VERSION "created by canmatrix"

NS_ :

BS_:

BU_: RadarFrontCenter DASy MPC3

BO_ 250 VFC_TrafficSign12: 48 MPC3
 SG_ VFC_TS12_CRC : 0|16@1+ (1,0) [0|65535] ""  DASy
 SG_ VFC_TS12_AliveCtr : 16|8@1+ (1,0) [0|255] ""  DASy
 SG_ VFC_TS12_ProtBlockCtr : 24|4@1+ (1,0) [0|15] ""  DASy
 SG_ VFC_TS12_ProtOrderIndex : 32|4@1+ (1,0) [0|15] ""  DASy
 SG_ VFC_TS12_ID : 40|8@1+ (1,0) [1|255] ""  DASy
 SG_ VFC_TS12_Class : 48|8@1+ (1,0) [0|206] ""  DASy
 SG_ VFC_TS12_TSProb : 56|6@1+ (2,0) [0|100] "%"  DASy
 SG_ VFC_TS12_Dx : 64|9@1+ (0.2,0) [0|102.2] "m"  DASy
 SG_ VFC_TS12_Dy : 80|8@1+ (0.2,-25.6) [-25.6|25.4] "m"  DASy
 SG_ VFC_TS12_Dz : 88|6@1+ (0.2,0) [0|12.6] "m"  DASy
 SG_ VFC_TS12_DxStdDev : 96|8@1+ (0.25,0) [0|63.75] "m"  DASy
 SG_ VFC_TS12_DyStdDev : 104|7@1+ (0.1,0) [0|12.7] "m"  DASy
 SG_ VFC_TS12_DzStdDev : 112|6@1+ (0.1,0) [0|6.3] "m"  DASy
 SG_ VFC_TS12_Width : 120|7@1+ (0.1,0) [0|12.7] "m"  DASy
 SG_ VFC_TS12_Height : 128|6@1+ (0.1,0) [0|6.3] "m"  DASy
 SG_ VFC_TS12_EmbedFlag : 136|3@1+ (1,0) [0|7] ""  DASy
 SG_ VFC_TS12_Quality : 139|1@1+ (1,0) [0|1] ""  DASy
 SG_ VFC_TS12_VMS : 140|1@1+ (1,0) [0|1] ""  DASy
 SG_ VFC_TS12_Stable : 141|1@1+ (1,0) [0|1] ""  DASy
 SG_ VFC_TS12_VehicleSticker : 142|1@1+ (1,0) [0|1] ""  DASy
 SG_ VFC_TS12_InternalTrack : 143|1@1+ (1,0) [0|1] ""  DASy
 SG_ VFC_TS12_ValidLanes : 144|5@1+ (1,0) [0|31] ""  DASy
 SG_ VFC_TS12_ValidDay : 152|7@1+ (1,0) [0|127] ""  DASy
 SG_ VFC_TS12_ValidTimeRange1Start : 160|7@1+ (15,0) [0|1440] "min"  DASy
 SG_ VFC_TS12_ValidTimeRange1End : 168|7@1+ (15,0) [0|1440] "min"  DASy
 SG_ VFC_TS12_ValidTimeRange2Start : 176|7@1+ (15,0) [0|1440] "min"  DASy
 SG_ VFC_TS12_ValidTimeRange2End : 184|7@1+ (15,0) [0|1440] "min"  DASy
 SG_ VFC_TS12_ValidInDist : 192|10@1+ (10,0) [0|10230] "m"  DASy
 SG_ VFC_TS12_ValidDist : 208|10@1+ (10,0) [0|10230] "m"  DASy
 SG_ VFC_TS12_AddTSCount : 232|3@1+ (1,0) [0|6] ""  DASy
 SG_ VFC_TS12_AddTS1Class : 240|8@1+ (1,0) [0|68] ""  DASy
 SG_ VFC_TS12_AddTS1Prob : 248|6@1+ (2,0) [0|100] "%"  DASy
 SG_ VFC_TS12_AddTS1Quality : 254|1@1+ (1,0) [0|1] ""  DASy
 SG_ VFC_TS12_AddTS1VMS : 255|1@1+ (1,0) [0|1] ""  DASy
 SG_ VFC_TS12_AddTS2Class : 256|8@1+ (1,0) [0|68] ""  DASy
 SG_ VFC_TS12_AddTS2Prob : 264|6@1+ (2,0) [0|100] "%"  DASy
 SG_ VFC_TS12_AddTS2Quality : 270|1@1+ (1,0) [0|1] ""  DASy
 SG_ VFC_TS12_AddTS2VMS : 271|1@1+ (1,0) [0|1] ""  DASy
 SG_ VFC_TS12_AddTS3Class : 272|8@1+ (1,0) [0|68] ""  DASy
 SG_ VFC_TS12_AddTS3Prob : 280|6@1+ (2,0) [0|100] "%"  DASy
 SG_ VFC_TS12_AddTS3Quality : 286|1@1+ (1,0) [0|1] ""  DASy
 SG_ VFC_TS12_AddTS3VMS : 287|1@1+ (1,0) [0|1] ""  DASy
 SG_ VFC_TS12_AddTS4Class : 288|8@1+ (1,0) [0|68] ""  DASy
 SG_ VFC_TS12_AddTS4Prob : 296|6@1+ (2,0) [0|100] "%"  DASy
 SG_ VFC_TS12_AddTS4Quality : 302|1@1+ (1,0) [0|1] ""  DASy
 SG_ VFC_TS12_AddTS4VMS : 303|1@1+ (1,0) [0|1] ""  DASy
 SG_ VFC_TS12_AddTS5Class : 304|8@1+ (1,0) [0|68] ""  DASy
 SG_ VFC_TS12_AddTS5Prob : 312|6@1+ (2,0) [0|100] "%"  DASy
 SG_ VFC_TS12_AddTS5Quality : 318|1@1+ (1,0) [0|1] ""  DASy
 SG_ VFC_TS12_AddTS5VMS : 319|1@1+ (1,0) [0|1] ""  DASy
 SG_ VFC_TS12_AddTS6Class : 320|8@1+ (1,0) [0|68] ""  DASy
 SG_ VFC_TS12_AddTS6Prob : 328|6@1+ (2,0) [0|100] "%"  DASy
 SG_ VFC_TS12_AddTS6Quality : 334|1@1+ (1,0) [0|1] ""  DASy
 SG_ VFC_TS12_AddTS6VMS : 335|1@1+ (1,0) [0|1] ""  DASy
 SG_ VFC_TS12_FV : 359|8@0+ (1,0) [0|255] ""  DASy
 SG_ VFC_TS12_MAC : 367|24@0+ (1,0) [0|16777215] ""  DASy

BO_ 251 VFC_TrafficSign13: 48 MPC3
 SG_ VFC_TS13_CRC : 0|16@1+ (1,0) [0|65535] ""  DASy
 SG_ VFC_TS13_AliveCtr : 16|8@1+ (1,0) [0|255] ""  DASy
 SG_ VFC_TS13_ProtBlockCtr : 24|4@1+ (1,0) [0|15] ""  DASy
 SG_ VFC_TS13_ProtOrderIndex : 32|4@1+ (1,0) [0|15] ""  DASy
 SG_ VFC_TS13_ID : 40|8@1+ (1,0) [1|255] ""  DASy
 SG_ VFC_TS13_Class : 48|8@1+ (1,0) [0|206] ""  DASy
 SG_ VFC_TS13_TSProb : 56|6@1+ (2,0) [0|100] "%"  DASy
 SG_ VFC_TS13_Dx : 64|9@1+ (0.2,0) [0|102.2] "m"  DASy
 SG_ VFC_TS13_Dy : 80|8@1+ (0.2,-25.6) [-25.6|25.4] "m"  DASy
 SG_ VFC_TS13_Dz : 88|6@1+ (0.2,0) [0|12.6] "m"  DASy
 SG_ VFC_TS13_DxStdDev : 96|8@1+ (0.25,0) [0|63.75] "m"  DASy
 SG_ VFC_TS13_DyStdDev : 104|7@1+ (0.1,0) [0|12.7] "m"  DASy
 SG_ VFC_TS13_DzStdDev : 112|6@1+ (0.1,0) [0|6.3] "m"  DASy
 SG_ VFC_TS13_Width : 120|7@1+ (0.1,0) [0|12.7] "m"  DASy
 SG_ VFC_TS13_Height : 128|6@1+ (0.1,0) [0|6.3] "m"  DASy
 SG_ VFC_TS13_EmbedFlag : 136|3@1+ (1,0) [0|7] ""  DASy
 SG_ VFC_TS13_Quality : 139|1@1+ (1,0) [0|1] ""  DASy
 SG_ VFC_TS13_VMS : 140|1@1+ (1,0) [0|1] ""  DASy
 SG_ VFC_TS13_Stable : 141|1@1+ (1,0) [0|1] ""  DASy
 SG_ VFC_TS13_VehicleSticker : 142|1@1+ (1,0) [0|1] ""  DASy
 SG_ VFC_TS13_InternalTrack : 143|1@1+ (1,0) [0|1] ""  DASy
 SG_ VFC_TS13_ValidLanes : 144|5@1+ (1,0) [0|31] ""  DASy
 SG_ VFC_TS13_ValidDay : 152|7@1+ (1,0) [0|127] ""  DASy
 SG_ VFC_TS13_ValidTimeRange1Start : 160|7@1+ (15,0) [0|1440] "min"  DASy
 SG_ VFC_TS13_ValidTimeRange1End : 168|7@1+ (15,0) [0|1440] "min"  DASy
 SG_ VFC_TS13_ValidTimeRange2Start : 176|7@1+ (15,0) [0|1440] "min"  DASy
 SG_ VFC_TS13_ValidTimeRange2End : 184|7@1+ (15,0) [0|1440] "min"  DASy
 SG_ VFC_TS13_ValidInDist : 192|10@1+ (10,0) [0|10230] "m"  DASy
 SG_ VFC_TS13_ValidDist : 208|10@1+ (10,0) [0|10230] "m"  DASy
 SG_ VFC_TS13_AddTSCount : 232|3@1+ (1,0) [0|6] ""  DASy
 SG_ VFC_TS13_AddTS1Class : 240|8@1+ (1,0) [0|68] ""  DASy
 SG_ VFC_TS13_AddTS1Prob : 248|6@1+ (2,0) [0|100] "%"  DASy
 SG_ VFC_TS13_AddTS1Quality : 254|1@1+ (1,0) [0|1] ""  DASy
 SG_ VFC_TS13_AddTS1VMS : 255|1@1+ (1,0) [0|1] ""  DASy
 SG_ VFC_TS13_AddTS2Class : 256|8@1+ (1,0) [0|68] ""  DASy
 SG_ VFC_TS13_AddTS2Prob : 264|6@1+ (2,0) [0|100] "%"  DASy
 SG_ VFC_TS13_AddTS2Quality : 270|1@1+ (1,0) [0|1] ""  DASy
 SG_ VFC_TS13_AddTS2VMS : 271|1@1+ (1,0) [0|1] ""  DASy
 SG_ VFC_TS13_AddTS3Class : 272|8@1+ (1,0) [0|68] ""  DASy
 SG_ VFC_TS13_AddTS3Prob : 280|6@1+ (2,0) [0|100] "%"  DASy
 SG_ VFC_TS13_AddTS3Quality : 286|1@1+ (1,0) [0|1] ""  DASy
 SG_ VFC_TS13_AddTS3VMS : 287|1@1+ (1,0) [0|1] ""  DASy
 SG_ VFC_TS13_AddTS4Class : 288|8@1+ (1,0) [0|68] ""  DASy
 SG_ VFC_TS13_AddTS4Prob : 296|6@1+ (2,0) [0|100] "%"  DASy
 SG_ VFC_TS13_AddTS4Quality : 302|1@1+ (1,0) [0|1] ""  DASy
 SG_ VFC_TS13_AddTS4VMS : 303|1@1+ (1,0) [0|1] ""  DASy
 SG_ VFC_TS13_AddTS5Class : 304|8@1+ (1,0) [0|68] ""  DASy
 SG_ VFC_TS13_AddTS5Prob : 312|6@1+ (2,0) [0|100] "%"  DASy
 SG_ VFC_TS13_AddTS5Quality : 318|1@1+ (1,0) [0|1] ""  DASy
 SG_ VFC_TS13_AddTS5VMS : 319|1@1+ (1,0) [0|1] ""  DASy
 SG_ VFC_TS13_AddTS6Class : 320|8@1+ (1,0) [0|68] ""  DASy
 SG_ VFC_TS13_AddTS6Prob : 328|6@1+ (2,0) [0|100] "%"  DASy
 SG_ VFC_TS13_AddTS6Quality : 334|1@1+ (1,0) [0|1] ""  DASy
 SG_ VFC_TS13_AddTS6VMS : 335|1@1+ (1,0) [0|1] ""  DASy
 SG_ VFC_TS13_FV : 359|8@0+ (1,0) [0|255] ""  DASy
 SG_ VFC_TS13_MAC : 367|24@0+ (1,0) [0|16777215] ""  DASy

BO_ 252 VFC_TrafficSign14: 48 MPC3
 SG_ VFC_TS14_CRC : 0|16@1+ (1,0) [0|65535] ""  DASy
 SG_ VFC_TS14_AliveCtr : 16|8@1+ (1,0) [0|255] ""  DASy
 SG_ VFC_TS14_ProtBlockCtr : 24|4@1+ (1,0) [0|15] ""  DASy
 SG_ VFC_TS14_ProtOrderIndex : 32|4@1+ (1,0) [0|15] ""  DASy
 SG_ VFC_TS14_ID : 40|8@1+ (1,0) [1|255] ""  DASy
 SG_ VFC_TS14_Class : 48|8@1+ (1,0) [0|206] ""  DASy
 SG_ VFC_TS14_TSProb : 56|6@1+ (2,0) [0|100] "%"  DASy
 SG_ VFC_TS14_Dx : 64|9@1+ (0.2,0) [0|102.2] "m"  DASy
 SG_ VFC_TS14_Dy : 80|8@1+ (0.2,-25.6) [-25.6|25.4] "m"  DASy
 SG_ VFC_TS14_Dz : 88|6@1+ (0.2,0) [0|12.6] "m"  DASy
 SG_ VFC_TS14_DxStdDev : 96|8@1+ (0.25,0) [0|63.75] "m"  DASy
 SG_ VFC_TS14_DyStdDev : 104|7@1+ (0.1,0) [0|12.7] "m"  DASy
 SG_ VFC_TS14_DzStdDev : 112|6@1+ (0.1,0) [0|6.3] "m"  DASy
 SG_ VFC_TS14_Width : 120|7@1+ (0.1,0) [0|12.7] "m"  DASy
 SG_ VFC_TS14_Height : 128|6@1+ (0.1,0) [0|6.3] "m"  DASy
 SG_ VFC_TS14_EmbedFlag : 136|3@1+ (1,0) [0|7] ""  DASy
 SG_ VFC_TS14_Quality : 139|1@1+ (1,0) [0|1] ""  DASy
 SG_ VFC_TS14_VMS : 140|1@1+ (1,0) [0|1] ""  DASy
 SG_ VFC_TS14_Stable : 141|1@1+ (1,0) [0|1] ""  DASy
 SG_ VFC_TS14_VehicleSticker : 142|1@1+ (1,0) [0|1] ""  DASy
 SG_ VFC_TS14_InternalTrack : 143|1@1+ (1,0) [0|1] ""  DASy
 SG_ VFC_TS14_ValidLanes : 144|5@1+ (1,0) [0|31] ""  DASy
 SG_ VFC_TS14_ValidDay : 152|7@1+ (1,0) [0|127] ""  DASy
 SG_ VFC_TS14_ValidTimeRange1Start : 160|7@1+ (15,0) [0|1440] "min"  DASy
 SG_ VFC_TS14_ValidTimeRange1End : 168|7@1+ (15,0) [0|1440] "min"  DASy
 SG_ VFC_TS14_ValidTimeRange2Start : 176|7@1+ (15,0) [0|1440] "min"  DASy
 SG_ VFC_TS14_ValidTimeRange2End : 184|7@1+ (15,0) [0|1440] "min"  DASy
 SG_ VFC_TS14_ValidInDist : 192|10@1+ (10,0) [0|10230] "m"  DASy
 SG_ VFC_TS14_ValidDist : 208|10@1+ (10,0) [0|10230] "m"  DASy
 SG_ VFC_TS14_AddTSCount : 232|3@1+ (1,0) [0|6] ""  DASy
 SG_ VFC_TS14_AddTS1Class : 240|8@1+ (1,0) [0|68] ""  DASy
 SG_ VFC_TS14_AddTS1Prob : 248|6@1+ (2,0) [0|100] "%"  DASy
 SG_ VFC_TS14_AddTS1Quality : 254|1@1+ (1,0) [0|1] ""  DASy
 SG_ VFC_TS14_AddTS1VMS : 255|1@1+ (1,0) [0|1] ""  DASy
 SG_ VFC_TS14_AddTS2Class : 256|8@1+ (1,0) [0|68] ""  DASy
 SG_ VFC_TS14_AddTS2Prob : 264|6@1+ (2,0) [0|100] "%"  DASy
 SG_ VFC_TS14_AddTS2Quality : 270|1@1+ (1,0) [0|1] ""  DASy
 SG_ VFC_TS14_AddTS2VMS : 271|1@1+ (1,0) [0|1] ""  DASy
 SG_ VFC_TS14_AddTS3Class : 272|8@1+ (1,0) [0|68] ""  DASy
 SG_ VFC_TS14_AddTS3Prob : 280|6@1+ (2,0) [0|100] "%"  DASy
 SG_ VFC_TS14_AddTS3Quality : 286|1@1+ (1,0) [0|1] ""  DASy
 SG_ VFC_TS14_AddTS3VMS : 287|1@1+ (1,0) [0|1] ""  DASy
 SG_ VFC_TS14_AddTS4Class : 288|8@1+ (1,0) [0|68] ""  DASy
 SG_ VFC_TS14_AddTS4Prob : 296|6@1+ (2,0) [0|100] "%"  DASy
 SG_ VFC_TS14_AddTS4Quality : 302|1@1+ (1,0) [0|1] ""  DASy
 SG_ VFC_TS14_AddTS4VMS : 303|1@1+ (1,0) [0|1] ""  DASy
 SG_ VFC_TS14_AddTS5Class : 304|8@1+ (1,0) [0|68] ""  DASy
 SG_ VFC_TS14_AddTS5Prob : 312|6@1+ (2,0) [0|100] "%"  DASy
 SG_ VFC_TS14_AddTS5Quality : 318|1@1+ (1,0) [0|1] ""  DASy
 SG_ VFC_TS14_AddTS5VMS : 319|1@1+ (1,0) [0|1] ""  DASy
 SG_ VFC_TS14_AddTS6Class : 320|8@1+ (1,0) [0|68] ""  DASy
 SG_ VFC_TS14_AddTS6Prob : 328|6@1+ (2,0) [0|100] "%"  DASy
 SG_ VFC_TS14_AddTS6Quality : 334|1@1+ (1,0) [0|1] ""  DASy
 SG_ VFC_TS14_AddTS6VMS : 335|1@1+ (1,0) [0|1] ""  DASy
 SG_ VFC_TS14_FV : 359|8@0+ (1,0) [0|255] ""  DASy
 SG_ VFC_TS14_MAC : 367|24@0+ (1,0) [0|16777215] ""  DASy

BO_ 253 VFC_TrafficSign15: 48 MPC3
 SG_ VFC_TS15_CRC : 0|16@1+ (1,0) [0|65535] ""  DASy
 SG_ VFC_TS15_AliveCtr : 16|8@1+ (1,0) [0|255] ""  DASy
 SG_ VFC_TS15_ProtBlockCtr : 24|4@1+ (1,0) [0|15] ""  DASy
 SG_ VFC_TS15_ProtOrderIndex : 32|4@1+ (1,0) [0|15] ""  DASy
 SG_ VFC_TS15_ID : 40|8@1+ (1,0) [1|255] ""  DASy
 SG_ VFC_TS15_Class : 48|8@1+ (1,0) [0|206] ""  DASy
 SG_ VFC_TS15_TSProb : 56|6@1+ (2,0) [0|100] "%"  DASy
 SG_ VFC_TS15_Dx : 64|9@1+ (0.2,0) [0|102.2] "m"  DASy
 SG_ VFC_TS15_Dy : 80|8@1+ (0.2,-25.6) [-25.6|25.4] "m"  DASy
 SG_ VFC_TS15_Dz : 88|6@1+ (0.2,0) [0|12.6] "m"  DASy
 SG_ VFC_TS15_DxStdDev : 96|8@1+ (0.25,0) [0|63.75] "m"  DASy
 SG_ VFC_TS15_DyStdDev : 104|7@1+ (0.1,0) [0|12.7] "m"  DASy
 SG_ VFC_TS15_DzStdDev : 112|6@1+ (0.1,0) [0|6.3] "m"  DASy
 SG_ VFC_TS15_Width : 120|7@1+ (0.1,0) [0|12.7] "m"  DASy
 SG_ VFC_TS15_Height : 128|6@1+ (0.1,0) [0|6.3] "m"  DASy
 SG_ VFC_TS15_EmbedFlag : 136|3@1+ (1,0) [0|7] ""  DASy
 SG_ VFC_TS15_Quality : 139|1@1+ (1,0) [0|1] ""  DASy
 SG_ VFC_TS15_VMS : 140|1@1+ (1,0) [0|1] ""  DASy
 SG_ VFC_TS15_Stable : 141|1@1+ (1,0) [0|1] ""  DASy
 SG_ VFC_TS15_VehicleSticker : 142|1@1+ (1,0) [0|1] ""  DASy
 SG_ VFC_TS15_InternalTrack : 143|1@1+ (1,0) [0|1] ""  DASy
 SG_ VFC_TS15_ValidLanes : 144|5@1+ (1,0) [0|31] ""  DASy
 SG_ VFC_TS15_ValidDay : 152|7@1+ (1,0) [0|127] ""  DASy
 SG_ VFC_TS15_ValidTimeRange1Start : 160|7@1+ (15,0) [0|1440] "min"  DASy
 SG_ VFC_TS15_ValidTimeRange1End : 168|7@1+ (15,0) [0|1440] "min"  DASy
 SG_ VFC_TS15_ValidTimeRange2Start : 176|7@1+ (15,0) [0|1440] "min"  DASy
 SG_ VFC_TS15_ValidTimeRange2End : 184|7@1+ (15,0) [0|1440] "min"  DASy
 SG_ VFC_TS15_ValidInDist : 192|10@1+ (10,0) [0|10230] "m"  DASy
 SG_ VFC_TS15_ValidDist : 208|10@1+ (10,0) [0|10230] "m"  DASy
 SG_ VFC_TS15_AddTSCount : 232|3@1+ (1,0) [0|6] ""  DASy
 SG_ VFC_TS15_AddTS1Class : 240|8@1+ (1,0) [0|68] ""  DASy
 SG_ VFC_TS15_AddTS1Prob : 248|6@1+ (2,0) [0|100] "%"  DASy
 SG_ VFC_TS15_AddTS1Quality : 254|1@1+ (1,0) [0|1] ""  DASy
 SG_ VFC_TS15_AddTS1VMS : 255|1@1+ (1,0) [0|1] ""  DASy
 SG_ VFC_TS15_AddTS2Class : 256|8@1+ (1,0) [0|68] ""  DASy
 SG_ VFC_TS15_AddTS2Prob : 264|6@1+ (2,0) [0|100] "%"  DASy
 SG_ VFC_TS15_AddTS2Quality : 270|1@1+ (1,0) [0|1] ""  DASy
 SG_ VFC_TS15_AddTS2VMS : 271|1@1+ (1,0) [0|1] ""  DASy
 SG_ VFC_TS15_AddTS3Class : 272|8@1+ (1,0) [0|68] ""  DASy
 SG_ VFC_TS15_AddTS3Prob : 280|6@1+ (2,0) [0|100] "%"  DASy
 SG_ VFC_TS15_AddTS3Quality : 286|1@1+ (1,0) [0|1] ""  DASy
 SG_ VFC_TS15_AddTS3VMS : 287|1@1+ (1,0) [0|1] ""  DASy
 SG_ VFC_TS15_AddTS4Class : 288|8@1+ (1,0) [0|68] ""  DASy
 SG_ VFC_TS15_AddTS4Prob : 296|6@1+ (2,0) [0|100] "%"  DASy
 SG_ VFC_TS15_AddTS4Quality : 302|1@1+ (1,0) [0|1] ""  DASy
 SG_ VFC_TS15_AddTS4VMS : 303|1@1+ (1,0) [0|1] ""  DASy
 SG_ VFC_TS15_AddTS5Class : 304|8@1+ (1,0) [0|68] ""  DASy
 SG_ VFC_TS15_AddTS5Prob : 312|6@1+ (2,0) [0|100] "%"  DASy
 SG_ VFC_TS15_AddTS5Quality : 318|1@1+ (1,0) [0|1] ""  DASy
 SG_ VFC_TS15_AddTS5VMS : 319|1@1+ (1,0) [0|1] ""  DASy
 SG_ VFC_TS15_AddTS6Class : 320|8@1+ (1,0) [0|68] ""  DASy
 SG_ VFC_TS15_AddTS6Prob : 328|6@1+ (2,0) [0|100] "%"  DASy
 SG_ VFC_TS15_AddTS6Quality : 334|1@1+ (1,0) [0|1] ""  DASy
 SG_ VFC_TS15_AddTS6VMS : 335|1@1+ (1,0) [0|1] ""  DASy
 SG_ VFC_TS15_FV : 359|8@0+ (1,0) [0|255] ""  DASy
 SG_ VFC_TS15_MAC : 367|24@0+ (1,0) [0|16777215] ""  DASy

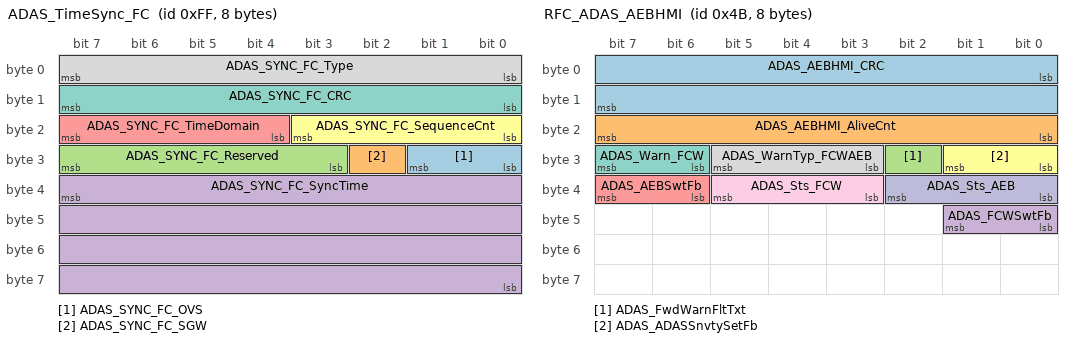
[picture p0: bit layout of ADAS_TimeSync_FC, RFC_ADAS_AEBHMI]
BO_ 255 ADAS_TimeSync_FC: 8 DASy
 SG_ ADAS_SYNC_FC_OVS : 24|2@1+ (1,0) [0|3] ""  MPC3,RadarFrontCenter
 SG_ ADAS_SYNC_FC_SGW : 26|1@1+ (1,0) [0|1] ""  MPC3,RadarFrontCenter
 SG_ ADAS_SYNC_FC_Reserved : 27|5@1+ (1,0) [0|31] ""  MPC3,RadarFrontCenter
 SG_ ADAS_SYNC_FC_SyncTime : 39|32@0+ (1,0) [0|4294967295] ""  MPC3,RadarFrontCenter
 SG_ ADAS_SYNC_FC_TimeDomain : 20|4@1+ (1,0) [0|15] ""  MPC3,RadarFrontCenter
 SG_ ADAS_SYNC_FC_SequenceCnt : 16|4@1+ (1,0) [0|15] ""  MPC3,RadarFrontCenter
 SG_ ADAS_SYNC_FC_CRC : 8|8@1+ (1,0) [0|0] ""  MPC3,RadarFrontCenter
 SG_ ADAS_SYNC_FC_Type : 0|8@1+ (1,0) [0|255] ""  MPC3,RadarFrontCenter

BO_ 75 RFC_ADAS_AEBHMI: 8 RadarFrontCenter
 SG_ ADAS_AEBHMI_CRC : 0|16@1+ (1,0) [0|65535] ""  DASy
 SG_ ADAS_AEBHMI_AliveCnt : 16|8@1+ (1,0) [0|255] ""  DASy
 SG_ ADAS_FwdWarnFltTxt : 26|1@1+ (1,0) [0|1] ""  DASy
 SG_ ADAS_FCWSwtFb : 40|2@1+ (1,0) [0|3] ""  DASy
 SG_ ADAS_AEBSwtFb : 38|2@1+ (1,0) [0|3] ""  DASy
 SG_ ADAS_ADASSnvtySetFb : 24|2@1+ (1,0) [0|3] ""  DASy
 SG_ ADAS_Warn_FCW : 30|2@1+ (1,0) [0|3] ""  DASy
 SG_ ADAS_WarnTyp_FCWAEB : 27|3@1+ (1,0) [0|7] ""  DASy
 SG_ ADAS_Sts_FCW : 35|3@1+ (1,0) [0|7] ""  DASy
 SG_ ADAS_Sts_AEB : 32|3@1+ (1,0) [0|7] ""  DASy

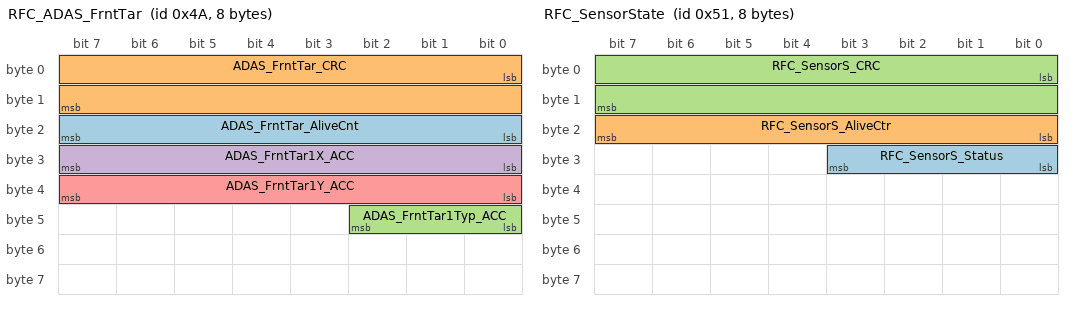
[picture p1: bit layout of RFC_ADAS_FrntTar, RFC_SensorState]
BO_ 74 RFC_ADAS_FrntTar: 8 RadarFrontCenter
 SG_ ADAS_FrntTar_AliveCnt : 16|8@1+ (1,0) [0|255] ""  DASy
 SG_ ADAS_FrntTar_CRC : 0|16@1+ (1,0) [0|65535] ""  DASy
 SG_ ADAS_FrntTar1Typ_ACC : 40|3@1+ (1,0) [0|7] ""  DASy
 SG_ ADAS_FrntTar1X_ACC : 24|8@1+ (1,0) [0|255] ""  DASy
 SG_ ADAS_FrntTar1Y_ACC : 32|8@1+ (0.1,-12.7) [-12.7|12.8] ""  DASy

BO_ 81 RFC_SensorState: 8 RadarFrontCenter
 SG_ RFC_SensorS_Status : 24|4@1+ (1,0) [0|15] ""  DASy
 SG_ RFC_SensorS_AliveCtr : 16|8@1+ (1,0) [0|255] ""  DASy
 SG_ RFC_SensorS_CRC : 0|16@1+ (1,0) [0|65535] ""  DASy

BO_ 2281601536 Dev_Video_SyncVisor_TX: 8 MPC3
 SG_ ImgTimeDelay : 32|32@1+ (1,0) [0|4294967295] ""  RadarFrontCenter,DASy
 SG_ ImgFrameCounter : 0|32@1+ (1,0) [0|4294967295] ""  DASy,RadarFrontCenter

BO_ 931 VFC_MapInfo: 16 MPC3
 SG_ VFC_MapInfo_CountryCode : 118|10@1+ (1,0) [0|1023] ""  RadarFrontCenter,DASy
 SG_ VFC_MapInfo_CurrentLane : 52|3@1+ (1,0) [0|7] ""  RadarFrontCenter,DASy
 SG_ VFC_MapInfo_RoadCurv : 104|12@1+ (2E-005,-0.04094) [-0.04094|0.04096] "1/m"  RadarFrontCenter,DASy
 SG_ VFC_MapInfo_BuildUp_Dx : 88|10@1+ (1,0) [0|1023] "m"  RadarFrontCenter,DASy
 SG_ VFC_MapInfo_BuildUp : 98|2@1+ (1,0) [0|3] ""  RadarFrontCenter,DASy
 SG_ VFC_MapInfo_Bridge_Dx : 72|10@1+ (1,0) [0|1023] "m"  RadarFrontCenter,DASy
 SG_ VFC_MapInfo_Bridge : 82|2@1+ (1,0) [0|3] ""  RadarFrontCenter,DASy
 SG_ VFC_MapInfo_Tunnel : 66|2@1+ (1,0) [0|3] ""  RadarFrontCenter,DASy
 SG_ VFC_MapInfo_Tunnel_Dx : 56|10@1+ (1,0) [0|1023] "m"  RadarFrontCenter,DASy
 SG_ VFC_MapInfo_TollGate : 50|2@1+ (1,0) [0|3] ""  RadarFrontCenter,DASy
 SG_ VFC_MapInfo_TollGate_Dx : 40|10@1+ (1,0) [0|1023] "m"  RadarFrontCenter,DASy
 SG_ VFC_MapInfo_DiRoad_Offset200 : 38|2@1+ (1,0) [0|3] ""  RadarFrontCenter,DASy
 SG_ VFC_MapInfo_LaneNum_Offset200 : 35|3@1+ (1,0) [0|7] ""  RadarFrontCenter,DASy
 SG_ VFC_MapInfo_LaneNum_Offset0 : 32|3@1+ (1,0) [0|7] ""  RadarFrontCenter,DASy
 SG_ VFC_MapInfo_DiRoad_Offset0 : 30|2@1+ (1,0) [0|3] ""  RadarFrontCenter,DASy
 SG_ VFC_MapInfo_RoadClass_Offset200 : 27|3@1+ (1,0) [0|7] ""  RadarFrontCenter,DASy
 SG_ VFC_MapInfo_RoadClass_Offset0 : 24|3@1+ (1,0) [0|7] ""  RadarFrontCenter,DASy
 SG_ VFC_MapInfo_AliveCtr : 16|8@1+ (1,0) [0|255] ""  RadarFrontCenter,DASy
 SG_ VFC_MapInfo_CRC : 0|16@1+ (1,0) [0|65535] ""  RadarFrontCenter,DASy

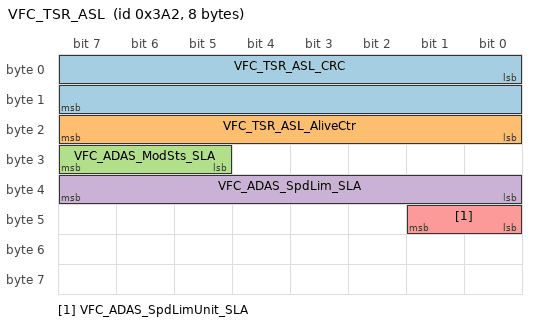
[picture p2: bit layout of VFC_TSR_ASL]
BO_ 930 VFC_TSR_ASL: 8 MPC3
 SG_ VFC_TSR_ASL_CRC : 0|16@1+ (1,0) [0|65535] ""  RadarFrontCenter,DASy
 SG_ VFC_TSR_ASL_AliveCtr : 16|8@1+ (1,0) [0|255] ""  RadarFrontCenter,DASy
 SG_ VFC_ADAS_ModSts_SLA : 29|3@1+ (1,0) [0|7] ""  RadarFrontCenter,DASy
 SG_ VFC_ADAS_SpdLim_SLA : 32|8@1+ (1,0) [0|255] ""  RadarFrontCenter,DASy
 SG_ VFC_ADAS_SpdLimUnit_SLA : 40|2@1+ (1,0) [0|3] ""  RadarFrontCenter,DASy

BO_ 384 RFC_LocationHdr00: 64 RadarFrontCenter
 SG_ RFC_Hdr00_CRC : 0|16@1+ (1,0) [0|65535] ""  DASy
 SG_ RFC_Hdr00_AliveCtr : 16|8@1+ (1,0) [0|255] ""  DASy
 SG_ RFC_Hdr00_ProtBlockCtr : 24|8@1+ (1,0) [0|255] ""  DASy
 SG_ RFC_Hdr00_ProtocolVersion : 32|16@1+ (1,0) [0|65535] ""  DASy
 SG_ RFC_Hdr00_ProtLocationCount : 48|8@1+ (1,0) [0|255] ""  DASy
 SG_ RFC_Hdr00_SensorState : 56|4@1+ (1,0) [0|15] ""  DASy
 SG_ RFC_Hdr00_TimeStamp : 60|26@1+ (1,0) [0|67108863] "ms"  DASy
 SG_ RFC_Hdr00_TimeStampStatus : 488|8@1+ (1,0) [0|255] ""  DASy
 SG_ RFC_Hdr00_LocDownSel : 87|1@1+ (1,0) [0|1] ""  DASy
 SG_ RFC_Hdr00_BliThetaVld : 88|8@1+ (1,0) [0|255] ""  DASy
 SG_ RFC_Hdr00_BliThetaSIMOVld : 96|8@1+ (1,0) [0|255] ""  DASy
 SG_ RFC_Hdr00_BliThetaMIMOVld : 104|8@1+ (1,0) [0|255] ""  DASy
 SG_ RFC_Hdr00_BliThetaSIMOShareVld : 112|8@1+ (1,0) [0|255] ""  DASy
 SG_ RFC_Hdr00_BliThetaMIMOShareVld : 120|8@1+ (1,0) [0|255] ""  DASy
 SG_ RFC_Hdr00_BliPhiVld : 128|8@1+ (1,0) [0|255] ""  DASy
 SG_ RFC_Hdr00_BliRCSMOVld : 136|8@1+ (1,0) [0|255] ""  DASy
 SG_ RFC_Hdr00_BliBinOverThresholdVld : 144|8@1+ (1,0) [0|255] ""  DASy
 SG_ RFC_Hdr00_BliNumValidReflectVld : 152|8@1+ (1,0) [0|255] ""  DASy
 SG_ RFC_Hdr00_BliTheta : 160|32@1- (1,0) [-3.4E+038|3.4E+038] ""  DASy
 SG_ RFC_Hdr00_BliThetaSIMO : 192|32@1- (1,0) [-3.4E+038|3.4E+038] ""  DASy
 SG_ RFC_Hdr00_BliThetaMIMO : 224|32@1- (1,0) [-3.4E+038|3.4E+038] ""  DASy
 SG_ RFC_Hdr00_BliThetaSIMOShare : 256|32@1- (1,0) [-3.4E+038|3.4E+038] ""  DASy
 SG_ RFC_Hdr00_BliThetaMIMOShare : 288|32@1- (1,0) [-3.4E+038|3.4E+038] ""  DASy
 SG_ RFC_Hdr00_BliPhi : 320|32@1- (1,0) [-3.4E+038|3.4E+038] ""  DASy
 SG_ RFC_Hdr00_BliRCSMO : 352|32@1- (1,0) [-3.4E+038|3.4E+038] ""  DASy
 SG_ RFC_Hdr00_BliBinsOverThreshold : 384|32@1- (1,0) [-3.4E+038|3.4E+038] ""  DASy
 SG_ RFC_Hdr00_BliNumValidReflections : 416|32@1- (1,0) [-3.4E+038|3.4E+038] ""  DASy
 SG_ RFC_Hdr00_BliCrossCorrSO : 448|32@1- (1,0) [-3.4E+038|3.4E+038] ""  DASy
 SG_ RFC_Hdr00_BliCrossCorrSOVld : 480|8@1+ (1,0) [0|255] ""  DASy

BO_ 385 RFC_LocationHdr01: 64 RadarFrontCenter
 SG_ RFC_Hdr01_PersVerWriteCnt03 : 56|8@1+ (1,0) [0|255] ""  DASy
 SG_ RFC_Hdr01_PersVerWriteCnt02 : 48|8@1+ (1,0) [0|255] ""  DASy
 SG_ RFC_Hdr01_PersVerWriteCnt01 : 40|8@1+ (1,0) [0|255] ""  DASy
 SG_ RFC_Hdr01_CRC : 0|16@1+ (1,0) [0|65535] ""  DASy
 SG_ RFC_Hdr01_AliveCtr : 16|8@1+ (1,0) [0|255] ""  DASy
 SG_ RFC_Hdr01_ProtBlockCtr : 24|8@1+ (1,0) [0|255] ""  DASy
 SG_ RFC_Hdr01_PersVerWriteCnt00 : 32|8@1+ (1,0) [0|255] ""  DASy
 SG_ RFC_Hdr01_PersAngIndAzi : 64|32@1- (1,0) [-3.4E+038|3.4E+038] "rad"  DASy
 SG_ RFC_Hdr01_PersAngIndElev : 96|32@1- (1,0) [-3.4E+038|3.4E+038] "rad"  DASy
 SG_ RFC_Hdr01_PersAngIndAziMean : 128|32@1- (1,0) [-3.4E+038|3.4E+038] "rad"  DASy
 SG_ RFC_Hdr01_PersAngIndElevMean : 160|32@1- (1,0) [-3.4E+038|3.4E+038] "rad"  DASy
 SG_ RFC_Hdr01_PersAngIndAziVnce : 192|32@1- (1,0) [-3.4E+038|3.4E+038] "rad^2"  DASy
 SG_ RFC_Hdr01_PersAngIndElevVnce : 224|32@1- (1,0) [-3.4E+038|3.4E+038] "rad^2"  DASy
 SG_ RFC_Hdr01_PersAngIndAziElevCov : 256|32@1- (1,0) [-3.4E+038|3.4E+038] "rad^2"  DASy
 SG_ RFC_Hdr01_PersAngCurrAzi : 288|32@1- (1,0) [-3.4E+038|3.4E+038] "rad"  DASy
 SG_ RFC_Hdr01_PersAngCurrElev : 320|32@1- (1,0) [-3.4E+038|3.4E+038] "rad"  DASy
 SG_ RFC_Hdr01_PersAngCurrAziMean : 352|32@1- (1,0) [-3.4E+038|3.4E+038] "rad"  DASy
 SG_ RFC_Hdr01_PersAngCurrElevMean : 384|32@1- (1,0) [-3.4E+038|3.4E+038] "rad"  DASy
 SG_ RFC_Hdr01_PersAngCurrAziVnce : 416|32@1- (1,0) [-3.4E+038|3.4E+038] "rad^2"  DASy
 SG_ RFC_Hdr01_PersAngCurrElevVnce : 448|32@1- (1,0) [-3.4E+038|3.4E+038] "rad^2"  DASy
 SG_ RFC_Hdr01_PersAngCurrAziElevCov : 480|32@1- (1,0) [-3.4E+038|3.4E+038] "rad^2"  DASy

BO_ 386 RFC_LocationHdr02: 64 RadarFrontCenter
 SG_ RFC_Hdr02_ModPerfDMax : 496|16@1+ (0.0078125,0) [0|511.9921875] "m"  DASy
 SG_ RFC_Hdr02_CRC : 0|16@1+ (1,0) [0|65535] ""  DASy
 SG_ RFC_Hdr02_AliveCtr : 16|8@1+ (1,0) [0|255] ""  DASy
 SG_ RFC_Hdr02_ProtBlockCtr : 24|8@1+ (1,0) [0|255] ""  DASy
 SG_ RFC_Hdr02_PersFiltDspMalIndAzi : 32|32@1- (1,0) [-3.4E+038|3.4E+038] ""  DASy
 SG_ RFC_Hdr02_PersFiltWeightIndAzi : 64|32@1- (1,0) [-3.4E+038|3.4E+038] ""  DASy
 SG_ RFC_Hdr02_PersFiltDspCurrAzi : 96|32@1- (1,0) [-3.4E+038|3.4E+038] ""  DASy
 SG_ RFC_Hdr02_PersFiltDspMalIndElev : 128|32@1- (1,0) [-3.4E+038|3.4E+038] ""  DASy
 SG_ RFC_Hdr02_PersFiltWeightIndElev : 160|32@1- (1,0) [-3.4E+038|3.4E+038] ""  DASy
 SG_ RFC_Hdr02_PersFiltDspCurrElev : 192|32@1- (1,0) [-3.4E+038|3.4E+038] ""  DASy
 SG_ RFC_Hdr02_PersMalStablePosAzi : 224|32@1- (1,0) [-3.4E+038|3.4E+038] "rad"  DASy
 SG_ RFC_Hdr02_PersMalStablePosElev : 256|32@1- (1,0) [-3.4E+038|3.4E+038] "rad"  DASy
 SG_ RFC_Hdr02_PersChDetPozAzi : 288|32@1- (1,0) [-3.4E+038|3.4E+038] "rad"  DASy
 SG_ RFC_Hdr02_PersChDetNegAzi : 320|32@1- (1,0) [-3.4E+038|3.4E+038] "rad"  DASy
 SG_ RFC_Hdr02_PersChDetPozElev : 352|32@1- (1,0) [-3.4E+038|3.4E+038] "rad"  DASy
 SG_ RFC_Hdr02_PersChDetNegElev : 384|32@1- (1,0) [-3.4E+038|3.4E+038] "rad"  DASy
 SG_ RFC_Hdr02_MntAziCur : 416|32@1- (1,0) [-3.4E+038|3.4E+038] "deg"  DASy
 SG_ RFC_Hdr02_MntElevCur : 448|32@1- (1,0) [-3.4E+038|3.4E+038] "deg"  DASy
 SG_ RFC_Hdr02_PersOutOfSpecAzi : 480|1@1+ (1,0) [0|1] ""  DASy
 SG_ RFC_Hdr02_PersOutOfSpecElev : 481|1@1+ (1,0) [0|1] ""  DASy

BO_ 387 RFC_LocationHdr03: 64 RadarFrontCenter
 SG_ RFC_Hdr03_CRC : 0|16@1+ (1,0) [0|65535] ""  DASy
 SG_ RFC_Hdr03_AliveCtr : 16|8@1+ (1,0) [0|255] ""  DASy
 SG_ RFC_Hdr03_ProtBlockCtr : 24|8@1+ (1,0) [0|255] ""  DASy
 SG_ RFC_Hdr03_FoVdMaxTheta00 : 32|9@1+ (1,0) [0|511] "m"  DASy
 SG_ RFC_Hdr03_FoVdMaxTheta01 : 41|9@1+ (1,0) [0|511] "m"  DASy
 SG_ RFC_Hdr03_FoVdMaxTheta02 : 50|9@1+ (1,0) [0|511] "m"  DASy
 SG_ RFC_Hdr03_FoVdMaxTheta03 : 59|9@1+ (1,0) [0|511] "m"  DASy
 SG_ RFC_Hdr03_FoVdMaxTheta04 : 68|9@1+ (1,0) [0|511] "m"  DASy
 SG_ RFC_Hdr03_FoVdMaxTheta05 : 77|9@1+ (1,0) [0|511] "m"  DASy
 SG_ RFC_Hdr03_FoVdMaxTheta06 : 86|9@1+ (1,0) [0|511] "m"  DASy
 SG_ RFC_Hdr03_FoVdMaxTheta07 : 95|9@1+ (1,0) [0|511] "m"  DASy
 SG_ RFC_Hdr03_FoVdMaxTheta08 : 104|9@1+ (1,0) [0|511] "m"  DASy
 SG_ RFC_Hdr03_FoVdMaxTheta09 : 113|9@1+ (1,0) [0|511] "m"  DASy
 SG_ RFC_Hdr03_FoVdMaxTheta10 : 122|9@1+ (1,0) [0|511] "m"  DASy
 SG_ RFC_Hdr03_FoVdMaxTheta11 : 131|9@1+ (1,0) [0|511] "m"  DASy
 SG_ RFC_Hdr03_FoVdMaxTheta12 : 140|9@1+ (1,0) [0|511] "m"  DASy
 SG_ RFC_Hdr03_FoVdMaxTheta13 : 149|9@1+ (1,0) [0|511] "m"  DASy
 SG_ RFC_Hdr03_FoVdMaxTheta14 : 158|9@1+ (1,0) [0|511] "m"  DASy
 SG_ RFC_Hdr03_FoVdMaxTheta15 : 167|9@1+ (1,0) [0|511] "m"  DASy
 SG_ RFC_Hdr03_FoVdMaxTheta16 : 176|9@1+ (1,0) [0|511] "m"  DASy
 SG_ RFC_Hdr03_FoVdMaxTheta17 : 185|9@1+ (1,0) [0|511] "m"  DASy
 SG_ RFC_Hdr03_FoVdMaxTheta18 : 194|9@1+ (1,0) [0|511] "m"  DASy
 SG_ RFC_Hdr03_FoVdMaxTheta19 : 203|9@1+ (1,0) [0|511] "m"  DASy
 SG_ RFC_Hdr03_FoVdMaxTheta20 : 212|9@1+ (1,0) [0|511] "m"  DASy
 SG_ RFC_Hdr03_FoVdMaxTheta21 : 221|9@1+ (1,0) [0|511] "m"  DASy
 SG_ RFC_Hdr03_FoVdMaxTheta22 : 230|9@1+ (1,0) [0|511] "m"  DASy
 SG_ RFC_Hdr03_FoVdMaxTheta23 : 239|9@1+ (1,0) [0|511] "m"  DASy
 SG_ RFC_Hdr03_FoVdMaxTheta24 : 248|9@1+ (1,0) [0|511] "m"  DASy
 SG_ RFC_Hdr03_FoVdMaxPhi00 : 257|7@1+ (0.01,0) [0|1] "-"  DASy
 SG_ RFC_Hdr03_FoVTheta00 : 264|8@1+ (1,-90) [-90|90] "deg"  DASy
 SG_ RFC_Hdr03_FoVTheta01 : 272|8@1+ (1,-90) [-90|90] "deg"  DASy
 SG_ RFC_Hdr03_FoVTheta02 : 280|8@1+ (1,-90) [-90|90] "deg"  DASy
 SG_ RFC_Hdr03_FoVTheta03 : 288|8@1+ (1,-90) [-90|90] "deg"  DASy
 SG_ RFC_Hdr03_FoVTheta04 : 296|8@1+ (1,-90) [-90|90] "deg"  DASy
 SG_ RFC_Hdr03_FoVTheta05 : 304|8@1+ (1,-90) [-90|90] "deg"  DASy
 SG_ RFC_Hdr03_FoVTheta06 : 312|8@1+ (1,-90) [-90|90] "deg"  DASy
 SG_ RFC_Hdr03_FoVTheta07 : 320|8@1+ (1,-90) [-90|90] "deg"  DASy
 SG_ RFC_Hdr03_FoVTheta08 : 328|8@1+ (1,-90) [-90|90] "deg"  DASy
 SG_ RFC_Hdr03_FoVTheta09 : 336|8@1+ (1,-90) [-90|90] "deg"  DASy
 SG_ RFC_Hdr03_FoVTheta10 : 344|8@1+ (1,-90) [-90|90] "deg"  DASy
 SG_ RFC_Hdr03_FoVTheta11 : 352|8@1+ (1,-90) [-90|90] "deg"  DASy
 SG_ RFC_Hdr03_FoVTheta12 : 360|8@1+ (1,-90) [-90|90] "deg"  DASy
 SG_ RFC_Hdr03_FoVTheta13 : 368|8@1+ (1,-90) [-90|90] "deg"  DASy
 SG_ RFC_Hdr03_FoVTheta14 : 376|8@1+ (1,-90) [-90|90] "deg"  DASy
 SG_ RFC_Hdr03_FoVTheta15 : 384|8@1+ (1,-90) [-90|90] "deg"  DASy
 SG_ RFC_Hdr03_FoVTheta16 : 392|8@1+ (1,-90) [-90|90] "deg"  DASy
 SG_ RFC_Hdr03_FoVTheta17 : 400|8@1+ (1,-90) [-90|90] "deg"  DASy
 SG_ RFC_Hdr03_FoVTheta18 : 408|8@1+ (1,-90) [-90|90] "deg"  DASy
 SG_ RFC_Hdr03_FoVTheta19 : 416|8@1+ (1,-90) [-90|90] "deg"  DASy
 SG_ RFC_Hdr03_FoVTheta20 : 424|8@1+ (1,-90) [-90|90] "deg"  DASy
 SG_ RFC_Hdr03_FoVTheta21 : 432|8@1+ (1,-90) [-90|90] "deg"  DASy
 SG_ RFC_Hdr03_FoVTheta22 : 440|8@1+ (1,-90) [-90|90] "deg"  DASy
 SG_ RFC_Hdr03_FoVTheta23 : 448|8@1+ (1,-90) [-90|90] "deg"  DASy
 SG_ RFC_Hdr03_FoVTheta24 : 456|8@1+ (1,-90) [-90|90] "deg"  DASy
 SG_ RFC_Hdr03_FoVdMaxPhi01 : 464|7@1+ (0.01,0) [0|1] "-"  DASy
 SG_ RFC_Hdr03_FoVdMaxPhi02 : 471|7@1+ (0.01,0) [0|1] "-"  DASy
 SG_ RFC_Hdr03_FoVdMaxPhi03 : 478|7@1+ (0.01,0) [0|1] "-"  DASy
 SG_ RFC_Hdr03_FoVdMaxPhi04 : 485|7@1+ (0.01,0) [0|1] "-"  DASy
 SG_ RFC_Hdr03_FoVdMaxPhi05 : 492|7@1+ (0.01,0) [0|1] "-"  DASy
 SG_ RFC_Hdr03_FoVdMaxPhi06 : 499|7@1+ (0.01,0) [0|1] "-"  DASy

BO_ 388 RFC_LocationHdr04: 64 RadarFrontCenter
 SG_ RFC_Hdr04_CRC : 0|16@1+ (1,0) [0|65535] ""  DASy
 SG_ RFC_Hdr04_AliveCtr : 16|8@1+ (1,0) [0|255] ""  DASy
 SG_ RFC_Hdr04_ProtBlockCtr : 24|8@1+ (1,0) [0|255] ""  DASy
 SG_ RFC_Hdr04_FoVdMaxPhi07 : 32|7@1+ (0.01,0) [0|1] "-"  DASy
 SG_ RFC_Hdr04_FoVdMaxPhi08 : 39|7@1+ (0.01,0) [0|1] "-"  DASy
 SG_ RFC_Hdr04_FoVdMaxPhi09 : 46|7@1+ (0.01,0) [0|1] "-"  DASy
 SG_ RFC_Hdr04_FoVdMaxPhi10 : 53|7@1+ (0.01,0) [0|1] "-"  DASy
 SG_ RFC_Hdr04_FoVPhi00 : 60|6@1+ (1,-30) [-30|30] "deg"  DASy
 SG_ RFC_Hdr04_FoVPhi01 : 66|6@1+ (1,-30) [-30|30] "deg"  DASy
 SG_ RFC_Hdr04_FoVPhi02 : 72|6@1+ (1,-30) [-30|30] "deg"  DASy
 SG_ RFC_Hdr04_FoVPhi03 : 78|6@1+ (1,-30) [-30|30] "deg"  DASy
 SG_ RFC_Hdr04_FoVPhi04 : 84|6@1+ (1,-30) [-30|30] "deg"  DASy
 SG_ RFC_Hdr04_FoVPhi05 : 90|6@1+ (1,-30) [-30|30] "deg"  DASy
 SG_ RFC_Hdr04_FoVPhi06 : 96|6@1+ (1,-30) [-30|30] "deg"  DASy
 SG_ RFC_Hdr04_FoVPhi07 : 102|6@1+ (1,-30) [-30|30] "deg"  DASy
 SG_ RFC_Hdr04_FoVPhi08 : 108|6@1+ (1,-30) [-30|30] "deg"  DASy
 SG_ RFC_Hdr04_FoVPhi09 : 114|6@1+ (1,-30) [-30|30] "deg"  DASy
 SG_ RFC_Hdr04_FoVPhi10 : 120|6@1+ (1,-30) [-30|30] "deg"  DASy
 SG_ RFC_Hdr04_MntPosX : 128|32@1- (1,0) [-3.4E+038|3.4E+038] "m"  DASy
 SG_ RFC_Hdr04_MntPosY : 160|32@1- (1,0) [-3.4E+038|3.4E+038] "m"  DASy
 SG_ RFC_Hdr04_MntPosZ : 192|32@1- (1,0) [-3.4E+038|3.4E+038] "m"  DASy
 SG_ RFC_Hdr04_MntAziNom : 224|32@1- (1,0) [-3.4E+038|3.4E+038] "deg"  DASy
 SG_ RFC_Hdr04_MntElevNom : 256|32@1- (1,0) [-3.4E+038|3.4E+038] "deg"  DASy
 SG_ RFC_Hdr04_InitCov : 288|32@1- (1,0) [-3.4E+038|3.4E+038] "-"  DASy
 SG_ RFC_Hdr04_TspMeasID : 320|32@1+ (1,0) [0|4294967295] "-"  DASy
 SG_ RFC_Hdr04_TspSensID : 352|32@1+ (1,0) [0|4294967295] "-"  DASy
 SG_ RFC_Hdr04_TspLastMeas : 384|32@1+ (1,0) [0|4294967295] "-"  DASy
 SG_ RFC_Hdr04_TspLastRec : 416|32@1+ (1,0) [0|4294967295] "-"  DASy
 SG_ RFC_Hdr04_TspPredMeas : 448|32@1+ (1,0) [0|4294967295] "-"  DASy
 SG_ RFC_Hdr04_TspPredRec : 480|32@1+ (1,0) [0|4294967295] "-"  DASy

BO_ 400 RFC_Location_000_001: 64 RadarFrontCenter
 SG_ RFC_Loc000_CRC : 0|16@1+ (1,0) [0|65535] ""  DASy
 SG_ RFC_Loc000_AliveCtr : 16|8@1+ (1,0) [0|255] ""  DASy
 SG_ RFC_Loc000_ProtBlockCtr : 24|8@1+ (1,0) [0|255] ""  DASy
 SG_ RFC_Loc000_Dr : 32|16@1+ (0.0078125,0) [0|511.9921875] "m"  DASy
 SG_ RFC_Loc000_Vr : 48|16@1+ (0.00390625,-128) [-128|127.99609375] "m/s"  DASy
 SG_ RFC_Loc000_Theta : 64|16@1+ (0.01,-327.68) [-90|90] "deg"  DASy
 SG_ RFC_Loc000_Phi : 80|16@1+ (0.01,-327.68) [-30|30] "deg"  DASy
 SG_ RFC_Loc000_DrVnce : 96|16@1+ (1.52588E-005,0) [0|0.999984741210937] "m^2"  DASy
 SG_ RFC_Loc000_VrVnce : 112|16@1+ (1.52588E-005,0) [0|0.999984741210937] "m^2/s^2"  DASy
 SG_ RFC_Loc000_ThetaVnce : 128|16@1+ (0.00390625,0) [0|255.99609375] "deg^2"  DASy
 SG_ RFC_Loc000_PhiVnce : 144|16@1+ (0.00390625,0) [0|255.99609375] "deg^2"  DASy
 SG_ RFC_Loc000_DrVrCoVnce : 160|16@1+ (3.814697265625E-006,-0.125) [-0.125|0.124996185302734] "m^2/s"  DASy
 SG_ RFC_Loc000_RCS : 176|16@1+ (0.00390625,-128) [-128|127.99609375] "dBsm"  DASy
 SG_ RFC_Loc000_RSSI : 192|16@1+ (0.00195312,0) [0|127.998046875] "dimensionless"  DASy
 SG_ RFC_Loc000_DrVrQuality : 208|8@1+ (1,0) [0|255] "dimensionless"  DASy
 SG_ RFC_Loc000_ThetaQuality : 216|8@1+ (1,0) [0|255] "dimensionless"  DASy
 SG_ RFC_Loc000_PhiQuality : 224|8@1+ (1,0) [0|255] "dimensionless"  DASy
 SG_ RFC_Loc001_Dr : 256|16@1+ (0.0078125,0) [0|511.9921875] "m"  DASy
 SG_ RFC_Loc001_Vr : 272|16@1+ (0.00390625,-128) [-128|127.99609375] "m/s"  DASy
 SG_ RFC_Loc001_Theta : 288|16@1+ (0.01,-327.68) [-90|90] "deg"  DASy
 SG_ RFC_Loc001_Phi : 304|16@1+ (0.01,-327.68) [-30|30] "deg"  DASy
 SG_ RFC_Loc001_DrVnce : 320|16@1+ (1.52588E-005,0) [0|0.999984741210937] "m^2"  DASy
 SG_ RFC_Loc001_VrVnce : 336|16@1+ (1.52588E-005,0) [0|0.999984741210937] "m^2/s^2"  DASy
 SG_ RFC_Loc001_ThetaVnce : 352|16@1+ (0.00390625,0) [0|255.99609375] "deg^2"  DASy
 SG_ RFC_Loc001_PhiVnce : 368|16@1+ (0.00390625,0) [0|255.99609375] "deg^2"  DASy
 SG_ RFC_Loc001_DrVrCoVnce : 384|16@1+ (3.814697265625E-006,-0.125) [-0.125|0.124996185302734] "m^2/s"  DASy
 SG_ RFC_Loc001_RCS : 400|16@1+ (0.00390625,-128) [-128|127.99609375] "dBsm"  DASy
 SG_ RFC_Loc001_RSSI : 416|16@1+ (0.00195312,0) [0|127.998046875] "dimensionless"  DASy
 SG_ RFC_Loc001_DrVrQuality : 432|8@1+ (1,0) [0|255] "dimensionless"  DASy
 SG_ RFC_Loc001_ThetaQuality : 440|8@1+ (1,0) [0|255] "dimensionless"  DASy
 SG_ RFC_Loc001_PhiQuality : 448|8@1+ (1,0) [0|255] "dimensionless"  DASy

BO_ 401 RFC_Location_002_003: 64 RadarFrontCenter
 SG_ RFC_Loc002_CRC : 0|16@1+ (1,0) [0|65535] ""  DASy
 SG_ RFC_Loc002_AliveCtr : 16|8@1+ (1,0) [0|255] ""  DASy
 SG_ RFC_Loc002_ProtBlockCtr : 24|8@1+ (1,0) [0|255] ""  DASy
 SG_ RFC_Loc002_Dr : 32|16@1+ (0.0078125,0) [0|511.9921875] "m"  DASy
 SG_ RFC_Loc002_Vr : 48|16@1+ (0.00390625,-128) [-128|127.99609375] "m/s"  DASy
 SG_ RFC_Loc002_Theta : 64|16@1+ (0.01,-327.68) [-90|90] "deg"  DASy
 SG_ RFC_Loc002_Phi : 80|16@1+ (0.01,-327.68) [-30|30] "deg"  DASy
 SG_ RFC_Loc002_DrVnce : 96|16@1+ (1.52588E-005,0) [0|0.999984741210937] "m^2"  DASy
 SG_ RFC_Loc002_VrVnce : 112|16@1+ (1.52588E-005,0) [0|0.999984741210937] "m^2/s^2"  DASy
 SG_ RFC_Loc002_ThetaVnce : 128|16@1+ (0.00390625,0) [0|255.99609375] "deg^2"  DASy
 SG_ RFC_Loc002_PhiVnce : 144|16@1+ (0.00390625,0) [0|255.99609375] "deg^2"  DASy
 SG_ RFC_Loc002_DrVrCoVnce : 160|16@1+ (3.814697265625E-006,-0.125) [-0.125|0.124996185302734] "m^2/s"  DASy
 SG_ RFC_Loc002_RCS : 176|16@1+ (0.00390625,-128) [-128|127.99609375] "dBsm"  DASy
 SG_ RFC_Loc002_RSSI : 192|16@1+ (0.00195312,0) [0|127.998046875] "dimensionless"  DASy
 SG_ RFC_Loc002_DrVrQuality : 208|8@1+ (1,0) [0|255] "dimensionless"  DASy
 SG_ RFC_Loc002_ThetaQuality : 216|8@1+ (1,0) [0|255] "dimensionless"  DASy
 SG_ RFC_Loc002_PhiQuality : 224|8@1+ (1,0) [0|255] "dimensionless"  DASy
 SG_ RFC_Loc003_Dr : 256|16@1+ (0.0078125,0) [0|511.9921875] "m"  DASy
 SG_ RFC_Loc003_Vr : 272|16@1+ (0.00390625,-128) [-128|127.99609375] "m/s"  DASy
 SG_ RFC_Loc003_Theta : 288|16@1+ (0.01,-327.68) [-90|90] "deg"  DASy
 SG_ RFC_Loc003_Phi : 304|16@1+ (0.01,-327.68) [-30|30] "deg"  DASy
 SG_ RFC_Loc003_DrVnce : 320|16@1+ (1.52588E-005,0) [0|0.999984741210937] "m^2"  DASy
 SG_ RFC_Loc003_VrVnce : 336|16@1+ (1.52588E-005,0) [0|0.999984741210937] "m^2/s^2"  DASy
 SG_ RFC_Loc003_ThetaVnce : 352|16@1+ (0.00390625,0) [0|255.99609375] "deg^2"  DASy
 SG_ RFC_Loc003_PhiVnce : 368|16@1+ (0.00390625,0) [0|255.99609375] "deg^2"  DASy
 SG_ RFC_Loc003_DrVrCoVnce : 384|16@1+ (3.814697265625E-006,-0.125) [-0.125|0.124996185302734] "m^2/s"  DASy
 SG_ RFC_Loc003_RCS : 400|16@1+ (0.00390625,-128) [-128|127.99609375] "dBsm"  DASy
 SG_ RFC_Loc003_RSSI : 416|16@1+ (0.00195312,0) [0|127.998046875] "dimensionless"  DASy
 SG_ RFC_Loc003_DrVrQuality : 432|8@1+ (1,0) [0|255] "dimensionless"  DASy
 SG_ RFC_Loc003_ThetaQuality : 440|8@1+ (1,0) [0|255] "dimensionless"  DASy
 SG_ RFC_Loc003_PhiQuality : 448|8@1+ (1,0) [0|255] "dimensionless"  DASy

BO_ 402 RFC_Location_004_005: 64 RadarFrontCenter
 SG_ RFC_Loc004_CRC : 0|16@1+ (1,0) [0|65535] ""  DASy
 SG_ RFC_Loc004_AliveCtr : 16|8@1+ (1,0) [0|255] ""  DASy
 SG_ RFC_Loc004_ProtBlockCtr : 24|8@1+ (1,0) [0|255] ""  DASy
 SG_ RFC_Loc004_Dr : 32|16@1+ (0.0078125,0) [0|511.9921875] "m"  DASy
 SG_ RFC_Loc004_Vr : 48|16@1+ (0.00390625,-128) [-128|127.99609375] "m/s"  DASy
 SG_ RFC_Loc004_Theta : 64|16@1+ (0.01,-327.68) [-90|90] "deg"  DASy
 SG_ RFC_Loc004_Phi : 80|16@1+ (0.01,-327.68) [-30|30] "deg"  DASy
 SG_ RFC_Loc004_DrVnce : 96|16@1+ (1.52588E-005,0) [0|0.999984741210937] "m^2"  DASy
 SG_ RFC_Loc004_VrVnce : 112|16@1+ (1.52588E-005,0) [0|0.999984741210937] "m^2/s^2"  DASy
 SG_ RFC_Loc004_ThetaVnce : 128|16@1+ (0.00390625,0) [0|255.99609375] "deg^2"  DASy
 SG_ RFC_Loc004_PhiVnce : 144|16@1+ (0.00390625,0) [0|255.99609375] "deg^2"  DASy
 SG_ RFC_Loc004_DrVrCoVnce : 160|16@1+ (3.814697265625E-006,-0.125) [-0.125|0.124996185302734] "m^2/s"  DASy
 SG_ RFC_Loc004_RCS : 176|16@1+ (0.00390625,-128) [-128|127.99609375] "dBsm"  DASy
 SG_ RFC_Loc004_RSSI : 192|16@1+ (0.00195312,0) [0|127.998046875] "dimensionless"  DASy
 SG_ RFC_Loc004_DrVrQuality : 208|8@1+ (1,0) [0|255] "dimensionless"  DASy
 SG_ RFC_Loc004_ThetaQuality : 216|8@1+ (1,0) [0|255] "dimensionless"  DASy
 SG_ RFC_Loc004_PhiQuality : 224|8@1+ (1,0) [0|255] "dimensionless"  DASy
 SG_ RFC_Loc005_Dr : 256|16@1+ (0.0078125,0) [0|511.9921875] "m"  DASy
 SG_ RFC_Loc005_Vr : 272|16@1+ (0.00390625,-128) [-128|127.99609375] "m/s"  DASy
 SG_ RFC_Loc005_Theta : 288|16@1+ (0.01,-327.68) [-90|90] "deg"  DASy
 SG_ RFC_Loc005_Phi : 304|16@1+ (0.01,-327.68) [-30|30] "deg"  DASy
 SG_ RFC_Loc005_DrVnce : 320|16@1+ (1.52588E-005,0) [0|0.999984741210937] "m^2"  DASy
 SG_ RFC_Loc005_VrVnce : 336|16@1+ (1.52588E-005,0) [0|0.999984741210937] "m^2/s^2"  DASy
 SG_ RFC_Loc005_ThetaVnce : 352|16@1+ (0.00390625,0) [0|255.99609375] "deg^2"  DASy
 SG_ RFC_Loc005_PhiVnce : 368|16@1+ (0.00390625,0) [0|255.99609375] "deg^2"  DASy
 SG_ RFC_Loc005_DrVrCoVnce : 384|16@1+ (3.814697265625E-006,-0.125) [-0.125|0.124996185302734] "m^2/s"  DASy
 SG_ RFC_Loc005_RCS : 400|16@1+ (0.00390625,-128) [-128|127.99609375] "dBsm"  DASy
 SG_ RFC_Loc005_RSSI : 416|16@1+ (0.00195312,0) [0|127.998046875] "dimensionless"  DASy
 SG_ RFC_Loc005_DrVrQuality : 432|8@1+ (1,0) [0|255] "dimensionless"  DASy
 SG_ RFC_Loc005_ThetaQuality : 440|8@1+ (1,0) [0|255] "dimensionless"  DASy
 SG_ RFC_Loc005_PhiQuality : 448|8@1+ (1,0) [0|255] "dimensionless"  DASy

BO_ 403 RFC_Location_006_007: 64 RadarFrontCenter
 SG_ RFC_Loc006_CRC : 0|16@1+ (1,0) [0|65535] ""  DASy
 SG_ RFC_Loc006_AliveCtr : 16|8@1+ (1,0) [0|255] ""  DASy
 SG_ RFC_Loc006_ProtBlockCtr : 24|8@1+ (1,0) [0|255] ""  DASy
 SG_ RFC_Loc006_Dr : 32|16@1+ (0.0078125,0) [0|511.9921875] "m"  DASy
 SG_ RFC_Loc006_Vr : 48|16@1+ (0.00390625,-128) [-128|127.99609375] "m/s"  DASy
 SG_ RFC_Loc006_Theta : 64|16@1+ (0.01,-327.68) [-90|90] "deg"  DASy
 SG_ RFC_Loc006_Phi : 80|16@1+ (0.01,-327.68) [-30|30] "deg"  DASy
 SG_ RFC_Loc006_DrVnce : 96|16@1+ (1.52588E-005,0) [0|0.999984741210937] "m^2"  DASy
 SG_ RFC_Loc006_VrVnce : 112|16@1+ (1.52588E-005,0) [0|0.999984741210937] "m^2/s^2"  DASy
 SG_ RFC_Loc006_ThetaVnce : 128|16@1+ (0.00390625,0) [0|255.99609375] "deg^2"  DASy
 SG_ RFC_Loc006_PhiVnce : 144|16@1+ (0.00390625,0) [0|255.99609375] "deg^2"  DASy
 SG_ RFC_Loc006_DrVrCoVnce : 160|16@1+ (3.814697265625E-006,-0.125) [-0.125|0.124996185302734] "m^2/s"  DASy
 SG_ RFC_Loc006_RCS : 176|16@1+ (0.00390625,-128) [-128|127.99609375] "dBsm"  DASy
 SG_ RFC_Loc006_RSSI : 192|16@1+ (0.00195312,0) [0|127.998046875] "dimensionless"  DASy
 SG_ RFC_Loc006_DrVrQuality : 208|8@1+ (1,0) [0|255] "dimensionless"  DASy
 SG_ RFC_Loc006_ThetaQuality : 216|8@1+ (1,0) [0|255] "dimensionless"  DASy
 SG_ RFC_Loc006_PhiQuality : 224|8@1+ (1,0) [0|255] "dimensionless"  DASy
 SG_ RFC_Loc007_Dr : 256|16@1+ (0.0078125,0) [0|511.9921875] "m"  DASy
 SG_ RFC_Loc007_Vr : 272|16@1+ (0.00390625,-128) [-128|127.99609375] "m/s"  DASy
 SG_ RFC_Loc007_Theta : 288|16@1+ (0.01,-327.68) [-90|90] "deg"  DASy
 SG_ RFC_Loc007_Phi : 304|16@1+ (0.01,-327.68) [-30|30] "deg"  DASy
 SG_ RFC_Loc007_DrVnce : 320|16@1+ (1.52588E-005,0) [0|0.999984741210937] "m^2"  DASy
 SG_ RFC_Loc007_VrVnce : 336|16@1+ (1.52588E-005,0) [0|0.999984741210937] "m^2/s^2"  DASy
 SG_ RFC_Loc007_ThetaVnce : 352|16@1+ (0.00390625,0) [0|255.99609375] "deg^2"  DASy
 SG_ RFC_Loc007_PhiVnce : 368|16@1+ (0.00390625,0) [0|255.99609375] "deg^2"  DASy
 SG_ RFC_Loc007_DrVrCoVnce : 384|16@1+ (3.814697265625E-006,-0.125) [-0.125|0.124996185302734] "m^2/s"  DASy
 SG_ RFC_Loc007_RCS : 400|16@1+ (0.00390625,-128) [-128|127.99609375] "dBsm"  DASy
 SG_ RFC_Loc007_RSSI : 416|16@1+ (0.00195312,0) [0|127.998046875] "dimensionless"  DASy
 SG_ RFC_Loc007_DrVrQuality : 432|8@1+ (1,0) [0|255] "dimensionless"  DASy
 SG_ RFC_Loc007_ThetaQuality : 440|8@1+ (1,0) [0|255] "dimensionless"  DASy
 SG_ RFC_Loc007_PhiQuality : 448|8@1+ (1,0) [0|255] "dimensionless"  DASy

BO_ 404 RFC_Location_008_009: 64 RadarFrontCenter
 SG_ RFC_Loc008_CRC : 0|16@1+ (1,0) [0|65535] ""  DASy
 SG_ RFC_Loc008_AliveCtr : 16|8@1+ (1,0) [0|255] ""  DASy
 SG_ RFC_Loc008_ProtBlockCtr : 24|8@1+ (1,0) [0|255] ""  DASy
 SG_ RFC_Loc008_Dr : 32|16@1+ (0.0078125,0) [0|511.9921875] "m"  DASy
 SG_ RFC_Loc008_Vr : 48|16@1+ (0.00390625,-128) [-128|127.99609375] "m/s"  DASy
 SG_ RFC_Loc008_Theta : 64|16@1+ (0.01,-327.68) [-90|90] "deg"  DASy
 SG_ RFC_Loc008_Phi : 80|16@1+ (0.01,-327.68) [-30|30] "deg"  DASy
 SG_ RFC_Loc008_DrVnce : 96|16@1+ (1.52588E-005,0) [0|0.999984741210937] "m^2"  DASy
 SG_ RFC_Loc008_VrVnce : 112|16@1+ (1.52588E-005,0) [0|0.999984741210937] "m^2/s^2"  DASy
 SG_ RFC_Loc008_ThetaVnce : 128|16@1+ (0.00390625,0) [0|255.99609375] "deg^2"  DASy
 SG_ RFC_Loc008_PhiVnce : 144|16@1+ (0.00390625,0) [0|255.99609375] "deg^2"  DASy
 SG_ RFC_Loc008_DrVrCoVnce : 160|16@1+ (3.814697265625E-006,-0.125) [-0.125|0.124996185302734] "m^2/s"  DASy
 SG_ RFC_Loc008_RCS : 176|16@1+ (0.00390625,-128) [-128|127.99609375] "dBsm"  DASy
 SG_ RFC_Loc008_RSSI : 192|16@1+ (0.00195312,0) [0|127.998046875] "dimensionless"  DASy
 SG_ RFC_Loc008_DrVrQuality : 208|8@1+ (1,0) [0|255] "dimensionless"  DASy
 SG_ RFC_Loc008_ThetaQuality : 216|8@1+ (1,0) [0|255] "dimensionless"  DASy
 SG_ RFC_Loc008_PhiQuality : 224|8@1+ (1,0) [0|255] "dimensionless"  DASy
 SG_ RFC_Loc009_Dr : 256|16@1+ (0.0078125,0) [0|511.9921875] "m"  DASy
 SG_ RFC_Loc009_Vr : 272|16@1+ (0.00390625,-128) [-128|127.99609375] "m/s"  DASy
 SG_ RFC_Loc009_Theta : 288|16@1+ (0.01,-327.68) [-90|90] "deg"  DASy
 SG_ RFC_Loc009_Phi : 304|16@1+ (0.01,-327.68) [-30|30] "deg"  DASy
 SG_ RFC_Loc009_DrVnce : 320|16@1+ (1.52588E-005,0) [0|0.999984741210937] "m^2"  DASy
 SG_ RFC_Loc009_VrVnce : 336|16@1+ (1.52588E-005,0) [0|0.999984741210937] "m^2/s^2"  DASy
 SG_ RFC_Loc009_ThetaVnce : 352|16@1+ (0.00390625,0) [0|255.99609375] "deg^2"  DASy
 SG_ RFC_Loc009_PhiVnce : 368|16@1+ (0.00390625,0) [0|255.99609375] "deg^2"  DASy
 SG_ RFC_Loc009_DrVrCoVnce : 384|16@1+ (3.814697265625E-006,-0.125) [-0.125|0.124996185302734] "m^2/s"  DASy
 SG_ RFC_Loc009_RCS : 400|16@1+ (0.00390625,-128) [-128|127.99609375] "dBsm"  DASy
 SG_ RFC_Loc009_RSSI : 416|16@1+ (0.00195312,0) [0|127.998046875] "dimensionless"  DASy
 SG_ RFC_Loc009_DrVrQuality : 432|8@1+ (1,0) [0|255] "dimensionless"  DASy
 SG_ RFC_Loc009_ThetaQuality : 440|8@1+ (1,0) [0|255] "dimensionless"  DASy
 SG_ RFC_Loc009_PhiQuality : 448|8@1+ (1,0) [0|255] "dimensionless"  DASy

BO_ 405 RFC_Location_010_011: 64 RadarFrontCenter
 SG_ RFC_Loc010_CRC : 0|16@1+ (1,0) [0|65535] ""  DASy
 SG_ RFC_Loc010_AliveCtr : 16|8@1+ (1,0) [0|255] ""  DASy
 SG_ RFC_Loc010_ProtBlockCtr : 24|8@1+ (1,0) [0|255] ""  DASy
 SG_ RFC_Loc010_Dr : 32|16@1+ (0.0078125,0) [0|511.9921875] "m"  DASy
 SG_ RFC_Loc010_Vr : 48|16@1+ (0.00390625,-128) [-128|127.99609375] "m/s"  DASy
 SG_ RFC_Loc010_Theta : 64|16@1+ (0.01,-327.68) [-90|90] "deg"  DASy
 SG_ RFC_Loc010_Phi : 80|16@1+ (0.01,-327.68) [-30|30] "deg"  DASy
 SG_ RFC_Loc010_DrVnce : 96|16@1+ (1.52588E-005,0) [0|0.999984741210937] "m^2"  DASy
 SG_ RFC_Loc010_VrVnce : 112|16@1+ (1.52588E-005,0) [0|0.999984741210937] "m^2/s^2"  DASy
 SG_ RFC_Loc010_ThetaVnce : 128|16@1+ (0.00390625,0) [0|255.99609375] "deg^2"  DASy
 SG_ RFC_Loc010_PhiVnce : 144|16@1+ (0.00390625,0) [0|255.99609375] "deg^2"  DASy
 SG_ RFC_Loc010_DrVrCoVnce : 160|16@1+ (3.814697265625E-006,-0.125) [-0.125|0.124996185302734] "m^2/s"  DASy
 SG_ RFC_Loc010_RCS : 176|16@1+ (0.00390625,-128) [-128|127.99609375] "dBsm"  DASy
 SG_ RFC_Loc010_RSSI : 192|16@1+ (0.00195312,0) [0|127.998046875] "dimensionless"  DASy
 SG_ RFC_Loc010_DrVrQuality : 208|8@1+ (1,0) [0|255] "dimensionless"  DASy
 SG_ RFC_Loc010_ThetaQuality : 216|8@1+ (1,0) [0|255] "dimensionless"  DASy
 SG_ RFC_Loc010_PhiQuality : 224|8@1+ (1,0) [0|255] "dimensionless"  DASy
 SG_ RFC_Loc011_Dr : 256|16@1+ (0.0078125,0) [0|511.9921875] "m"  DASy
 SG_ RFC_Loc011_Vr : 272|16@1+ (0.00390625,-128) [-128|127.99609375] "m/s"  DASy
 SG_ RFC_Loc011_Theta : 288|16@1+ (0.01,-327.68) [-90|90] "deg"  DASy
 SG_ RFC_Loc011_Phi : 304|16@1+ (0.01,-327.68) [-30|30] "deg"  DASy
 SG_ RFC_Loc011_DrVnce : 320|16@1+ (1.52588E-005,0) [0|0.999984741210937] "m^2"  DASy
 SG_ RFC_Loc011_VrVnce : 336|16@1+ (1.52588E-005,0) [0|0.999984741210937] "m^2/s^2"  DASy
 SG_ RFC_Loc011_ThetaVnce : 352|16@1+ (0.00390625,0) [0|255.99609375] "deg^2"  DASy
 SG_ RFC_Loc011_PhiVnce : 368|16@1+ (0.00390625,0) [0|255.99609375] "deg^2"  DASy
 SG_ RFC_Loc011_DrVrCoVnce : 384|16@1+ (3.814697265625E-006,-0.125) [-0.125|0.124996185302734] "m^2/s"  DASy
 SG_ RFC_Loc011_RCS : 400|16@1+ (0.00390625,-128) [-128|127.99609375] "dBsm"  DASy
 SG_ RFC_Loc011_RSSI : 416|16@1+ (0.00195312,0) [0|127.998046875] "dimensionless"  DASy
 SG_ RFC_Loc011_DrVrQuality : 432|8@1+ (1,0) [0|255] "dimensionless"  DASy
 SG_ RFC_Loc011_ThetaQuality : 440|8@1+ (1,0) [0|255] "dimensionless"  DASy
 SG_ RFC_Loc011_PhiQuality : 448|8@1+ (1,0) [0|255] "dimensionless"  DASy

BO_ 406 RFC_Location_012_013: 64 RadarFrontCenter
 SG_ RFC_Loc012_CRC : 0|16@1+ (1,0) [0|65535] ""  DASy
 SG_ RFC_Loc012_AliveCtr : 16|8@1+ (1,0) [0|255] ""  DASy
 SG_ RFC_Loc012_ProtBlockCtr : 24|8@1+ (1,0) [0|255] ""  DASy
 SG_ RFC_Loc012_Dr : 32|16@1+ (0.0078125,0) [0|511.9921875] "m"  DASy
 SG_ RFC_Loc012_Vr : 48|16@1+ (0.00390625,-128) [-128|127.99609375] "m/s"  DASy
 SG_ RFC_Loc012_Theta : 64|16@1+ (0.01,-327.68) [-90|90] "deg"  DASy
 SG_ RFC_Loc012_Phi : 80|16@1+ (0.01,-327.68) [-30|30] "deg"  DASy
 SG_ RFC_Loc012_DrVnce : 96|16@1+ (1.52588E-005,0) [0|0.999984741210937] "m^2"  DASy
 SG_ RFC_Loc012_VrVnce : 112|16@1+ (1.52588E-005,0) [0|0.999984741210937] "m^2/s^2"  DASy
 SG_ RFC_Loc012_ThetaVnce : 128|16@1+ (0.00390625,0) [0|255.99609375] "deg^2"  DASy
 SG_ RFC_Loc012_PhiVnce : 144|16@1+ (0.00390625,0) [0|255.99609375] "deg^2"  DASy
 SG_ RFC_Loc012_DrVrCoVnce : 160|16@1+ (3.814697265625E-006,-0.125) [-0.125|0.124996185302734] "m^2/s"  DASy
 SG_ RFC_Loc012_RCS : 176|16@1+ (0.00390625,-128) [-128|127.99609375] "dBsm"  DASy
 SG_ RFC_Loc012_RSSI : 192|16@1+ (0.00195312,0) [0|127.998046875] "dimensionless"  DASy
 SG_ RFC_Loc012_DrVrQuality : 208|8@1+ (1,0) [0|255] "dimensionless"  DASy
 SG_ RFC_Loc012_ThetaQuality : 216|8@1+ (1,0) [0|255] "dimensionless"  DASy
 SG_ RFC_Loc012_PhiQuality : 224|8@1+ (1,0) [0|255] "dimensionless"  DASy
 SG_ RFC_Loc013_Dr : 256|16@1+ (0.0078125,0) [0|511.9921875] "m"  DASy
 SG_ RFC_Loc013_Vr : 272|16@1+ (0.00390625,-128) [-128|127.99609375] "m/s"  DASy
 SG_ RFC_Loc013_Theta : 288|16@1+ (0.01,-327.68) [-90|90] "deg"  DASy
 SG_ RFC_Loc013_Phi : 304|16@1+ (0.01,-327.68) [-30|30] "deg"  DASy
 SG_ RFC_Loc013_DrVnce : 320|16@1+ (1.52588E-005,0) [0|0.999984741210937] "m^2"  DASy
 SG_ RFC_Loc013_VrVnce : 336|16@1+ (1.52588E-005,0) [0|0.999984741210937] "m^2/s^2"  DASy
 SG_ RFC_Loc013_ThetaVnce : 352|16@1+ (0.00390625,0) [0|255.99609375] "deg^2"  DASy
 SG_ RFC_Loc013_PhiVnce : 368|16@1+ (0.00390625,0) [0|255.99609375] "deg^2"  DASy
 SG_ RFC_Loc013_DrVrCoVnce : 384|16@1+ (3.814697265625E-006,-0.125) [-0.125|0.124996185302734] "m^2/s"  DASy
 SG_ RFC_Loc013_RCS : 400|16@1+ (0.00390625,-128) [-128|127.99609375] "dBsm"  DASy
 SG_ RFC_Loc013_RSSI : 416|16@1+ (0.00195312,0) [0|127.998046875] "dimensionless"  DASy
 SG_ RFC_Loc013_DrVrQuality : 432|8@1+ (1,0) [0|255] "dimensionless"  DASy
 SG_ RFC_Loc013_ThetaQuality : 440|8@1+ (1,0) [0|255] "dimensionless"  DASy
 SG_ RFC_Loc013_PhiQuality : 448|8@1+ (1,0) [0|255] "dimensionless"  DASy

BO_ 407 RFC_Location_014_015: 64 RadarFrontCenter
 SG_ RFC_Loc014_CRC : 0|16@1+ (1,0) [0|65535] ""  DASy
 SG_ RFC_Loc014_AliveCtr : 16|8@1+ (1,0) [0|255] ""  DASy
 SG_ RFC_Loc014_ProtBlockCtr : 24|8@1+ (1,0) [0|255] ""  DASy
 SG_ RFC_Loc014_Dr : 32|16@1+ (0.0078125,0) [0|511.9921875] "m"  DASy
 SG_ RFC_Loc014_Vr : 48|16@1+ (0.00390625,-128) [-128|127.99609375] "m/s"  DASy
 SG_ RFC_Loc014_Theta : 64|16@1+ (0.01,-327.68) [-90|90] "deg"  DASy
 SG_ RFC_Loc014_Phi : 80|16@1+ (0.01,-327.68) [-30|30] "deg"  DASy
 SG_ RFC_Loc014_DrVnce : 96|16@1+ (1.52588E-005,0) [0|0.999984741210937] "m^2"  DASy
 SG_ RFC_Loc014_VrVnce : 112|16@1+ (1.52588E-005,0) [0|0.999984741210937] "m^2/s^2"  DASy
 SG_ RFC_Loc014_ThetaVnce : 128|16@1+ (0.00390625,0) [0|255.99609375] "deg^2"  DASy
 SG_ RFC_Loc014_PhiVnce : 144|16@1+ (0.00390625,0) [0|255.99609375] "deg^2"  DASy
 SG_ RFC_Loc014_DrVrCoVnce : 160|16@1+ (3.814697265625E-006,-0.125) [-0.125|0.124996185302734] "m^2/s"  DASy
 SG_ RFC_Loc014_RCS : 176|16@1+ (0.00390625,-128) [-128|127.99609375] "dBsm"  DASy
 SG_ RFC_Loc014_RSSI : 192|16@1+ (0.00195312,0) [0|127.998046875] "dimensionless"  DASy
 SG_ RFC_Loc014_DrVrQuality : 208|8@1+ (1,0) [0|255] "dimensionless"  DASy
 SG_ RFC_Loc014_ThetaQuality : 216|8@1+ (1,0) [0|255] "dimensionless"  DASy
 SG_ RFC_Loc014_PhiQuality : 224|8@1+ (1,0) [0|255] "dimensionless"  DASy
 SG_ RFC_Loc015_Dr : 256|16@1+ (0.0078125,0) [0|511.9921875] "m"  DASy
 SG_ RFC_Loc015_Vr : 272|16@1+ (0.00390625,-128) [-128|127.99609375] "m/s"  DASy
 SG_ RFC_Loc015_Theta : 288|16@1+ (0.01,-327.68) [-90|90] "deg"  DASy
 SG_ RFC_Loc015_Phi : 304|16@1+ (0.01,-327.68) [-30|30] "deg"  DASy
 SG_ RFC_Loc015_DrVnce : 320|16@1+ (1.52588E-005,0) [0|0.999984741210937] "m^2"  DASy
 SG_ RFC_Loc015_VrVnce : 336|16@1+ (1.52588E-005,0) [0|0.999984741210937] "m^2/s^2"  DASy
 SG_ RFC_Loc015_ThetaVnce : 352|16@1+ (0.00390625,0) [0|255.99609375] "deg^2"  DASy
 SG_ RFC_Loc015_PhiVnce : 368|16@1+ (0.00390625,0) [0|255.99609375] "deg^2"  DASy
 SG_ RFC_Loc015_DrVrCoVnce : 384|16@1+ (3.814697265625E-006,-0.125) [-0.125|0.124996185302734] "m^2/s"  DASy
 SG_ RFC_Loc015_RCS : 400|16@1+ (0.00390625,-128) [-128|127.99609375] "dBsm"  DASy
 SG_ RFC_Loc015_RSSI : 416|16@1+ (0.00195312,0) [0|127.998046875] "dimensionless"  DASy
 SG_ RFC_Loc015_DrVrQuality : 432|8@1+ (1,0) [0|255] "dimensionless"  DASy
 SG_ RFC_Loc015_ThetaQuality : 440|8@1+ (1,0) [0|255] "dimensionless"  DASy
 SG_ RFC_Loc015_PhiQuality : 448|8@1+ (1,0) [0|255] "dimensionless"  DASy

BO_ 408 RFC_Location_016_017: 64 RadarFrontCenter
 SG_ RFC_Loc016_CRC : 0|16@1+ (1,0) [0|65535] ""  DASy
 SG_ RFC_Loc016_AliveCtr : 16|8@1+ (1,0) [0|255] ""  DASy
 SG_ RFC_Loc016_ProtBlockCtr : 24|8@1+ (1,0) [0|255] ""  DASy
 SG_ RFC_Loc016_Dr : 32|16@1+ (0.0078125,0) [0|511.9921875] "m"  DASy
 SG_ RFC_Loc016_Vr : 48|16@1+ (0.00390625,-128) [-128|127.99609375] "m/s"  DASy
 SG_ RFC_Loc016_Theta : 64|16@1+ (0.01,-327.68) [-90|90] "deg"  DASy
 SG_ RFC_Loc016_Phi : 80|16@1+ (0.01,-327.68) [-30|30] "deg"  DASy
 SG_ RFC_Loc016_DrVnce : 96|16@1+ (1.52588E-005,0) [0|0.999984741210937] "m^2"  DASy
 SG_ RFC_Loc016_VrVnce : 112|16@1+ (1.52588E-005,0) [0|0.999984741210937] "m^2/s^2"  DASy
 SG_ RFC_Loc016_ThetaVnce : 128|16@1+ (0.00390625,0) [0|255.99609375] "deg^2"  DASy
 SG_ RFC_Loc016_PhiVnce : 144|16@1+ (0.00390625,0) [0|255.99609375] "deg^2"  DASy
 SG_ RFC_Loc016_DrVrCoVnce : 160|16@1+ (3.814697265625E-006,-0.125) [-0.125|0.124996185302734] "m^2/s"  DASy
 SG_ RFC_Loc016_RCS : 176|16@1+ (0.00390625,-128) [-128|127.99609375] "dBsm"  DASy
 SG_ RFC_Loc016_RSSI : 192|16@1+ (0.00195312,0) [0|127.998046875] "dimensionless"  DASy
 SG_ RFC_Loc016_DrVrQuality : 208|8@1+ (1,0) [0|255] "dimensionless"  DASy
 SG_ RFC_Loc016_ThetaQuality : 216|8@1+ (1,0) [0|255] "dimensionless"  DASy
 SG_ RFC_Loc016_PhiQuality : 224|8@1+ (1,0) [0|255] "dimensionless"  DASy
 SG_ RFC_Loc017_Dr : 256|16@1+ (0.0078125,0) [0|511.9921875] "m"  DASy
 SG_ RFC_Loc017_Vr : 272|16@1+ (0.00390625,-128) [-128|127.99609375] "m/s"  DASy
 SG_ RFC_Loc017_Theta : 288|16@1+ (0.01,-327.68) [-90|90] "deg"  DASy
 SG_ RFC_Loc017_Phi : 304|16@1+ (0.01,-327.68) [-30|30] "deg"  DASy
 SG_ RFC_Loc017_DrVnce : 320|16@1+ (1.52588E-005,0) [0|0.999984741210937] "m^2"  DASy
 SG_ RFC_Loc017_VrVnce : 336|16@1+ (1.52588E-005,0) [0|0.999984741210937] "m^2/s^2"  DASy
 SG_ RFC_Loc017_ThetaVnce : 352|16@1+ (0.00390625,0) [0|255.99609375] "deg^2"  DASy
 SG_ RFC_Loc017_PhiVnce : 368|16@1+ (0.00390625,0) [0|255.99609375] "deg^2"  DASy
 SG_ RFC_Loc017_DrVrCoVnce : 384|16@1+ (3.814697265625E-006,-0.125) [-0.125|0.124996185302734] "m^2/s"  DASy
 SG_ RFC_Loc017_RCS : 400|16@1+ (0.00390625,-128) [-128|127.99609375] "dBsm"  DASy
 SG_ RFC_Loc017_RSSI : 416|16@1+ (0.00195312,0) [0|127.998046875] "dimensionless"  DASy
 SG_ RFC_Loc017_DrVrQuality : 432|8@1+ (1,0) [0|255] "dimensionless"  DASy
 SG_ RFC_Loc017_ThetaQuality : 440|8@1+ (1,0) [0|255] "dimensionless"  DASy
 SG_ RFC_Loc017_PhiQuality : 448|8@1+ (1,0) [0|255] "dimensionless"  DASy

CM_ SG_ 250 VFC_TS12_CRC "CRC - Autosar E2E Profile 5";
CM_ SG_ 250 VFC_TS12_AliveCtr "Alive counter - Autosar E2E Profile 5";
CM_ SG_ 250 VFC_TS12_ProtBlockCtr "Protocol-Signal: Block-Counter";
CM_ SG_ 250 VFC_TS12_ProtOrderIndex "Protocol-Signal: Index to ensure same order in Tx and Rx (Ethernet only)";
CM_ SG_ 250 VFC_TS12_ID "Unique Traffic Sign ID";
CM_ SG_ 250 VFC_TS12_Class "The type of main sign that has been detected by the vision system";
CM_ SG_ 250 VFC_TS12_TSProb "Probability that the sign is a traffic sign";
CM_ SG_ 250 VFC_TS12_Dx "Traffic sign distance in longitudinal direction";
CM_ SG_ 250 VFC_TS12_Dy "Traffic sign distance in lateral direction";
CM_ SG_ 250 VFC_TS12_Dz "Traffic sign distance in vertical direction";
CM_ SG_ 250 VFC_TS12_DxStdDev "Standard deviation of Traffic sign distance in longitudinal direction";
CM_ SG_ 250 VFC_TS12_DyStdDev "Standard deviation of Traffic sign distance in lateral direction";
CM_ SG_ 250 VFC_TS12_DzStdDev "Standard deviation of Traffic sign distance in vertical direction";
CM_ SG_ 250 VFC_TS12_Width "Width of the sign";
CM_ SG_ 250 VFC_TS12_Height "Height of the sign";
CM_ SG_ 250 VFC_TS12_EmbedFlag "Determines whether the sign is embedded or not";
CM_ SG_ 250 VFC_TS12_Quality "A flag that determines the quality of the sign";
CM_ SG_ 250 VFC_TS12_VMS "Variable-message sign: Determines whether the traffic sign is Variable or fixed";
CM_ SG_ 250 VFC_TS12_Stable "Determines whether the object is stable";
CM_ SG_ 250 VFC_TS12_VehicleSticker "Flag which indicates whether the detected traffic sign is a invalid sign on a vehicle or not";
CM_ SG_ 250 VFC_TS12_InternalTrack "Flag which indicates if this sign is an internal track, i.e. an sign hypothesis of low quality";
CM_ SG_ 250 VFC_TS12_ValidLanes "Indicates on which lane the detected sign is valid. Bitfield:

Bit 0: valid on first right hand lane

Bit 1: valid on second right hand lane

Bit 2: valid on third right hand lane

Bit 3: valid on fourth right hand lane

Bit 4: valid on fifth right hand lane";
CM_ SG_ 250 VFC_TS12_ValidDay "The MPC3 sensor shall provide the week days for which the main traffic sign is valid. Bitfield:

Bit 0: MONDAY

Bit 1: TUESDAY

Bit 2: WEDNESDAY

Bit 3: THURSDAY

Bit 4: FRIDAY

Bit 5: SATURDAY

Bit 6: SUNDAY";
CM_ SG_ 250 VFC_TS12_ValidTimeRange1Start "Start time for the first time range in which the main traffic sign is valid. Minutes since midnight.";
CM_ SG_ 250 VFC_TS12_ValidTimeRange1End "End time for the first time range in which the main traffic sign is valid. Minutes since midnight.";
CM_ SG_ 250 VFC_TS12_ValidTimeRange2Start "Start time for the first time range in which the main traffic sign is valid. Minutes since midnight.";
CM_ SG_ 250 VFC_TS12_ValidTimeRange2End "End time for the first time range in which the main traffic sign is valid. Minutes since midnight.";
CM_ SG_ 250 VFC_TS12_ValidInDist "Indicates the longitudinal distance in which the validity of the main TSR starts";
CM_ SG_ 250 VFC_TS12_ValidDist "Indicates the longitudinal distance for which the main traffic sign is valid";
CM_ SG_ 250 VFC_TS12_AddTSCount "Number of additional signs attached to the main sign. This can be a minimum of 0 and a maximum of 6.";
CM_ SG_ 250 VFC_TS12_AddTS1Class "The type of additonal sign that has been detected by the vision system";
CM_ SG_ 250 VFC_TS12_AddTS1Prob "Probability that the sign is a traffic sign";
CM_ SG_ 250 VFC_TS12_AddTS1Quality "A flag that determines the quality of the signal";
CM_ SG_ 250 VFC_TS12_AddTS1VMS "Variable-message sign: Determines whether the traffic sign is Variable or fixed";
CM_ SG_ 250 VFC_TS12_AddTS2Class "The type of additonal sign that has been detected by the vision system";
CM_ SG_ 250 VFC_TS12_AddTS2Prob "Probability that the sign is a traffic sign";
CM_ SG_ 250 VFC_TS12_AddTS2Quality "A flag that determines the quality of the signal";
CM_ SG_ 250 VFC_TS12_AddTS2VMS "Variable-message sign: Determines whether the traffic sign is Variable or fixed";
CM_ SG_ 250 VFC_TS12_AddTS3Class "The type of additonal sign that has been detected by the vision system";
CM_ SG_ 250 VFC_TS12_AddTS3Prob "Probability that the sign is a traffic sign";
CM_ SG_ 250 VFC_TS12_AddTS3Quality "A flag that determines the quality of the signal";
CM_ SG_ 250 VFC_TS12_AddTS3VMS "Variable-message sign: Determines whether the traffic sign is Variable or fixed";
CM_ SG_ 250 VFC_TS12_AddTS4Class "The type of additonal sign that has been detected by the vision system";
CM_ SG_ 250 VFC_TS12_AddTS4Prob "Probability that the sign is a traffic sign";
CM_ SG_ 250 VFC_TS12_AddTS4Quality "A flag that determines the quality of the signal";
CM_ SG_ 250 VFC_TS12_AddTS4VMS "Variable-message sign: Determines whether the traffic sign is Variable or fixed";
CM_ SG_ 250 VFC_TS12_AddTS5Class "The type of additonal sign that has been detected by the vision system";
CM_ SG_ 250 VFC_TS12_AddTS5Prob "Probability that the sign is a traffic sign";
CM_ SG_ 250 VFC_TS12_AddTS5Quality "A flag that determines the quality of the signal";
CM_ SG_ 250 VFC_TS12_AddTS5VMS "Variable-message sign: Determines whether the traffic sign is Variable or fixed";
CM_ SG_ 250 VFC_TS12_AddTS6Class "The type of additonal sign that has been detected by the vision system";
CM_ SG_ 250 VFC_TS12_AddTS6Prob "Probability that the sign is a traffic sign";
CM_ SG_ 250 VFC_TS12_AddTS6Quality "A flag that determines the quality of the signal";
CM_ SG_ 250 VFC_TS12_AddTS6VMS "Variable-message sign: Determines whether the traffic sign is Variable or fixed";
CM_ SG_ 250 VFC_TS12_FV "SecOC Freshness Value (Profile 1)";
CM_ SG_ 250 VFC_TS12_MAC "SecOC MAC (Profile 1)";
CM_ SG_ 251 VFC_TS13_CRC "CRC - Autosar E2E Profile 5";
CM_ SG_ 251 VFC_TS13_AliveCtr "Alive counter - Autosar E2E Profile 5";
CM_ SG_ 251 VFC_TS13_ProtBlockCtr "Protocol-Signal: Block-Counter";
CM_ SG_ 251 VFC_TS13_ProtOrderIndex "Protocol-Signal: Index to ensure same order in Tx and Rx (Ethernet only)";
CM_ SG_ 251 VFC_TS13_ID "Unique Traffic Sign ID";
CM_ SG_ 251 VFC_TS13_Class "The type of main sign that has been detected by the vision system";
CM_ SG_ 251 VFC_TS13_TSProb "Probability that the sign is a traffic sign";
CM_ SG_ 251 VFC_TS13_Dx "Traffic sign distance in longitudinal direction";
CM_ SG_ 251 VFC_TS13_Dy "Traffic sign distance in lateral direction";
CM_ SG_ 251 VFC_TS13_Dz "Traffic sign distance in vertical direction";
CM_ SG_ 251 VFC_TS13_DxStdDev "Standard deviation of Traffic sign distance in longitudinal direction";
CM_ SG_ 251 VFC_TS13_DyStdDev "Standard deviation of Traffic sign distance in lateral direction";
CM_ SG_ 251 VFC_TS13_DzStdDev "Standard deviation of Traffic sign distance in vertical direction";
CM_ SG_ 251 VFC_TS13_Width "Width of the sign";
CM_ SG_ 251 VFC_TS13_Height "Height of the sign";
CM_ SG_ 251 VFC_TS13_EmbedFlag "Determines whether the sign is embedded or not";
CM_ SG_ 251 VFC_TS13_Quality "A flag that determines the quality of the sign";
CM_ SG_ 251 VFC_TS13_VMS "Variable-message sign: Determines whether the traffic sign is Variable or fixed";
CM_ SG_ 251 VFC_TS13_Stable "Determines whether the object is stable";
CM_ SG_ 251 VFC_TS13_VehicleSticker "Flag which indicates whether the detected traffic sign is a invalid sign on a vehicle or not";
CM_ SG_ 251 VFC_TS13_InternalTrack "Flag which indicates if this sign is an internal track, i.e. an sign hypothesis of low quality";
CM_ SG_ 251 VFC_TS13_ValidLanes "Indicates on which lane the detected sign is valid. Bitfield:

Bit 0: valid on first right hand lane

Bit 1: valid on second right hand lane

Bit 2: valid on third right hand lane

Bit 3: valid on fourth right hand lane

Bit 4: valid on fifth right hand lane";
CM_ SG_ 251 VFC_TS13_ValidDay "The MPC3 sensor shall provide the week days for which the main traffic sign is valid. Bitfield:

Bit 0: MONDAY

Bit 1: TUESDAY

Bit 2: WEDNESDAY

Bit 3: THURSDAY

Bit 4: FRIDAY

Bit 5: SATURDAY

Bit 6: SUNDAY";
CM_ SG_ 251 VFC_TS13_ValidTimeRange1Start "Start time for the first time range in which the main traffic sign is valid. Minutes since midnight.";
CM_ SG_ 251 VFC_TS13_ValidTimeRange1End "End time for the first time range in which the main traffic sign is valid. Minutes since midnight.";
CM_ SG_ 251 VFC_TS13_ValidTimeRange2Start "Start time for the first time range in which the main traffic sign is valid. Minutes since midnight.";
CM_ SG_ 251 VFC_TS13_ValidTimeRange2End "End time for the first time range in which the main traffic sign is valid. Minutes since midnight.";
CM_ SG_ 251 VFC_TS13_ValidInDist "Indicates the longitudinal distance in which the validity of the main TSR starts";
CM_ SG_ 251 VFC_TS13_ValidDist "Indicates the longitudinal distance for which the main traffic sign is valid";
CM_ SG_ 251 VFC_TS13_AddTSCount "Number of additional signs attached to the main sign. This can be a minimum of 0 and a maximum of 6.";
CM_ SG_ 251 VFC_TS13_AddTS1Class "The type of additonal sign that has been detected by the vision system";
CM_ SG_ 251 VFC_TS13_AddTS1Prob "Probability that the sign is a traffic sign";
CM_ SG_ 251 VFC_TS13_AddTS1Quality "A flag that determines the quality of the signal";
CM_ SG_ 251 VFC_TS13_AddTS1VMS "Variable-message sign: Determines whether the traffic sign is Variable or fixed";
CM_ SG_ 251 VFC_TS13_AddTS2Class "The type of additonal sign that has been detected by the vision system";
CM_ SG_ 251 VFC_TS13_AddTS2Prob "Probability that the sign is a traffic sign";
CM_ SG_ 251 VFC_TS13_AddTS2Quality "A flag that determines the quality of the signal";
CM_ SG_ 251 VFC_TS13_AddTS2VMS "Variable-message sign: Determines whether the traffic sign is Variable or fixed";
CM_ SG_ 251 VFC_TS13_AddTS3Class "The type of additonal sign that has been detected by the vision system";
CM_ SG_ 251 VFC_TS13_AddTS3Prob "Probability that the sign is a traffic sign";
CM_ SG_ 251 VFC_TS13_AddTS3Quality "A flag that determines the quality of the signal";
CM_ SG_ 251 VFC_TS13_AddTS3VMS "Variable-message sign: Determines whether the traffic sign is Variable or fixed";
CM_ SG_ 251 VFC_TS13_AddTS4Class "The type of additonal sign that has been detected by the vision system";
CM_ SG_ 251 VFC_TS13_AddTS4Prob "Probability that the sign is a traffic sign";
CM_ SG_ 251 VFC_TS13_AddTS4Quality "A flag that determines the quality of the signal";
CM_ SG_ 251 VFC_TS13_AddTS4VMS "Variable-message sign: Determines whether the traffic sign is Variable or fixed";
CM_ SG_ 251 VFC_TS13_AddTS5Class "The type of additonal sign that has been detected by the vision system";
CM_ SG_ 251 VFC_TS13_AddTS5Prob "Probability that the sign is a traffic sign";
CM_ SG_ 251 VFC_TS13_AddTS5Quality "A flag that determines the quality of the signal";
CM_ SG_ 251 VFC_TS13_AddTS5VMS "Variable-message sign: Determines whether the traffic sign is Variable or fixed";
CM_ SG_ 251 VFC_TS13_AddTS6Class "The type of additonal sign that has been detected by the vision system";
CM_ SG_ 251 VFC_TS13_AddTS6Prob "Probability that the sign is a traffic sign";
CM_ SG_ 251 VFC_TS13_AddTS6Quality "A flag that determines the quality of the signal";
CM_ SG_ 251 VFC_TS13_AddTS6VMS "Variable-message sign: Determines whether the traffic sign is Variable or fixed";
CM_ SG_ 251 VFC_TS13_FV "SecOC Freshness Value (Profile 1)";
CM_ SG_ 251 VFC_TS13_MAC "SecOC MAC (Profile 1)";
CM_ SG_ 252 VFC_TS14_CRC "CRC - Autosar E2E Profile 5";
CM_ SG_ 252 VFC_TS14_AliveCtr "Alive counter - Autosar E2E Profile 5";
CM_ SG_ 252 VFC_TS14_ProtBlockCtr "Protocol-Signal: Block-Counter";
CM_ SG_ 252 VFC_TS14_ProtOrderIndex "Protocol-Signal: Index to ensure same order in Tx and Rx (Ethernet only)";
CM_ SG_ 252 VFC_TS14_ID "Unique Traffic Sign ID";
CM_ SG_ 252 VFC_TS14_Class "The type of main sign that has been detected by the vision system";
CM_ SG_ 252 VFC_TS14_TSProb "Probability that the sign is a traffic sign";
CM_ SG_ 252 VFC_TS14_Dx "Traffic sign distance in longitudinal direction";
CM_ SG_ 252 VFC_TS14_Dy "Traffic sign distance in lateral direction";
CM_ SG_ 252 VFC_TS14_Dz "Traffic sign distance in vertical direction";
CM_ SG_ 252 VFC_TS14_DxStdDev "Standard deviation of Traffic sign distance in longitudinal direction";
CM_ SG_ 252 VFC_TS14_DyStdDev "Standard deviation of Traffic sign distance in lateral direction";
CM_ SG_ 252 VFC_TS14_DzStdDev "Standard deviation of Traffic sign distance in vertical direction";
CM_ SG_ 252 VFC_TS14_Width "Width of the sign";
CM_ SG_ 252 VFC_TS14_Height "Height of the sign";
CM_ SG_ 252 VFC_TS14_EmbedFlag "Determines whether the sign is embedded or not";
CM_ SG_ 252 VFC_TS14_Quality "A flag that determines the quality of the sign";
CM_ SG_ 252 VFC_TS14_VMS "Variable-message sign: Determines whether the traffic sign is Variable or fixed";
CM_ SG_ 252 VFC_TS14_Stable "Determines whether the object is stable";
CM_ SG_ 252 VFC_TS14_VehicleSticker "Flag which indicates whether the detected traffic sign is a invalid sign on a vehicle or not";
CM_ SG_ 252 VFC_TS14_InternalTrack "Flag which indicates if this sign is an internal track, i.e. an sign hypothesis of low quality";
CM_ SG_ 252 VFC_TS14_ValidLanes "Indicates on which lane the detected sign is valid. Bitfield:

Bit 0: valid on first right hand lane

Bit 1: valid on second right hand lane

Bit 2: valid on third right hand lane

Bit 3: valid on fourth right hand lane

Bit 4: valid on fifth right hand lane";
CM_ SG_ 252 VFC_TS14_ValidDay "The MPC3 sensor shall provide the week days for which the main traffic sign is valid. Bitfield:

Bit 0: MONDAY

Bit 1: TUESDAY

Bit 2: WEDNESDAY

Bit 3: THURSDAY

Bit 4: FRIDAY

Bit 5: SATURDAY

Bit 6: SUNDAY";
CM_ SG_ 252 VFC_TS14_ValidTimeRange1Start "Start time for the first time range in which the main traffic sign is valid. Minutes since midnight.";
CM_ SG_ 252 VFC_TS14_ValidTimeRange1End "End time for the first time range in which the main traffic sign is valid. Minutes since midnight.";
CM_ SG_ 252 VFC_TS14_ValidTimeRange2Start "Start time for the first time range in which the main traffic sign is valid. Minutes since midnight.";
CM_ SG_ 252 VFC_TS14_ValidTimeRange2End "End time for the first time range in which the main traffic sign is valid. Minutes since midnight.";
CM_ SG_ 252 VFC_TS14_ValidInDist "Indicates the longitudinal distance in which the validity of the main TSR starts";
CM_ SG_ 252 VFC_TS14_ValidDist "Indicates the longitudinal distance for which the main traffic sign is valid";
CM_ SG_ 252 VFC_TS14_AddTSCount "Number of additional signs attached to the main sign. This can be a minimum of 0 and a maximum of 6.";
CM_ SG_ 252 VFC_TS14_AddTS1Class "The type of additonal sign that has been detected by the vision system";
CM_ SG_ 252 VFC_TS14_AddTS1Prob "Probability that the sign is a traffic sign";
CM_ SG_ 252 VFC_TS14_AddTS1Quality "A flag that determines the quality of the signal";
CM_ SG_ 252 VFC_TS14_AddTS1VMS "Variable-message sign: Determines whether the traffic sign is Variable or fixed";
CM_ SG_ 252 VFC_TS14_AddTS2Class "The type of additonal sign that has been detected by the vision system";
CM_ SG_ 252 VFC_TS14_AddTS2Prob "Probability that the sign is a traffic sign";
CM_ SG_ 252 VFC_TS14_AddTS2Quality "A flag that determines the quality of the signal";
CM_ SG_ 252 VFC_TS14_AddTS2VMS "Variable-message sign: Determines whether the traffic sign is Variable or fixed";
CM_ SG_ 252 VFC_TS14_AddTS3Class "The type of additonal sign that has been detected by the vision system";
CM_ SG_ 252 VFC_TS14_AddTS3Prob "Probability that the sign is a traffic sign";
CM_ SG_ 252 VFC_TS14_AddTS3Quality "A flag that determines the quality of the signal";
CM_ SG_ 252 VFC_TS14_AddTS3VMS "Variable-message sign: Determines whether the traffic sign is Variable or fixed";
CM_ SG_ 252 VFC_TS14_AddTS4Class "The type of additonal sign that has been detected by the vision system";
CM_ SG_ 252 VFC_TS14_AddTS4Prob "Probability that the sign is a traffic sign";
CM_ SG_ 252 VFC_TS14_AddTS4Quality "A flag that determines the quality of the signal";
CM_ SG_ 252 VFC_TS14_AddTS4VMS "Variable-message sign: Determines whether the traffic sign is Variable or fixed";
CM_ SG_ 252 VFC_TS14_AddTS5Class "The type of additonal sign that has been detected by the vision system";
CM_ SG_ 252 VFC_TS14_AddTS5Prob "Probability that the sign is a traffic sign";
CM_ SG_ 252 VFC_TS14_AddTS5Quality "A flag that determines the quality of the signal";
CM_ SG_ 252 VFC_TS14_AddTS5VMS "Variable-message sign: Determines whether the traffic sign is Variable or fixed";
CM_ SG_ 252 VFC_TS14_AddTS6Class "The type of additonal sign that has been detected by the vision system";
CM_ SG_ 252 VFC_TS14_AddTS6Prob "Probability that the sign is a traffic sign";
CM_ SG_ 252 VFC_TS14_AddTS6Quality "A flag that determines the quality of the signal";
CM_ SG_ 252 VFC_TS14_AddTS6VMS "Variable-message sign: Determines whether the traffic sign is Variable or fixed";
CM_ SG_ 252 VFC_TS14_FV "SecOC Freshness Value (Profile 1)";
CM_ SG_ 252 VFC_TS14_MAC "SecOC MAC (Profile 1)";
CM_ SG_ 253 VFC_TS15_CRC "CRC - Autosar E2E Profile 5";
CM_ SG_ 253 VFC_TS15_AliveCtr "Alive counter - Autosar E2E Profile 5";
CM_ SG_ 253 VFC_TS15_ProtBlockCtr "Protocol-Signal: Block-Counter";
CM_ SG_ 253 VFC_TS15_ProtOrderIndex "Protocol-Signal: Index to ensure same order in Tx and Rx (Ethernet only)";
CM_ SG_ 253 VFC_TS15_ID "Unique Traffic Sign ID";
CM_ SG_ 253 VFC_TS15_Class "The type of main sign that has been detected by the vision system";
CM_ SG_ 253 VFC_TS15_TSProb "Probability that the sign is a traffic sign";
CM_ SG_ 253 VFC_TS15_Dx "Traffic sign distance in longitudinal direction";
CM_ SG_ 253 VFC_TS15_Dy "Traffic sign distance in lateral direction";
CM_ SG_ 253 VFC_TS15_Dz "Traffic sign distance in vertical direction";
CM_ SG_ 253 VFC_TS15_DxStdDev "Standard deviation of Traffic sign distance in longitudinal direction";
CM_ SG_ 253 VFC_TS15_DyStdDev "Standard deviation of Traffic sign distance in lateral direction";
CM_ SG_ 253 VFC_TS15_DzStdDev "Standard deviation of Traffic sign distance in vertical direction";
CM_ SG_ 253 VFC_TS15_Width "Width of the sign";
CM_ SG_ 253 VFC_TS15_Height "Height of the sign";
CM_ SG_ 253 VFC_TS15_EmbedFlag "Determines whether the sign is embedded or not";
CM_ SG_ 253 VFC_TS15_Quality "A flag that determines the quality of the sign";
CM_ SG_ 253 VFC_TS15_VMS "Variable-message sign: Determines whether the traffic sign is Variable or fixed";
CM_ SG_ 253 VFC_TS15_Stable "Determines whether the object is stable";
CM_ SG_ 253 VFC_TS15_VehicleSticker "Flag which indicates whether the detected traffic sign is a invalid sign on a vehicle or not";
CM_ SG_ 253 VFC_TS15_InternalTrack "Flag which indicates if this sign is an internal track, i.e. an sign hypothesis of low quality";
CM_ SG_ 253 VFC_TS15_ValidLanes "Indicates on which lane the detected sign is valid. Bitfield:

Bit 0: valid on first right hand lane

Bit 1: valid on second right hand lane

Bit 2: valid on third right hand lane

Bit 3: valid on fourth right hand lane

Bit 4: valid on fifth right hand lane";
CM_ SG_ 253 VFC_TS15_ValidDay "The MPC3 sensor shall provide the week days for which the main traffic sign is valid. Bitfield:

Bit 0: MONDAY

Bit 1: TUESDAY

Bit 2: WEDNESDAY

Bit 3: THURSDAY

Bit 4: FRIDAY

Bit 5: SATURDAY

Bit 6: SUNDAY";
CM_ SG_ 253 VFC_TS15_ValidTimeRange1Start "Start time for the first time range in which the main traffic sign is valid. Minutes since midnight.";
CM_ SG_ 253 VFC_TS15_ValidTimeRange1End "End time for the first time range in which the main traffic sign is valid. Minutes since midnight.";
CM_ SG_ 253 VFC_TS15_ValidTimeRange2Start "Start time for the first time range in which the main traffic sign is valid. Minutes since midnight.";
CM_ SG_ 253 VFC_TS15_ValidTimeRange2End "End time for the first time range in which the main traffic sign is valid. Minutes since midnight.";
CM_ SG_ 253 VFC_TS15_ValidInDist "Indicates the longitudinal distance in which the validity of the main TSR starts";
CM_ SG_ 253 VFC_TS15_ValidDist "Indicates the longitudinal distance for which the main traffic sign is valid";
CM_ SG_ 253 VFC_TS15_AddTSCount "Number of additional signs attached to the main sign. This can be a minimum of 0 and a maximum of 6.";
CM_ SG_ 253 VFC_TS15_AddTS1Class "The type of additonal sign that has been detected by the vision system";
CM_ SG_ 253 VFC_TS15_AddTS1Prob "Probability that the sign is a traffic sign";
CM_ SG_ 253 VFC_TS15_AddTS1Quality "A flag that determines the quality of the signal";
CM_ SG_ 253 VFC_TS15_AddTS1VMS "Variable-message sign: Determines whether the traffic sign is Variable or fixed";
CM_ SG_ 253 VFC_TS15_AddTS2Class "The type of additonal sign that has been detected by the vision system";
CM_ SG_ 253 VFC_TS15_AddTS2Prob "Probability that the sign is a traffic sign";
CM_ SG_ 253 VFC_TS15_AddTS2Quality "A flag that determines the quality of the signal";
CM_ SG_ 253 VFC_TS15_AddTS2VMS "Variable-message sign: Determines whether the traffic sign is Variable or fixed";
CM_ SG_ 253 VFC_TS15_AddTS3Class "The type of additonal sign that has been detected by the vision system";
CM_ SG_ 253 VFC_TS15_AddTS3Prob "Probability that the sign is a traffic sign";
CM_ SG_ 253 VFC_TS15_AddTS3Quality "A flag that determines the quality of the signal";
CM_ SG_ 253 VFC_TS15_AddTS3VMS "Variable-message sign: Determines whether the traffic sign is Variable or fixed";
CM_ SG_ 253 VFC_TS15_AddTS4Class "The type of additonal sign that has been detected by the vision system";
CM_ SG_ 253 VFC_TS15_AddTS4Prob "Probability that the sign is a traffic sign";
CM_ SG_ 253 VFC_TS15_AddTS4Quality "A flag that determines the quality of the signal";
CM_ SG_ 253 VFC_TS15_AddTS4VMS "Variable-message sign: Determines whether the traffic sign is Variable or fixed";
CM_ SG_ 253 VFC_TS15_AddTS5Class "The type of additonal sign that has been detected by the vision system";
CM_ SG_ 253 VFC_TS15_AddTS5Prob "Probability that the sign is a traffic sign";
CM_ SG_ 253 VFC_TS15_AddTS5Quality "A flag that determines the quality of the signal";
CM_ SG_ 253 VFC_TS15_AddTS5VMS "Variable-message sign: Determines whether the traffic sign is Variable or fixed";
CM_ SG_ 253 VFC_TS15_AddTS6Class "The type of additonal sign that has been detected by the vision system";
CM_ SG_ 253 VFC_TS15_AddTS6Prob "Probability that the sign is a traffic sign";
CM_ SG_ 253 VFC_TS15_AddTS6Quality "A flag that determines the quality of the signal";
CM_ SG_ 253 VFC_TS15_AddTS6VMS "Variable-message sign: Determines whether the traffic sign is Variable or fixed";
CM_ SG_ 253 VFC_TS15_FV "SecOC Freshness Value (Profile 1)";
CM_ SG_ 253 VFC_TS15_MAC "SecOC MAC (Profile 1)";
CM_ BO_ 255 "AUTOSAR Time Sync";
CM_ SG_ 255 ADAS_SYNC_FC_OVS "in FUP PDU
OVS = Overflow of seconds";
CM_ SG_ 255 ADAS_SYNC_FC_SGW "in FUP PDU
SyncToGTM = 0
SyncToSubDomain = 1";
CM_ SG_ 255 ADAS_SYNC_FC_Reserved "in FUP PDU
reserved, default =0";
CM_ SG_ 255 ADAS_SYNC_FC_SyncTime "TSync: SyncTimeSec = 32 bit LSB of the 48 bits seconds part of the time
TSync FUP: SyncTimeNSec = 32 Bit time value in nanoseconds";
CM_ SG_ 255 ADAS_SYNC_FC_TimeDomain "Time Domain";
CM_ SG_ 255 ADAS_SYNC_FC_SequenceCnt "Sequence counter";
CM_ SG_ 255 ADAS_SYNC_FC_CRC "CRC";
CM_ SG_ 255 ADAS_SYNC_FC_Type "Type=0x20 : TSync    Type=0x28 : TSync FUP";
CM_ SG_ 75 ADAS_AEBHMI_CRC "E2E Profile 5--CRC";
CM_ SG_ 75 ADAS_AEBHMI_AliveCnt "E2E Profile 5--Alive Counter";
CM_ SG_ 75 ADAS_FwdWarnFltTxt "FCW warning system failure";
CM_ SG_ 75 ADAS_FCWSwtFb "FCW warning switch status feedback";
CM_ SG_ 75 ADAS_AEBSwtFb "AEB switch status feedbac";
CM_ SG_ 75 ADAS_ADASSnvtySetFb "ADAS sensitivity set feedback";
CM_ SG_ 75 ADAS_Warn_FCW "FCW warning";
CM_ SG_ 75 ADAS_WarnTyp_FCWAEB "FCWAEB warning type";
CM_ SG_ 75 ADAS_Sts_FCW "FCW status";
CM_ SG_ 75 ADAS_Sts_AEB "AEB status";
CM_ SG_ 74 ADAS_FrntTar_AliveCnt "E2E Profile 5--Alive Counter";
CM_ SG_ 74 ADAS_FrntTar_CRC "E2E Profile 5--CRC";
CM_ SG_ 74 ADAS_FrntTar1Typ_ACC "Front ACC/AEB target object type";
CM_ SG_ 74 ADAS_FrntTar1X_ACC "Front ACC/AEB target object in X direction
X direction distance between ego car and front ACC/AEB target object";
CM_ SG_ 74 ADAS_FrntTar1Y_ACC "Front ACC/AEB target object in Y direction
Y direction distance between ego car and front ACC/AEB target object";
CM_ SG_ 81 RFC_SensorS_AliveCtr "Alive counter - Autosar E2E Profile 5";
CM_ SG_ 81 RFC_SensorS_CRC "CRC - Autosar E2E Profile 5";
CM_ BO_ 2281601536 "Frame Counter";
CM_ BO_ 931 "map info. after eHorizon re-constructor processing";
CM_ SG_ 931 VFC_MapInfo_CountryCode "country code, ISO3166-1, CN=156";
CM_ SG_ 931 VFC_MapInfo_CurrentLane "Current Lane where vehicle is located";
CM_ SG_ 931 VFC_MapInfo_RoadCurv "the road curvature in the driving direction, 
maximum curvature value(minimum radius) within the range of video detection( 150m?)";
CM_ SG_ 931 VFC_MapInfo_BuildUp_Dx "distance to the buildup in the driving direction";
CM_ SG_ 931 VFC_MapInfo_BuildUp "vehicle relation to the buildup";
CM_ SG_ 931 VFC_MapInfo_Bridge_Dx "distance to the bridge in the driving direction";
CM_ SG_ 931 VFC_MapInfo_Bridge "vehicle relation to the bridge";
CM_ SG_ 931 VFC_MapInfo_Tunnel "vehicle relation to the tunnel";
CM_ SG_ 931 VFC_MapInfo_Tunnel_Dx "distance to the tunnel in the driving direction";
CM_ SG_ 931 VFC_MapInfo_TollGate "vehicle relation to the tollgate";
CM_ SG_ 931 VFC_MapInfo_TollGate_Dx "distance to the tollgate in the driving direction";
CM_ SG_ 931 VFC_MapInfo_DiRoad_Offset200 "Road divided info at offset 200 meter";
CM_ SG_ 931 VFC_MapInfo_LaneNum_Offset200 "Lane number info at offset 200 meter";
CM_ SG_ 931 VFC_MapInfo_LaneNum_Offset0 "Lane number info at offset 0 meter";
CM_ SG_ 931 VFC_MapInfo_DiRoad_Offset0 "Road divided info at offset 0 meter";
CM_ SG_ 931 VFC_MapInfo_RoadClass_Offset200 "road class info,at offset 200 meter";
CM_ SG_ 931 VFC_MapInfo_RoadClass_Offset0 "road class info,at offset 0, that is at the vehicle current position";
CM_ SG_ 931 VFC_MapInfo_AliveCtr "Alive counter - Autosar E2E Profile 5";
CM_ SG_ 931 VFC_MapInfo_CRC "CRC - Autosar E2E Profile 5";
CM_ BO_ 930 "Speed limit value, from video to DASy";
CM_ SG_ 930 VFC_TSR_ASL_CRC "CRC - Autosar E2E Profile 5";
CM_ SG_ 930 VFC_TSR_ASL_AliveCtr "Alive counter - Autosar E2E Profile 5";
CM_ SG_ 930 VFC_ADAS_ModSts_SLA "SLA mode status, from BJEV ASL spec V0.8";
CM_ SG_ 930 VFC_ADAS_SpdLim_SLA "Speed limit value, from BJEV ASL spec V0.8";
CM_ SG_ 930 VFC_ADAS_SpdLimUnit_SLA "Speed limit unit, from BJEV ASL spec V0.8";
CM_ SG_ 384 RFC_Hdr00_CRC "CRC - Autosar E2E Profile 5";
CM_ SG_ 384 RFC_Hdr00_AliveCtr "Alive counter - Autosar E2E Profile 5";
CM_ SG_ 384 RFC_Hdr00_ProtBlockCtr "Protocol-Signal: Block-Counter";
CM_ SG_ 384 RFC_Hdr00_ProtocolVersion "Protocol version to be send: 0x0004 = V0.4 (Checked-In Version)";
CM_ SG_ 384 RFC_Hdr00_ProtLocationCount "number of detected VALID Locations that have been sent to the bus";
CM_ SG_ 384 RFC_Hdr00_SensorState "The sensor shall provide its operation state.
In case of multiple errors the most severe state shall be sent.";
CM_ SG_ 384 RFC_Hdr00_TimeStamp "Time Stamp";
CM_ SG_ 384 RFC_Hdr00_TimeStampStatus "Autosar StbM_TimeBaseStatusType bitfield with extension:
Bit 0: TIMEOUT
Bit 1: Reserved1
Bit 2: SYNC_TO_GATEWAY
Bit 3: GLOBAL_TIME_BASE
Bit 4: TIMELEAP_FUTURE
Bit 5: TIMELEAP_PAST
Bit 6: Reserved6
Bit 7: Extension: GENERAL_ERROR";
CM_ SG_ 384 RFC_Hdr00_LocDownSel "the detected number of locations exceeded the number of max. objects that can be transmitted";
CM_ SG_ 384 RFC_Hdr00_BliThetaVld "Validity flag RFC_Hdr00_BliTheta";
CM_ SG_ 384 RFC_Hdr00_BliThetaSIMOVld "Validity flag RFC_Hdr00_BliThetaSIMO";
CM_ SG_ 384 RFC_Hdr00_BliThetaMIMOVld "Validity flag RFC_Hdr00_BliThetaMIMO";
CM_ SG_ 384 RFC_Hdr00_BliThetaSIMOShareVld "Validity flag RFC_Hdr00_BliThetaSIMOShare";
CM_ SG_ 384 RFC_Hdr00_BliThetaMIMOShareVld "Validity flag RFC_Hdr00_BliThetaMIMOShare";
CM_ SG_ 384 RFC_Hdr00_BliPhiVld "Validity flag RFC_Hdr00_BliPhi";
CM_ SG_ 384 RFC_Hdr00_BliRCSMOVld "Validity flag RFC_Hdr00_BliRCSMO";
CM_ SG_ 384 RFC_Hdr00_BliBinOverThresholdVld "Validity flag RFC_Hdr00_BliBinsOverThreshold";
CM_ SG_ 384 RFC_Hdr00_BliNumValidReflectVld "Validity flag RFC_Hdr00_BliNumValidReflections";
CM_ SG_ 384 RFC_Hdr00_BliTheta "Blindness Average Overall Azimuth Angle Quality";
CM_ SG_ 384 RFC_Hdr00_BliThetaSIMO "Blindness Average Azimuth Angle Quality for SIMO Angles";
CM_ SG_ 384 RFC_Hdr00_BliThetaMIMO "Blindness Average Azimuth Angle Quality for MIMO Angles";
CM_ SG_ 384 RFC_Hdr00_BliThetaSIMOShare "Blindness High SIMO Azimuth Angle Quality Share";
CM_ SG_ 384 RFC_Hdr00_BliThetaMIMOShare "Blindness High MIMO Azimuth Angle Quality Share";
CM_ SG_ 384 RFC_Hdr00_BliPhi "Blindness High Elevation Angle Quality Share";
CM_ SG_ 384 RFC_Hdr00_BliRCSMO "Blindness RCS Indicator for Moving Objects";
CM_ SG_ 384 RFC_Hdr00_BliBinsOverThreshold "Blindness Number of Bins over Detection Threshold";
CM_ SG_ 384 RFC_Hdr00_BliNumValidReflections "Blindness Number of Valid Reflections";
CM_ SG_ 384 RFC_Hdr00_BliCrossCorrSO "Blindness Cross correlation indicator for stationary objects";
CM_ SG_ 384 RFC_Hdr00_BliCrossCorrSOVld "Validity flag RFC_Hdr00_BliCrossCorrSO";
CM_ SG_ 385 RFC_Hdr01_PersVerWriteCnt03 "Version and write counter";
CM_ SG_ 385 RFC_Hdr01_PersVerWriteCnt02 "Version and write counter";
CM_ SG_ 385 RFC_Hdr01_PersVerWriteCnt01 "Version and write counter";
CM_ SG_ 385 RFC_Hdr01_CRC "CRC - Autosar E2E Profile 5";
CM_ SG_ 385 RFC_Hdr01_AliveCtr "Alive counter - Autosar E2E Profile 5";
CM_ SG_ 385 RFC_Hdr01_ProtBlockCtr "Protocol-Signal: Block-Counter";
CM_ SG_ 385 RFC_Hdr01_PersVerWriteCnt00 "Version and write counter";
CM_ SG_ 385 RFC_Hdr01_PersAngIndAzi "Indicator of current mounting position, mounting angle in azi";
CM_ SG_ 385 RFC_Hdr01_PersAngIndElev "Indicator of current mounting position, mounting angle in elev.";
CM_ SG_ 385 RFC_Hdr01_PersAngIndAziMean "Indicator of current mounting position, mean az angle.";
CM_ SG_ 385 RFC_Hdr01_PersAngIndElevMean "Indicator of current mounting position, mean el angle.";
CM_ SG_ 385 RFC_Hdr01_PersAngIndAziVnce "Indicator of current mounting position, az angle variance";
CM_ SG_ 385 RFC_Hdr01_PersAngIndElevVnce "Indicator of current mounting position, el angle variance";
CM_ SG_ 385 RFC_Hdr01_PersAngIndAziElevCov "Indicator of current mounting position, az el angle covariance.";
CM_ SG_ 385 RFC_Hdr01_PersAngCurrAzi "Current mounting position, mounting angle in az.";
CM_ SG_ 385 RFC_Hdr01_PersAngCurrElev "Current mounting position, mounting angle in el.";
CM_ SG_ 385 RFC_Hdr01_PersAngCurrAziMean "Current mounting position, mean az angle.";
CM_ SG_ 385 RFC_Hdr01_PersAngCurrElevMean "Current mounting position, mean el angle.";
CM_ SG_ 385 RFC_Hdr01_PersAngCurrAziVnce "Current mounting position, az angle variance.";
CM_ SG_ 385 RFC_Hdr01_PersAngCurrElevVnce "Current mounting position, el angle variance.";
CM_ SG_ 385 RFC_Hdr01_PersAngCurrAziElevCov "Current mounting position, az el angle covariance.";
CM_ SG_ 386 RFC_Hdr02_ModPerfDMax "maximal measurable distance";
CM_ SG_ 386 RFC_Hdr02_CRC "CRC - Autosar E2E Profile 5";
CM_ SG_ 386 RFC_Hdr02_AliveCtr "Alive counter - Autosar E2E Profile 5";
CM_ SG_ 386 RFC_Hdr02_ProtBlockCtr "Protocol-Signal: Block-Counter";
CM_ SG_ 386 RFC_Hdr02_PersFiltDspMalIndAzi "Learned filter weights for indicator and current mounting in az, weight for indicator";
CM_ SG_ 386 RFC_Hdr02_PersFiltWeightIndAzi "Learned filter weights for indicator and current mounting in az, mean weight for indicator";
CM_ SG_ 386 RFC_Hdr02_PersFiltDspCurrAzi "Learned filter weights for indicator and current mounting in az, weight for current mounting";
CM_ SG_ 386 RFC_Hdr02_PersFiltDspMalIndElev "Learned filter weights for indicator and current mounting in el, weight for indicator";
CM_ SG_ 386 RFC_Hdr02_PersFiltWeightIndElev "Learned filter weights for indicator and current mounting in el, mean weight for indicator";
CM_ SG_ 386 RFC_Hdr02_PersFiltDspCurrElev "Learned filter weights for indicator and current mounting in el, weight for current mounting";
CM_ SG_ 386 RFC_Hdr02_PersMalStablePosAzi "stable position in az.";
CM_ SG_ 386 RFC_Hdr02_PersMalStablePosElev "stable position in el.";
CM_ SG_ 386 RFC_Hdr02_PersChDetPozAzi "data of change detector, az positive change";
CM_ SG_ 386 RFC_Hdr02_PersChDetNegAzi "data of change detector, az negtive change";
CM_ SG_ 386 RFC_Hdr02_PersChDetPozElev "data of change detector el positive change";
CM_ SG_ 386 RFC_Hdr02_PersChDetNegElev "data of change detector, el negtiive change";
CM_ SG_ 386 RFC_Hdr02_MntAziCur "Sensor mounting angle azimuth current";
CM_ SG_ 386 RFC_Hdr02_MntElevCur "Sensor mounting angle elevation current";
CM_ SG_ 386 RFC_Hdr02_PersOutOfSpecAzi "out of spec status (azimuth oos status)";
CM_ SG_ 386 RFC_Hdr02_PersOutOfSpecElev "out of spec status (elevation oos status)";
CM_ SG_ 387 RFC_Hdr03_CRC "CRC - Autosar E2E Profile 5";
CM_ SG_ 387 RFC_Hdr03_AliveCtr "Alive counter - Autosar E2E Profile 5";
CM_ SG_ 387 RFC_Hdr03_ProtBlockCtr "Protocol-Signal: Block-Counter";
CM_ SG_ 387 RFC_Hdr03_FoVdMaxTheta00 "FoV range for 10m^2 target at azimuth angle 00";
CM_ SG_ 387 RFC_Hdr03_FoVdMaxTheta01 "FoV range for 10m^2 target at azimuth angle 01";
CM_ SG_ 387 RFC_Hdr03_FoVdMaxTheta02 "FoV range for 10m^2 target at azimuth angle 02";
CM_ SG_ 387 RFC_Hdr03_FoVdMaxTheta03 "FoV range for 10m^2 target at azimuth angle 03";
CM_ SG_ 387 RFC_Hdr03_FoVdMaxTheta04 "FoV range for 10m^2 target at azimuth angle 04";
CM_ SG_ 387 RFC_Hdr03_FoVdMaxTheta05 "FoV range for 10m^2 target at azimuth angle 05";
CM_ SG_ 387 RFC_Hdr03_FoVdMaxTheta06 "FoV range for 10m^2 target at azimuth angle 06";
CM_ SG_ 387 RFC_Hdr03_FoVdMaxTheta07 "FoV range for 10m^2 target at azimuth angle 07";
CM_ SG_ 387 RFC_Hdr03_FoVdMaxTheta08 "FoV range for 10m^2 target at azimuth angle 08";
CM_ SG_ 387 RFC_Hdr03_FoVdMaxTheta09 "FoV range for 10m^2 target at azimuth angle 09";
CM_ SG_ 387 RFC_Hdr03_FoVdMaxTheta10 "FoV range for 10m^2 target at azimuth angle 10";
CM_ SG_ 387 RFC_Hdr03_FoVdMaxTheta11 "FoV range for 10m^2 target at azimuth angle 11";
CM_ SG_ 387 RFC_Hdr03_FoVdMaxTheta12 "FoV range for 10m^2 target at azimuth angle 12";
CM_ SG_ 387 RFC_Hdr03_FoVdMaxTheta13 "FoV range for 10m^2 target at azimuth angle 13";
CM_ SG_ 387 RFC_Hdr03_FoVdMaxTheta14 "FoV range for 10m^2 target at azimuth angle 14";
CM_ SG_ 387 RFC_Hdr03_FoVdMaxTheta15 "FoV range for 10m^2 target at azimuth angle 15";
CM_ SG_ 387 RFC_Hdr03_FoVdMaxTheta16 "FoV range for 10m^2 target at azimuth angle 16";
CM_ SG_ 387 RFC_Hdr03_FoVdMaxTheta17 "FoV range for 10m^2 target at azimuth angle 17";
CM_ SG_ 387 RFC_Hdr03_FoVdMaxTheta18 "FoV range for 10m^2 target at azimuth angle 18";
CM_ SG_ 387 RFC_Hdr03_FoVdMaxTheta19 "FoV range for 10m^2 target at azimuth angle 19";
CM_ SG_ 387 RFC_Hdr03_FoVdMaxTheta20 "FoV range for 10m^2 target at azimuth angle 20";
CM_ SG_ 387 RFC_Hdr03_FoVdMaxTheta21 "FoV range for 10m^2 target at azimuth angle 21";
CM_ SG_ 387 RFC_Hdr03_FoVdMaxTheta22 "FoV range for 10m^2 target at azimuth angle 22";
CM_ SG_ 387 RFC_Hdr03_FoVdMaxTheta23 "FoV range for 10m^2 target at azimuth angle 23";
CM_ SG_ 387 RFC_Hdr03_FoVdMaxTheta24 "FoV range for 10m^2 target at azimuth angle 24";
CM_ SG_ 387 RFC_Hdr03_FoVdMaxPhi00 "FoV Range scaling for elevation angle 00";
CM_ SG_ 387 RFC_Hdr03_FoVTheta00 "FoV azimuth angle array 00";
CM_ SG_ 387 RFC_Hdr03_FoVTheta01 "FoV azimuth angle array 01";
CM_ SG_ 387 RFC_Hdr03_FoVTheta02 "FoV azimuth angle array 02";
CM_ SG_ 387 RFC_Hdr03_FoVTheta03 "FoV azimuth angle array 03";
CM_ SG_ 387 RFC_Hdr03_FoVTheta04 "FoV azimuth angle array 04";
CM_ SG_ 387 RFC_Hdr03_FoVTheta05 "FoV azimuth angle array 05";
CM_ SG_ 387 RFC_Hdr03_FoVTheta06 "FoV azimuth angle array 06";
CM_ SG_ 387 RFC_Hdr03_FoVTheta07 "FoV azimuth angle array 07";
CM_ SG_ 387 RFC_Hdr03_FoVTheta08 "FoV azimuth angle array 08";
CM_ SG_ 387 RFC_Hdr03_FoVTheta09 "FoV azimuth angle array 09";
CM_ SG_ 387 RFC_Hdr03_FoVTheta10 "FoV azimuth angle array 10";
CM_ SG_ 387 RFC_Hdr03_FoVTheta11 "FoV azimuth angle array 11";
CM_ SG_ 387 RFC_Hdr03_FoVTheta12 "FoV azimuth angle array 12";
CM_ SG_ 387 RFC_Hdr03_FoVTheta13 "FoV azimuth angle array 13";
CM_ SG_ 387 RFC_Hdr03_FoVTheta14 "FoV azimuth angle array 14";
CM_ SG_ 387 RFC_Hdr03_FoVTheta15 "FoV azimuth angle array 15";
CM_ SG_ 387 RFC_Hdr03_FoVTheta16 "FoV azimuth angle array 16";
CM_ SG_ 387 RFC_Hdr03_FoVTheta17 "FoV azimuth angle array 17";
CM_ SG_ 387 RFC_Hdr03_FoVTheta18 "FoV azimuth angle array 18";
CM_ SG_ 387 RFC_Hdr03_FoVTheta19 "FoV azimuth angle array 19";
CM_ SG_ 387 RFC_Hdr03_FoVTheta20 "FoV azimuth angle array 20";
CM_ SG_ 387 RFC_Hdr03_FoVTheta21 "FoV azimuth angle array 21";
CM_ SG_ 387 RFC_Hdr03_FoVTheta22 "FoV azimuth angle array 22";
CM_ SG_ 387 RFC_Hdr03_FoVTheta23 "FoV azimuth angle array 23";
CM_ SG_ 387 RFC_Hdr03_FoVTheta24 "FoV azimuth angle array 24";
CM_ SG_ 387 RFC_Hdr03_FoVdMaxPhi01 "FoV Range scaling for elevation angle 01";
CM_ SG_ 387 RFC_Hdr03_FoVdMaxPhi02 "FoV Range scaling for elevation angle 02";
CM_ SG_ 387 RFC_Hdr03_FoVdMaxPhi03 "FoV Range scaling for elevation angle 03";
CM_ SG_ 387 RFC_Hdr03_FoVdMaxPhi04 "FoV Range scaling for elevation angle 04";
CM_ SG_ 387 RFC_Hdr03_FoVdMaxPhi05 "FoV Range scaling for elevation angle 05";
CM_ SG_ 387 RFC_Hdr03_FoVdMaxPhi06 "FoV Range scaling for elevation angle 06";
CM_ SG_ 388 RFC_Hdr04_CRC "CRC - Autosar E2E Profile 5";
CM_ SG_ 388 RFC_Hdr04_AliveCtr "Alive counter - Autosar E2E Profile 5";
CM_ SG_ 388 RFC_Hdr04_ProtBlockCtr "Protocol-Signal: Block-Counter";
CM_ SG_ 388 RFC_Hdr04_FoVdMaxPhi07 "FoV Range scaling for elevation angle 07";
CM_ SG_ 388 RFC_Hdr04_FoVdMaxPhi08 "FoV Range scaling for elevation angle 08";
CM_ SG_ 388 RFC_Hdr04_FoVdMaxPhi09 "FoV Range scaling for elevation angle 09";
CM_ SG_ 388 RFC_Hdr04_FoVdMaxPhi10 "FoV Range scaling for elevation angle 10";
CM_ SG_ 388 RFC_Hdr04_FoVPhi00 "FoV elevation angle array 00";
CM_ SG_ 388 RFC_Hdr04_FoVPhi01 "FoV elevation angle array 01";
CM_ SG_ 388 RFC_Hdr04_FoVPhi02 "FoV elevation angle array 02";
CM_ SG_ 388 RFC_Hdr04_FoVPhi03 "FoV elevation angle array 03";
CM_ SG_ 388 RFC_Hdr04_FoVPhi04 "FoV elevation angle array 04";
CM_ SG_ 388 RFC_Hdr04_FoVPhi05 "FoV elevation angle array 05";
CM_ SG_ 388 RFC_Hdr04_FoVPhi06 "FoV elevation angle array 06";
CM_ SG_ 388 RFC_Hdr04_FoVPhi07 "FoV elevation angle array 07";
CM_ SG_ 388 RFC_Hdr04_FoVPhi08 "FoV elevation angle array 08";
CM_ SG_ 388 RFC_Hdr04_FoVPhi09 "FoV elevation angle array 09";
CM_ SG_ 388 RFC_Hdr04_FoVPhi10 "FoV elevation angle array 10";
CM_ SG_ 388 RFC_Hdr04_MntPosX "Sensor mounting X position in vehile FOR";
CM_ SG_ 388 RFC_Hdr04_MntPosY "Sensor mounting Y position in vehile FOR";
CM_ SG_ 388 RFC_Hdr04_MntPosZ "Sensor mounting Z position in vehile FOR";
CM_ SG_ 388 RFC_Hdr04_MntAziNom "Sensor mounting angle azimuth norminal";
CM_ SG_ 388 RFC_Hdr04_MntElevNom "Sensor mounting angle elevation norminal";
CM_ SG_ 388 RFC_Hdr04_InitCov "Initial CoVariance Factor";
CM_ SG_ 388 RFC_Hdr04_TspMeasID "TimeStamp Pair measurement ID";
CM_ SG_ 388 RFC_Hdr04_TspSensID "TimeStamp Pair sensor ID";
CM_ SG_ 388 RFC_Hdr04_TspLastMeas "TimeStamp Pair last measurement time stamp";
CM_ SG_ 388 RFC_Hdr04_TspLastRec "TimeStamp Pair last reception time stamp";
CM_ SG_ 388 RFC_Hdr04_TspPredMeas "TimeStamp Pair predicted measurement time stamp";
CM_ SG_ 388 RFC_Hdr04_TspPredRec "TimeStamp Pair predected reception time stamp";
CM_ SG_ 400 RFC_Loc000_CRC "CRC - Autosar E2E Profile 5, DataID = TBD";
CM_ SG_ 400 RFC_Loc000_AliveCtr "Alive counter - Autosar E2E Profile 5";
CM_ SG_ 400 RFC_Loc000_ProtBlockCtr "Protocol-Signal: Block-Counter";
CM_ SG_ 400 RFC_Loc000_Dr "Location radial distance";
CM_ SG_ 400 RFC_Loc000_Vr "Location radial relative velocity";
CM_ SG_ 400 RFC_Loc000_Theta "Location azimuth angle. \"Not a number\" TBD";
CM_ SG_ 400 RFC_Loc000_Phi "Location elevation angle. \"Not a number\" TBD";
CM_ SG_ 400 RFC_Loc000_DrVnce "Variance of Location radial distance";
CM_ SG_ 400 RFC_Loc000_VrVnce "Variance of Location radial relative velocity";
CM_ SG_ 400 RFC_Loc000_ThetaVnce "Variance of Location azimuth angle";
CM_ SG_ 400 RFC_Loc000_PhiVnce "Variance of Location elevation angle";
CM_ SG_ 400 RFC_Loc000_DrVrCoVnce "Covariance of Dr and Vr";
CM_ SG_ 400 RFC_Loc000_RCS "Radar Cross Section (RCS) estimation";
CM_ SG_ 400 RFC_Loc000_RSSI "Received Signal Strength Indication (RSSI)";
CM_ SG_ 400 RFC_Loc000_DrVrQuality "Quality of radial distance and velocity resolution processing. Physical range [0..1]";
CM_ SG_ 400 RFC_Loc000_ThetaQuality "Probability for correct signal model (azimuth angle). Physical range [0..1]";
CM_ SG_ 400 RFC_Loc000_PhiQuality "Probability for correct signal model (elevation angle). Physical range [0..1]";
CM_ SG_ 400 RFC_Loc001_Dr "Location radial distance";
CM_ SG_ 400 RFC_Loc001_Vr "Location radial relative velocity";
CM_ SG_ 400 RFC_Loc001_Theta "Location azimuth angle. \"Not a number\" TBD";
CM_ SG_ 400 RFC_Loc001_Phi "Location elevation angle. \"Not a number\" TBD";
CM_ SG_ 400 RFC_Loc001_DrVnce "Variance of Location radial distance";
CM_ SG_ 400 RFC_Loc001_VrVnce "Variance of Location radial relative velocity";
CM_ SG_ 400 RFC_Loc001_ThetaVnce "Variance of Location azimuth angle";
CM_ SG_ 400 RFC_Loc001_PhiVnce "Variance of Location elevation angle";
CM_ SG_ 400 RFC_Loc001_DrVrCoVnce "Covariance of Dr and Vr";
CM_ SG_ 400 RFC_Loc001_RCS "Radar Cross Section (RCS) estimation";
CM_ SG_ 400 RFC_Loc001_RSSI "Received Signal Strength Indication (RSSI)";
CM_ SG_ 400 RFC_Loc001_DrVrQuality "Quality of radial distance and velocity resolution processing. Physical range [0..1]";
CM_ SG_ 400 RFC_Loc001_ThetaQuality "Probability for correct signal model (azimuth angle). Physical range [0..1]";
CM_ SG_ 400 RFC_Loc001_PhiQuality "Probability for correct signal model (elevation angle). Physical range [0..1]";
CM_ SG_ 401 RFC_Loc002_CRC "CRC - Autosar E2E Profile 5, DataID = TBD";
CM_ SG_ 401 RFC_Loc002_AliveCtr "Alive counter - Autosar E2E Profile 5";
CM_ SG_ 401 RFC_Loc002_ProtBlockCtr "Protocol-Signal: Block-Counter";
CM_ SG_ 401 RFC_Loc002_Dr "Location radial distance";
CM_ SG_ 401 RFC_Loc002_Vr "Location radial relative velocity";
CM_ SG_ 401 RFC_Loc002_Theta "Location azimuth angle. \"Not a number\" TBD";
CM_ SG_ 401 RFC_Loc002_Phi "Location elevation angle. \"Not a number\" TBD";
CM_ SG_ 401 RFC_Loc002_DrVnce "Variance of Location radial distance";
CM_ SG_ 401 RFC_Loc002_VrVnce "Variance of Location radial relative velocity";
CM_ SG_ 401 RFC_Loc002_ThetaVnce "Variance of Location azimuth angle";
CM_ SG_ 401 RFC_Loc002_PhiVnce "Variance of Location elevation angle";
CM_ SG_ 401 RFC_Loc002_DrVrCoVnce "Covariance of Dr and Vr";
CM_ SG_ 401 RFC_Loc002_RCS "Radar Cross Section (RCS) estimation";
CM_ SG_ 401 RFC_Loc002_RSSI "Received Signal Strength Indication (RSSI)";
CM_ SG_ 401 RFC_Loc002_DrVrQuality "Quality of radial distance and velocity resolution processing. Physical range [0..1]";
CM_ SG_ 401 RFC_Loc002_ThetaQuality "Probability for correct signal model (azimuth angle). Physical range [0..1]";
CM_ SG_ 401 RFC_Loc002_PhiQuality "Probability for correct signal model (elevation angle). Physical range [0..1]";
CM_ SG_ 401 RFC_Loc003_Dr "Location radial distance";
CM_ SG_ 401 RFC_Loc003_Vr "Location radial relative velocity";
CM_ SG_ 401 RFC_Loc003_Theta "Location azimuth angle. \"Not a number\" TBD";
CM_ SG_ 401 RFC_Loc003_Phi "Location elevation angle. \"Not a number\" TBD";
CM_ SG_ 401 RFC_Loc003_DrVnce "Variance of Location radial distance";
CM_ SG_ 401 RFC_Loc003_VrVnce "Variance of Location radial relative velocity";
CM_ SG_ 401 RFC_Loc003_ThetaVnce "Variance of Location azimuth angle";
CM_ SG_ 401 RFC_Loc003_PhiVnce "Variance of Location elevation angle";
CM_ SG_ 401 RFC_Loc003_DrVrCoVnce "Covariance of Dr and Vr";
CM_ SG_ 401 RFC_Loc003_RCS "Radar Cross Section (RCS) estimation";
CM_ SG_ 401 RFC_Loc003_RSSI "Received Signal Strength Indication (RSSI)";
CM_ SG_ 401 RFC_Loc003_DrVrQuality "Quality of radial distance and velocity resolution processing. Physical range [0..1]";
CM_ SG_ 401 RFC_Loc003_ThetaQuality "Probability for correct signal model (azimuth angle). Physical range [0..1]";
CM_ SG_ 401 RFC_Loc003_PhiQuality "Probability for correct signal model (elevation angle). Physical range [0..1]";
CM_ SG_ 402 RFC_Loc004_CRC "CRC - Autosar E2E Profile 5, DataID = TBD";
CM_ SG_ 402 RFC_Loc004_AliveCtr "Alive counter - Autosar E2E Profile 5";
CM_ SG_ 402 RFC_Loc004_ProtBlockCtr "Protocol-Signal: Block-Counter";
CM_ SG_ 402 RFC_Loc004_Dr "Location radial distance";
CM_ SG_ 402 RFC_Loc004_Vr "Location radial relative velocity";
CM_ SG_ 402 RFC_Loc004_Theta "Location azimuth angle. \"Not a number\" TBD";
CM_ SG_ 402 RFC_Loc004_Phi "Location elevation angle. \"Not a number\" TBD";
CM_ SG_ 402 RFC_Loc004_DrVnce "Variance of Location radial distance";
CM_ SG_ 402 RFC_Loc004_VrVnce "Variance of Location radial relative velocity";
CM_ SG_ 402 RFC_Loc004_ThetaVnce "Variance of Location azimuth angle";
CM_ SG_ 402 RFC_Loc004_PhiVnce "Variance of Location elevation angle";
CM_ SG_ 402 RFC_Loc004_DrVrCoVnce "Covariance of Dr and Vr";
CM_ SG_ 402 RFC_Loc004_RCS "Radar Cross Section (RCS) estimation";
CM_ SG_ 402 RFC_Loc004_RSSI "Received Signal Strength Indication (RSSI)";
CM_ SG_ 402 RFC_Loc004_DrVrQuality "Quality of radial distance and velocity resolution processing. Physical range [0..1]";
CM_ SG_ 402 RFC_Loc004_ThetaQuality "Probability for correct signal model (azimuth angle). Physical range [0..1]";
CM_ SG_ 402 RFC_Loc004_PhiQuality "Probability for correct signal model (elevation angle). Physical range [0..1]";
CM_ SG_ 402 RFC_Loc005_Dr "Location radial distance";
CM_ SG_ 402 RFC_Loc005_Vr "Location radial relative velocity";
CM_ SG_ 402 RFC_Loc005_Theta "Location azimuth angle. \"Not a number\" TBD";
CM_ SG_ 402 RFC_Loc005_Phi "Location elevation angle. \"Not a number\" TBD";
CM_ SG_ 402 RFC_Loc005_DrVnce "Variance of Location radial distance";
CM_ SG_ 402 RFC_Loc005_VrVnce "Variance of Location radial relative velocity";
CM_ SG_ 402 RFC_Loc005_ThetaVnce "Variance of Location azimuth angle";
CM_ SG_ 402 RFC_Loc005_PhiVnce "Variance of Location elevation angle";
CM_ SG_ 402 RFC_Loc005_DrVrCoVnce "Covariance of Dr and Vr";
CM_ SG_ 402 RFC_Loc005_RCS "Radar Cross Section (RCS) estimation";
CM_ SG_ 402 RFC_Loc005_RSSI "Received Signal Strength Indication (RSSI)";
CM_ SG_ 402 RFC_Loc005_DrVrQuality "Quality of radial distance and velocity resolution processing. Physical range [0..1]";
CM_ SG_ 402 RFC_Loc005_ThetaQuality "Probability for correct signal model (azimuth angle). Physical range [0..1]";
CM_ SG_ 402 RFC_Loc005_PhiQuality "Probability for correct signal model (elevation angle). Physical range [0..1]";
CM_ SG_ 403 RFC_Loc006_CRC "CRC - Autosar E2E Profile 5, DataID = TBD";
CM_ SG_ 403 RFC_Loc006_AliveCtr "Alive counter - Autosar E2E Profile 5";
CM_ SG_ 403 RFC_Loc006_ProtBlockCtr "Protocol-Signal: Block-Counter";
CM_ SG_ 403 RFC_Loc006_Dr "Location radial distance";
CM_ SG_ 403 RFC_Loc006_Vr "Location radial relative velocity";
CM_ SG_ 403 RFC_Loc006_Theta "Location azimuth angle. \"Not a number\" TBD";
CM_ SG_ 403 RFC_Loc006_Phi "Location elevation angle. \"Not a number\" TBD";
CM_ SG_ 403 RFC_Loc006_DrVnce "Variance of Location radial distance";
CM_ SG_ 403 RFC_Loc006_VrVnce "Variance of Location radial relative velocity";
CM_ SG_ 403 RFC_Loc006_ThetaVnce "Variance of Location azimuth angle";
CM_ SG_ 403 RFC_Loc006_PhiVnce "Variance of Location elevation angle";
CM_ SG_ 403 RFC_Loc006_DrVrCoVnce "Covariance of Dr and Vr";
CM_ SG_ 403 RFC_Loc006_RCS "Radar Cross Section (RCS) estimation";
CM_ SG_ 403 RFC_Loc006_RSSI "Received Signal Strength Indication (RSSI)";
CM_ SG_ 403 RFC_Loc006_DrVrQuality "Quality of radial distance and velocity resolution processing. Physical range [0..1]";
CM_ SG_ 403 RFC_Loc006_ThetaQuality "Probability for correct signal model (azimuth angle). Physical range [0..1]";
CM_ SG_ 403 RFC_Loc006_PhiQuality "Probability for correct signal model (elevation angle). Physical range [0..1]";
CM_ SG_ 403 RFC_Loc007_Dr "Location radial distance";
CM_ SG_ 403 RFC_Loc007_Vr "Location radial relative velocity";
CM_ SG_ 403 RFC_Loc007_Theta "Location azimuth angle. \"Not a number\" TBD";
CM_ SG_ 403 RFC_Loc007_Phi "Location elevation angle. \"Not a number\" TBD";
CM_ SG_ 403 RFC_Loc007_DrVnce "Variance of Location radial distance";
CM_ SG_ 403 RFC_Loc007_VrVnce "Variance of Location radial relative velocity";
CM_ SG_ 403 RFC_Loc007_ThetaVnce "Variance of Location azimuth angle";
CM_ SG_ 403 RFC_Loc007_PhiVnce "Variance of Location elevation angle";
CM_ SG_ 403 RFC_Loc007_DrVrCoVnce "Covariance of Dr and Vr";
CM_ SG_ 403 RFC_Loc007_RCS "Radar Cross Section (RCS) estimation";
CM_ SG_ 403 RFC_Loc007_RSSI "Received Signal Strength Indication (RSSI)";
CM_ SG_ 403 RFC_Loc007_DrVrQuality "Quality of radial distance and velocity resolution processing. Physical range [0..1]";
CM_ SG_ 403 RFC_Loc007_ThetaQuality "Probability for correct signal model (azimuth angle). Physical range [0..1]";
CM_ SG_ 403 RFC_Loc007_PhiQuality "Probability for correct signal model (elevation angle). Physical range [0..1]";
CM_ SG_ 404 RFC_Loc008_CRC "CRC - Autosar E2E Profile 5, DataID = TBD";
CM_ SG_ 404 RFC_Loc008_AliveCtr "Alive counter - Autosar E2E Profile 5";
CM_ SG_ 404 RFC_Loc008_ProtBlockCtr "Protocol-Signal: Block-Counter";
CM_ SG_ 404 RFC_Loc008_Dr "Location radial distance";
CM_ SG_ 404 RFC_Loc008_Vr "Location radial relative velocity";
CM_ SG_ 404 RFC_Loc008_Theta "Location azimuth angle. \"Not a number\" TBD";
CM_ SG_ 404 RFC_Loc008_Phi "Location elevation angle. \"Not a number\" TBD";
CM_ SG_ 404 RFC_Loc008_DrVnce "Variance of Location radial distance";
CM_ SG_ 404 RFC_Loc008_VrVnce "Variance of Location radial relative velocity";
CM_ SG_ 404 RFC_Loc008_ThetaVnce "Variance of Location azimuth angle";
CM_ SG_ 404 RFC_Loc008_PhiVnce "Variance of Location elevation angle";
CM_ SG_ 404 RFC_Loc008_DrVrCoVnce "Covariance of Dr and Vr";
CM_ SG_ 404 RFC_Loc008_RCS "Radar Cross Section (RCS) estimation";
CM_ SG_ 404 RFC_Loc008_RSSI "Received Signal Strength Indication (RSSI)";
CM_ SG_ 404 RFC_Loc008_DrVrQuality "Quality of radial distance and velocity resolution processing. Physical range [0..1]";
CM_ SG_ 404 RFC_Loc008_ThetaQuality "Probability for correct signal model (azimuth angle). Physical range [0..1]";
CM_ SG_ 404 RFC_Loc008_PhiQuality "Probability for correct signal model (elevation angle). Physical range [0..1]";
CM_ SG_ 404 RFC_Loc009_Dr "Location radial distance";
CM_ SG_ 404 RFC_Loc009_Vr "Location radial relative velocity";
CM_ SG_ 404 RFC_Loc009_Theta "Location azimuth angle. \"Not a number\" TBD";
CM_ SG_ 404 RFC_Loc009_Phi "Location elevation angle. \"Not a number\" TBD";
CM_ SG_ 404 RFC_Loc009_DrVnce "Variance of Location radial distance";
CM_ SG_ 404 RFC_Loc009_VrVnce "Variance of Location radial relative velocity";
CM_ SG_ 404 RFC_Loc009_ThetaVnce "Variance of Location azimuth angle";
CM_ SG_ 404 RFC_Loc009_PhiVnce "Variance of Location elevation angle";
CM_ SG_ 404 RFC_Loc009_DrVrCoVnce "Covariance of Dr and Vr";
CM_ SG_ 404 RFC_Loc009_RCS "Radar Cross Section (RCS) estimation";
CM_ SG_ 404 RFC_Loc009_RSSI "Received Signal Strength Indication (RSSI)";
CM_ SG_ 404 RFC_Loc009_DrVrQuality "Quality of radial distance and velocity resolution processing. Physical range [0..1]";
CM_ SG_ 404 RFC_Loc009_ThetaQuality "Probability for correct signal model (azimuth angle). Physical range [0..1]";
CM_ SG_ 404 RFC_Loc009_PhiQuality "Probability for correct signal model (elevation angle). Physical range [0..1]";
CM_ SG_ 405 RFC_Loc010_CRC "CRC - Autosar E2E Profile 5, DataID = TBD";
CM_ SG_ 405 RFC_Loc010_AliveCtr "Alive counter - Autosar E2E Profile 5";
CM_ SG_ 405 RFC_Loc010_ProtBlockCtr "Protocol-Signal: Block-Counter";
CM_ SG_ 405 RFC_Loc010_Dr "Location radial distance";
CM_ SG_ 405 RFC_Loc010_Vr "Location radial relative velocity";
CM_ SG_ 405 RFC_Loc010_Theta "Location azimuth angle. \"Not a number\" TBD";
CM_ SG_ 405 RFC_Loc010_Phi "Location elevation angle. \"Not a number\" TBD";
CM_ SG_ 405 RFC_Loc010_DrVnce "Variance of Location radial distance";
CM_ SG_ 405 RFC_Loc010_VrVnce "Variance of Location radial relative velocity";
CM_ SG_ 405 RFC_Loc010_ThetaVnce "Variance of Location azimuth angle";
CM_ SG_ 405 RFC_Loc010_PhiVnce "Variance of Location elevation angle";
CM_ SG_ 405 RFC_Loc010_DrVrCoVnce "Covariance of Dr and Vr";
CM_ SG_ 405 RFC_Loc010_RCS "Radar Cross Section (RCS) estimation";
CM_ SG_ 405 RFC_Loc010_RSSI "Received Signal Strength Indication (RSSI)";
CM_ SG_ 405 RFC_Loc010_DrVrQuality "Quality of radial distance and velocity resolution processing. Physical range [0..1]";
CM_ SG_ 405 RFC_Loc010_ThetaQuality "Probability for correct signal model (azimuth angle). Physical range [0..1]";
CM_ SG_ 405 RFC_Loc010_PhiQuality "Probability for correct signal model (elevation angle). Physical range [0..1]";
CM_ SG_ 405 RFC_Loc011_Dr "Location radial distance";
CM_ SG_ 405 RFC_Loc011_Vr "Location radial relative velocity";
CM_ SG_ 405 RFC_Loc011_Theta "Location azimuth angle. \"Not a number\" TBD";
CM_ SG_ 405 RFC_Loc011_Phi "Location elevation angle. \"Not a number\" TBD";
CM_ SG_ 405 RFC_Loc011_DrVnce "Variance of Location radial distance";
CM_ SG_ 405 RFC_Loc011_VrVnce "Variance of Location radial relative velocity";
CM_ SG_ 405 RFC_Loc011_ThetaVnce "Variance of Location azimuth angle";
CM_ SG_ 405 RFC_Loc011_PhiVnce "Variance of Location elevation angle";
CM_ SG_ 405 RFC_Loc011_DrVrCoVnce "Covariance of Dr and Vr";
CM_ SG_ 405 RFC_Loc011_RCS "Radar Cross Section (RCS) estimation";
CM_ SG_ 405 RFC_Loc011_RSSI "Received Signal Strength Indication (RSSI)";
CM_ SG_ 405 RFC_Loc011_DrVrQuality "Quality of radial distance and velocity resolution processing. Physical range [0..1]";
CM_ SG_ 405 RFC_Loc011_ThetaQuality "Probability for correct signal model (azimuth angle). Physical range [0..1]";
CM_ SG_ 405 RFC_Loc011_PhiQuality "Probability for correct signal model (elevation angle). Physical range [0..1]";
CM_ SG_ 406 RFC_Loc012_CRC "CRC - Autosar E2E Profile 5, DataID = TBD";
CM_ SG_ 406 RFC_Loc012_AliveCtr "Alive counter - Autosar E2E Profile 5";
CM_ SG_ 406 RFC_Loc012_ProtBlockCtr "Protocol-Signal: Block-Counter";
CM_ SG_ 406 RFC_Loc012_Dr "Location radial distance";
CM_ SG_ 406 RFC_Loc012_Vr "Location radial relative velocity";
CM_ SG_ 406 RFC_Loc012_Theta "Location azimuth angle. \"Not a number\" TBD";
CM_ SG_ 406 RFC_Loc012_Phi "Location elevation angle. \"Not a number\" TBD";
CM_ SG_ 406 RFC_Loc012_DrVnce "Variance of Location radial distance";
CM_ SG_ 406 RFC_Loc012_VrVnce "Variance of Location radial relative velocity";
CM_ SG_ 406 RFC_Loc012_ThetaVnce "Variance of Location azimuth angle";
CM_ SG_ 406 RFC_Loc012_PhiVnce "Variance of Location elevation angle";
CM_ SG_ 406 RFC_Loc012_DrVrCoVnce "Covariance of Dr and Vr";
CM_ SG_ 406 RFC_Loc012_RCS "Radar Cross Section (RCS) estimation";
CM_ SG_ 406 RFC_Loc012_RSSI "Received Signal Strength Indication (RSSI)";
CM_ SG_ 406 RFC_Loc012_DrVrQuality "Quality of radial distance and velocity resolution processing. Physical range [0..1]";
CM_ SG_ 406 RFC_Loc012_ThetaQuality "Probability for correct signal model (azimuth angle). Physical range [0..1]";
CM_ SG_ 406 RFC_Loc012_PhiQuality "Probability for correct signal model (elevation angle). Physical range [0..1]";
CM_ SG_ 406 RFC_Loc013_Dr "Location radial distance";
CM_ SG_ 406 RFC_Loc013_Vr "Location radial relative velocity";
CM_ SG_ 406 RFC_Loc013_Theta "Location azimuth angle. \"Not a number\" TBD";
CM_ SG_ 406 RFC_Loc013_Phi "Location elevation angle. \"Not a number\" TBD";
CM_ SG_ 406 RFC_Loc013_DrVnce "Variance of Location radial distance";
CM_ SG_ 406 RFC_Loc013_VrVnce "Variance of Location radial relative velocity";
CM_ SG_ 406 RFC_Loc013_ThetaVnce "Variance of Location azimuth angle";
CM_ SG_ 406 RFC_Loc013_PhiVnce "Variance of Location elevation angle";
CM_ SG_ 406 RFC_Loc013_DrVrCoVnce "Covariance of Dr and Vr";
CM_ SG_ 406 RFC_Loc013_RCS "Radar Cross Section (RCS) estimation";
CM_ SG_ 406 RFC_Loc013_RSSI "Received Signal Strength Indication (RSSI)";
CM_ SG_ 406 RFC_Loc013_DrVrQuality "Quality of radial distance and velocity resolution processing. Physical range [0..1]";
CM_ SG_ 406 RFC_Loc013_ThetaQuality "Probability for correct signal model (azimuth angle). Physical range [0..1]";
CM_ SG_ 406 RFC_Loc013_PhiQuality "Probability for correct signal model (elevation angle). Physical range [0..1]";
CM_ SG_ 407 RFC_Loc014_CRC "CRC - Autosar E2E Profile 5, DataID = TBD";
CM_ SG_ 407 RFC_Loc014_AliveCtr "Alive counter - Autosar E2E Profile 5";
CM_ SG_ 407 RFC_Loc014_ProtBlockCtr "Protocol-Signal: Block-Counter";
CM_ SG_ 407 RFC_Loc014_Dr "Location radial distance";
CM_ SG_ 407 RFC_Loc014_Vr "Location radial relative velocity";
CM_ SG_ 407 RFC_Loc014_Theta "Location azimuth angle. \"Not a number\" TBD";
CM_ SG_ 407 RFC_Loc014_Phi "Location elevation angle. \"Not a number\" TBD";
CM_ SG_ 407 RFC_Loc014_DrVnce "Variance of Location radial distance";
CM_ SG_ 407 RFC_Loc014_VrVnce "Variance of Location radial relative velocity";
CM_ SG_ 407 RFC_Loc014_ThetaVnce "Variance of Location azimuth angle";
CM_ SG_ 407 RFC_Loc014_PhiVnce "Variance of Location elevation angle";
CM_ SG_ 407 RFC_Loc014_DrVrCoVnce "Covariance of Dr and Vr";
CM_ SG_ 407 RFC_Loc014_RCS "Radar Cross Section (RCS) estimation";
CM_ SG_ 407 RFC_Loc014_RSSI "Received Signal Strength Indication (RSSI)";
CM_ SG_ 407 RFC_Loc014_DrVrQuality "Quality of radial distance and velocity resolution processing. Physical range [0..1]";
CM_ SG_ 407 RFC_Loc014_ThetaQuality "Probability for correct signal model (azimuth angle). Physical range [0..1]";
CM_ SG_ 407 RFC_Loc014_PhiQuality "Probability for correct signal model (elevation angle). Physical range [0..1]";
CM_ SG_ 407 RFC_Loc015_Dr "Location radial distance";
CM_ SG_ 407 RFC_Loc015_Vr "Location radial relative velocity";
CM_ SG_ 407 RFC_Loc015_Theta "Location azimuth angle. \"Not a number\" TBD";
CM_ SG_ 407 RFC_Loc015_Phi "Location elevation angle. \"Not a number\" TBD";
CM_ SG_ 407 RFC_Loc015_DrVnce "Variance of Location radial distance";
CM_ SG_ 407 RFC_Loc015_VrVnce "Variance of Location radial relative velocity";
CM_ SG_ 407 RFC_Loc015_ThetaVnce "Variance of Location azimuth angle";
CM_ SG_ 407 RFC_Loc015_PhiVnce "Variance of Location elevation angle";
CM_ SG_ 407 RFC_Loc015_DrVrCoVnce "Covariance of Dr and Vr";
CM_ SG_ 407 RFC_Loc015_RCS "Radar Cross Section (RCS) estimation";
CM_ SG_ 407 RFC_Loc015_RSSI "Received Signal Strength Indication (RSSI)";
CM_ SG_ 407 RFC_Loc015_DrVrQuality "Quality of radial distance and velocity resolution processing. Physical range [0..1]";
CM_ SG_ 407 RFC_Loc015_ThetaQuality "Probability for correct signal model (azimuth angle). Physical range [0..1]";
CM_ SG_ 407 RFC_Loc015_PhiQuality "Probability for correct signal model (elevation angle). Physical range [0..1]";
CM_ SG_ 408 RFC_Loc016_CRC "CRC - Autosar E2E Profile 5, DataID = TBD";
CM_ SG_ 408 RFC_Loc016_AliveCtr "Alive counter - Autosar E2E Profile 5";
CM_ SG_ 408 RFC_Loc016_ProtBlockCtr "Protocol-Signal: Block-Counter";
CM_ SG_ 408 RFC_Loc016_Dr "Location radial distance";
CM_ SG_ 408 RFC_Loc016_Vr "Location radial relative velocity";
CM_ SG_ 408 RFC_Loc016_Theta "Location azimuth angle. \"Not a number\" TBD";
CM_ SG_ 408 RFC_Loc016_Phi "Location elevation angle. \"Not a number\" TBD";
CM_ SG_ 408 RFC_Loc016_DrVnce "Variance of Location radial distance";
CM_ SG_ 408 RFC_Loc016_VrVnce "Variance of Location radial relative velocity";
CM_ SG_ 408 RFC_Loc016_ThetaVnce "Variance of Location azimuth angle";
CM_ SG_ 408 RFC_Loc016_PhiVnce "Variance of Location elevation angle";
CM_ SG_ 408 RFC_Loc016_DrVrCoVnce "Covariance of Dr and Vr";
CM_ SG_ 408 RFC_Loc016_RCS "Radar Cross Section (RCS) estimation";
CM_ SG_ 408 RFC_Loc016_RSSI "Received Signal Strength Indication (RSSI)";
CM_ SG_ 408 RFC_Loc016_DrVrQuality "Quality of radial distance and velocity resolution processing. Physical range [0..1]";
CM_ SG_ 408 RFC_Loc016_ThetaQuality "Probability for correct signal model (azimuth angle). Physical range [0..1]";
CM_ SG_ 408 RFC_Loc016_PhiQuality "Probability for correct signal model (elevation angle). Physical range [0..1]";
CM_ SG_ 408 RFC_Loc017_Dr "Location radial distance";
CM_ SG_ 408 RFC_Loc017_Vr "Location radial relative velocity";
CM_ SG_ 408 RFC_Loc017_Theta "Location azimuth angle. \"Not a number\" TBD";
CM_ SG_ 408 RFC_Loc017_Phi "Location elevation angle. \"Not a number\" TBD";
CM_ SG_ 408 RFC_Loc017_DrVnce "Variance of Location radial distance";
CM_ SG_ 408 RFC_Loc017_VrVnce "Variance of Location radial relative velocity";
CM_ SG_ 408 RFC_Loc017_ThetaVnce "Variance of Location azimuth angle";
CM_ SG_ 408 RFC_Loc017_PhiVnce "Variance of Location elevation angle";
CM_ SG_ 408 RFC_Loc017_DrVrCoVnce "Covariance of Dr and Vr";
CM_ SG_ 408 RFC_Loc017_RCS "Radar Cross Section (RCS) estimation";
CM_ SG_ 408 RFC_Loc017_RSSI "Received Signal Strength Indication (RSSI)";
CM_ SG_ 408 RFC_Loc017_DrVrQuality "Quality of radial distance and velocity resolution processing. Physical range [0..1]";
CM_ SG_ 408 RFC_Loc017_ThetaQuality "Probability for correct signal model (azimuth angle). Physical range [0..1]";
CM_ SG_ 408 RFC_Loc017_PhiQuality "Probability for correct signal model (elevation angle). Physical range [0..1]";
BA_DEF_ BO_  "GenMsgSendType" ENUM  "cyclic","NoMsgSendType","IfActive","Event","CA","CE";
BA_DEF_ BO_  "GenMsgCycleTime" INT 0 0;
BA_DEF_ SG_  "GenSigSendType" ENUM  "cyclic","OnChange","OnWrite","IfActive","OnChangeWithRepetition","OnWriteWithRepetition","IfActiveWithRepetition","CA","CE","Event";
BA_DEF_ SG_  "GenSigStartValue" INT 0 0;
BA_DEF_ BO_  "CANFD_BRS" ENUM  "0","1";
BA_DEF_ BO_  "VFrameFormat" ENUM  "StandardCAN","ExtendedCAN","reserved","reserved","reserved","reserved","reserved","reserved","reserved","reserved","reserved","reserved","reserved","reserved","StandardCAN_FD","ExtendedCAN_FD";
BA_DEF_ BO_  "GenMsgILSupport" ENUM  "No","Yes";
BA_DEF_ SG_  "sigDespEng" STRING ;
BA_DEF_ SG_  "sigSecLevel" STRING ;
BA_DEF_ SG_  "sigConfig" STRING ;
BA_DEF_ SG_  "sigExplanation" STRING ;
BA_DEF_DEF_  "GenMsgSendType" "cyclic";
BA_DEF_DEF_  "GenMsgCycleTime" 0;
BA_DEF_DEF_  "GenSigSendType" "cyclic";
BA_DEF_DEF_  "GenSigStartValue" 0;
BA_DEF_DEF_  "CANFD_BRS" "1";
BA_DEF_DEF_  "VFrameFormat" "";
BA_DEF_DEF_  "GenMsgILSupport" "Yes";
BA_DEF_DEF_  "sigDespEng" "";
BA_DEF_DEF_  "sigSecLevel" "";
BA_DEF_DEF_  "sigConfig" "";
BA_DEF_DEF_  "sigExplanation" "";
BA_ "GenMsgSendType" BO_ 250 3;
BA_ "VFrameFormat" BO_ 250 14;
BA_ "GenMsgSendType" BO_ 251 3;
BA_ "VFrameFormat" BO_ 251 14;
BA_ "GenMsgSendType" BO_ 252 3;
BA_ "VFrameFormat" BO_ 252 14;
BA_ "GenMsgSendType" BO_ 253 3;
BA_ "VFrameFormat" BO_ 253 14;
BA_ "GenMsgCycleTime" BO_ 255 500;
BA_ "VFrameFormat" BO_ 255 14;
BA_ "GenMsgCycleTime" BO_ 75 50;
BA_ "VFrameFormat" BO_ 75 14;
BA_ "GenMsgCycleTime" BO_ 74 50;
BA_ "VFrameFormat" BO_ 74 14;
BA_ "GenMsgCycleTime" BO_ 81 50;
BA_ "VFrameFormat" BO_ 81 14;
BA_ "GenMsgCycleTime" BO_ 2281601536 60;
BA_ "VFrameFormat" BO_ 2281601536 15;
BA_ "GenMsgCycleTime" BO_ 931 100;
BA_ "VFrameFormat" BO_ 931 14;
BA_ "GenMsgCycleTime" BO_ 930 100;
BA_ "VFrameFormat" BO_ 930 14;
BA_ "GenMsgSendType" BO_ 384 3;
BA_ "VFrameFormat" BO_ 384 14;
BA_ "GenMsgSendType" BO_ 385 3;
BA_ "VFrameFormat" BO_ 385 14;
BA_ "GenMsgSendType" BO_ 386 3;
BA_ "VFrameFormat" BO_ 386 14;
BA_ "GenMsgSendType" BO_ 387 3;
BA_ "VFrameFormat" BO_ 387 14;
BA_ "GenMsgSendType" BO_ 388 3;
BA_ "VFrameFormat" BO_ 388 14;
BA_ "GenMsgSendType" BO_ 400 3;
BA_ "VFrameFormat" BO_ 400 14;
BA_ "GenMsgSendType" BO_ 401 3;
BA_ "VFrameFormat" BO_ 401 14;
BA_ "GenMsgSendType" BO_ 402 3;
BA_ "VFrameFormat" BO_ 402 14;
BA_ "GenMsgSendType" BO_ 403 3;
BA_ "VFrameFormat" BO_ 403 14;
BA_ "GenMsgSendType" BO_ 404 3;
BA_ "VFrameFormat" BO_ 404 14;
BA_ "GenMsgSendType" BO_ 405 3;
BA_ "VFrameFormat" BO_ 405 14;
BA_ "GenMsgSendType" BO_ 406 3;
BA_ "VFrameFormat" BO_ 406 14;
BA_ "GenMsgSendType" BO_ 407 3;
BA_ "VFrameFormat" BO_ 407 14;
BA_ "GenMsgSendType" BO_ 408 3;
BA_ "VFrameFormat" BO_ 408 14;
BA_ "GenSigStartValue" SG_ 250 VFC_TS12_Dy 128;
BA_ "GenSigStartValue" SG_ 251 VFC_TS13_Dy 128;
BA_ "GenSigStartValue" SG_ 252 VFC_TS14_Dy 128;
BA_ "GenSigStartValue" SG_ 74 ADAS_FrntTar1Y_ACC 127;
BA_ "GenSigStartValue" SG_ 931 VFC_MapInfo_RoadCurv 2047;
BA_ "GenSigSendType" SG_ 384 RFC_Hdr00_CRC 9;
BA_ "GenSigSendType" SG_ 384 RFC_Hdr00_AliveCtr 9;
BA_ "GenSigSendType" SG_ 384 RFC_Hdr00_ProtBlockCtr 9;
BA_ "GenSigSendType" SG_ 384 RFC_Hdr00_ProtocolVersion 9;
BA_ "GenSigStartValue" SG_ 384 RFC_Hdr00_ProtocolVersion 773;
BA_ "GenSigSendType" SG_ 384 RFC_Hdr00_ProtLocationCount 9;
BA_ "GenSigSendType" SG_ 384 RFC_Hdr00_SensorState 9;
BA_ "GenSigSendType" SG_ 384 RFC_Hdr00_TimeStamp 9;
BA_ "GenSigSendType" SG_ 384 RFC_Hdr00_TimeStampStatus 9;
BA_ "GenSigSendType" SG_ 384 RFC_Hdr00_LocDownSel 9;
BA_ "GenSigSendType" SG_ 384 RFC_Hdr00_BliThetaVld 9;
BA_ "GenSigSendType" SG_ 384 RFC_Hdr00_BliThetaSIMOVld 9;
BA_ "GenSigSendType" SG_ 384 RFC_Hdr00_BliThetaMIMOVld 9;
BA_ "GenSigSendType" SG_ 384 RFC_Hdr00_BliThetaSIMOShareVld 9;
BA_ "GenSigSendType" SG_ 384 RFC_Hdr00_BliThetaMIMOShareVld 9;
BA_ "GenSigSendType" SG_ 384 RFC_Hdr00_BliPhiVld 9;
BA_ "GenSigSendType" SG_ 384 RFC_Hdr00_BliRCSMOVld 9;
BA_ "GenSigSendType" SG_ 384 RFC_Hdr00_BliBinOverThresholdVld 9;
BA_ "GenSigSendType" SG_ 384 RFC_Hdr00_BliNumValidReflectVld 9;
BA_ "GenSigSendType" SG_ 384 RFC_Hdr00_BliTheta 9;
BA_ "GenSigSendType" SG_ 384 RFC_Hdr00_BliThetaSIMO 9;
BA_ "GenSigSendType" SG_ 384 RFC_Hdr00_BliThetaMIMO 9;
BA_ "GenSigSendType" SG_ 384 RFC_Hdr00_BliThetaSIMOShare 9;
BA_ "GenSigSendType" SG_ 384 RFC_Hdr00_BliThetaMIMOShare 9;
BA_ "GenSigSendType" SG_ 384 RFC_Hdr00_BliPhi 9;
BA_ "GenSigSendType" SG_ 384 RFC_Hdr00_BliRCSMO 9;
BA_ "GenSigSendType" SG_ 384 RFC_Hdr00_BliBinsOverThreshold 9;
BA_ "GenSigSendType" SG_ 384 RFC_Hdr00_BliNumValidReflections 9;
BA_ "GenSigSendType" SG_ 384 RFC_Hdr00_BliCrossCorrSO 9;
BA_ "GenSigSendType" SG_ 384 RFC_Hdr00_BliCrossCorrSOVld 9;
BA_ "GenSigSendType" SG_ 385 RFC_Hdr01_PersVerWriteCnt03 9;
BA_ "GenSigSendType" SG_ 385 RFC_Hdr01_PersVerWriteCnt02 9;
BA_ "GenSigSendType" SG_ 385 RFC_Hdr01_PersVerWriteCnt01 9;
BA_ "GenSigSendType" SG_ 385 RFC_Hdr01_CRC 9;
BA_ "GenSigSendType" SG_ 385 RFC_Hdr01_AliveCtr 9;
BA_ "GenSigSendType" SG_ 385 RFC_Hdr01_ProtBlockCtr 9;
BA_ "GenSigSendType" SG_ 385 RFC_Hdr01_PersVerWriteCnt00 9;
BA_ "GenSigSendType" SG_ 385 RFC_Hdr01_PersAngIndAzi 9;
BA_ "GenSigSendType" SG_ 385 RFC_Hdr01_PersAngIndElev 9;
BA_ "GenSigSendType" SG_ 385 RFC_Hdr01_PersAngIndAziMean 9;
BA_ "GenSigSendType" SG_ 385 RFC_Hdr01_PersAngIndElevMean 9;
BA_ "GenSigSendType" SG_ 385 RFC_Hdr01_PersAngIndAziVnce 9;
BA_ "GenSigSendType" SG_ 385 RFC_Hdr01_PersAngIndElevVnce 9;
BA_ "GenSigSendType" SG_ 385 RFC_Hdr01_PersAngIndAziElevCov 9;
BA_ "GenSigSendType" SG_ 385 RFC_Hdr01_PersAngCurrAzi 9;
BA_ "GenSigSendType" SG_ 385 RFC_Hdr01_PersAngCurrElev 9;
BA_ "GenSigSendType" SG_ 385 RFC_Hdr01_PersAngCurrAziMean 9;
BA_ "GenSigSendType" SG_ 385 RFC_Hdr01_PersAngCurrElevMean 9;
BA_ "GenSigSendType" SG_ 385 RFC_Hdr01_PersAngCurrAziVnce 9;
BA_ "GenSigSendType" SG_ 385 RFC_Hdr01_PersAngCurrElevVnce 9;
BA_ "GenSigSendType" SG_ 385 RFC_Hdr01_PersAngCurrAziElevCov 9;
BA_ "GenSigSendType" SG_ 386 RFC_Hdr02_ModPerfDMax 9;
BA_ "GenSigSendType" SG_ 386 RFC_Hdr02_CRC 9;
BA_ "GenSigSendType" SG_ 386 RFC_Hdr02_AliveCtr 9;
BA_ "GenSigSendType" SG_ 386 RFC_Hdr02_ProtBlockCtr 9;
BA_ "GenSigSendType" SG_ 386 RFC_Hdr02_PersFiltDspMalIndAzi 9;
BA_ "GenSigSendType" SG_ 386 RFC_Hdr02_PersFiltWeightIndAzi 9;
BA_ "GenSigSendType" SG_ 386 RFC_Hdr02_PersFiltDspCurrAzi 9;
BA_ "GenSigSendType" SG_ 386 RFC_Hdr02_PersFiltDspMalIndElev 9;
BA_ "GenSigSendType" SG_ 386 RFC_Hdr02_PersFiltWeightIndElev 9;
BA_ "GenSigSendType" SG_ 386 RFC_Hdr02_PersFiltDspCurrElev 9;
BA_ "GenSigSendType" SG_ 386 RFC_Hdr02_PersMalStablePosAzi 9;
BA_ "GenSigSendType" SG_ 386 RFC_Hdr02_PersMalStablePosElev 9;
BA_ "GenSigSendType" SG_ 386 RFC_Hdr02_PersChDetPozAzi 9;
BA_ "GenSigSendType" SG_ 386 RFC_Hdr02_PersChDetNegAzi 9;
BA_ "GenSigSendType" SG_ 386 RFC_Hdr02_PersChDetPozElev 9;
BA_ "GenSigSendType" SG_ 386 RFC_Hdr02_PersChDetNegElev 9;
BA_ "GenSigSendType" SG_ 386 RFC_Hdr02_MntAziCur 9;
BA_ "GenSigSendType" SG_ 386 RFC_Hdr02_MntElevCur 9;
BA_ "GenSigSendType" SG_ 386 RFC_Hdr02_PersOutOfSpecAzi 9;
BA_ "GenSigSendType" SG_ 386 RFC_Hdr02_PersOutOfSpecElev 9;
BA_ "GenSigSendType" SG_ 387 RFC_Hdr03_CRC 9;
BA_ "GenSigSendType" SG_ 387 RFC_Hdr03_AliveCtr 9;
BA_ "GenSigSendType" SG_ 387 RFC_Hdr03_ProtBlockCtr 9;
BA_ "GenSigSendType" SG_ 387 RFC_Hdr03_FoVdMaxTheta00 9;
BA_ "GenSigSendType" SG_ 387 RFC_Hdr03_FoVdMaxTheta01 9;
BA_ "GenSigSendType" SG_ 387 RFC_Hdr03_FoVdMaxTheta02 9;
BA_ "GenSigSendType" SG_ 387 RFC_Hdr03_FoVdMaxTheta03 9;
BA_ "GenSigSendType" SG_ 387 RFC_Hdr03_FoVdMaxTheta04 9;
BA_ "GenSigSendType" SG_ 387 RFC_Hdr03_FoVdMaxTheta05 9;
BA_ "GenSigSendType" SG_ 387 RFC_Hdr03_FoVdMaxTheta06 9;
BA_ "GenSigSendType" SG_ 387 RFC_Hdr03_FoVdMaxTheta07 9;
BA_ "GenSigSendType" SG_ 387 RFC_Hdr03_FoVdMaxTheta08 9;
BA_ "GenSigSendType" SG_ 387 RFC_Hdr03_FoVdMaxTheta09 9;
BA_ "GenSigSendType" SG_ 387 RFC_Hdr03_FoVdMaxTheta10 9;
BA_ "GenSigSendType" SG_ 387 RFC_Hdr03_FoVdMaxTheta11 9;
BA_ "GenSigSendType" SG_ 387 RFC_Hdr03_FoVdMaxTheta12 9;
BA_ "GenSigSendType" SG_ 387 RFC_Hdr03_FoVdMaxTheta13 9;
BA_ "GenSigSendType" SG_ 387 RFC_Hdr03_FoVdMaxTheta14 9;
BA_ "GenSigSendType" SG_ 387 RFC_Hdr03_FoVdMaxTheta15 9;
BA_ "GenSigSendType" SG_ 387 RFC_Hdr03_FoVdMaxTheta16 9;
BA_ "GenSigSendType" SG_ 387 RFC_Hdr03_FoVdMaxTheta17 9;
BA_ "GenSigSendType" SG_ 387 RFC_Hdr03_FoVdMaxTheta18 9;
BA_ "GenSigSendType" SG_ 387 RFC_Hdr03_FoVdMaxTheta19 9;
BA_ "GenSigSendType" SG_ 387 RFC_Hdr03_FoVdMaxTheta20 9;
BA_ "GenSigSendType" SG_ 387 RFC_Hdr03_FoVdMaxTheta21 9;
BA_ "GenSigSendType" SG_ 387 RFC_Hdr03_FoVdMaxTheta22 9;
BA_ "GenSigSendType" SG_ 387 RFC_Hdr03_FoVdMaxTheta23 9;
BA_ "GenSigSendType" SG_ 387 RFC_Hdr03_FoVdMaxTheta24 9;
BA_ "GenSigSendType" SG_ 387 RFC_Hdr03_FoVdMaxPhi00 9;
BA_ "GenSigSendType" SG_ 387 RFC_Hdr03_FoVTheta00 9;
BA_ "GenSigSendType" SG_ 387 RFC_Hdr03_FoVTheta01 9;
BA_ "GenSigSendType" SG_ 387 RFC_Hdr03_FoVTheta02 9;
BA_ "GenSigSendType" SG_ 387 RFC_Hdr03_FoVTheta03 9;
BA_ "GenSigSendType" SG_ 387 RFC_Hdr03_FoVTheta04 9;
BA_ "GenSigSendType" SG_ 387 RFC_Hdr03_FoVTheta05 9;
BA_ "GenSigSendType" SG_ 387 RFC_Hdr03_FoVTheta06 9;
BA_ "GenSigSendType" SG_ 387 RFC_Hdr03_FoVTheta07 9;
BA_ "GenSigSendType" SG_ 387 RFC_Hdr03_FoVTheta08 9;
BA_ "GenSigSendType" SG_ 387 RFC_Hdr03_FoVTheta09 9;
BA_ "GenSigSendType" SG_ 387 RFC_Hdr03_FoVTheta10 9;
BA_ "GenSigSendType" SG_ 387 RFC_Hdr03_FoVTheta11 9;
BA_ "GenSigSendType" SG_ 387 RFC_Hdr03_FoVTheta12 9;
BA_ "GenSigSendType" SG_ 387 RFC_Hdr03_FoVTheta13 9;
BA_ "GenSigSendType" SG_ 387 RFC_Hdr03_FoVTheta14 9;
BA_ "GenSigSendType" SG_ 387 RFC_Hdr03_FoVTheta15 9;
BA_ "GenSigSendType" SG_ 387 RFC_Hdr03_FoVTheta16 9;
BA_ "GenSigSendType" SG_ 387 RFC_Hdr03_FoVTheta17 9;
BA_ "GenSigSendType" SG_ 387 RFC_Hdr03_FoVTheta18 9;
BA_ "GenSigSendType" SG_ 387 RFC_Hdr03_FoVTheta19 9;
BA_ "GenSigSendType" SG_ 387 RFC_Hdr03_FoVTheta20 9;
BA_ "GenSigSendType" SG_ 387 RFC_Hdr03_FoVTheta21 9;
BA_ "GenSigSendType" SG_ 387 RFC_Hdr03_FoVTheta22 9;
BA_ "GenSigSendType" SG_ 387 RFC_Hdr03_FoVTheta23 9;
BA_ "GenSigSendType" SG_ 387 RFC_Hdr03_FoVTheta24 9;
BA_ "GenSigSendType" SG_ 387 RFC_Hdr03_FoVdMaxPhi01 9;
BA_ "GenSigSendType" SG_ 387 RFC_Hdr03_FoVdMaxPhi02 9;
BA_ "GenSigSendType" SG_ 387 RFC_Hdr03_FoVdMaxPhi03 9;
BA_ "GenSigSendType" SG_ 387 RFC_Hdr03_FoVdMaxPhi04 9;
BA_ "GenSigSendType" SG_ 387 RFC_Hdr03_FoVdMaxPhi05 9;
BA_ "GenSigSendType" SG_ 387 RFC_Hdr03_FoVdMaxPhi06 9;
BA_ "GenSigSendType" SG_ 388 RFC_Hdr04_CRC 9;
BA_ "GenSigSendType" SG_ 388 RFC_Hdr04_AliveCtr 9;
BA_ "GenSigSendType" SG_ 388 RFC_Hdr04_ProtBlockCtr 9;
BA_ "GenSigSendType" SG_ 388 RFC_Hdr04_FoVdMaxPhi07 9;
BA_ "GenSigSendType" SG_ 388 RFC_Hdr04_FoVdMaxPhi08 9;
BA_ "GenSigSendType" SG_ 388 RFC_Hdr04_FoVdMaxPhi09 9;
BA_ "GenSigSendType" SG_ 388 RFC_Hdr04_FoVdMaxPhi10 9;
BA_ "GenSigSendType" SG_ 388 RFC_Hdr04_FoVPhi00 9;
BA_ "GenSigSendType" SG_ 388 RFC_Hdr04_FoVPhi01 9;
BA_ "GenSigSendType" SG_ 388 RFC_Hdr04_FoVPhi02 9;
BA_ "GenSigSendType" SG_ 388 RFC_Hdr04_FoVPhi03 9;
BA_ "GenSigSendType" SG_ 388 RFC_Hdr04_FoVPhi04 9;
BA_ "GenSigSendType" SG_ 388 RFC_Hdr04_FoVPhi05 9;
BA_ "GenSigSendType" SG_ 388 RFC_Hdr04_FoVPhi06 9;
BA_ "GenSigSendType" SG_ 388 RFC_Hdr04_FoVPhi07 9;
BA_ "GenSigSendType" SG_ 388 RFC_Hdr04_FoVPhi08 9;
BA_ "GenSigSendType" SG_ 388 RFC_Hdr04_FoVPhi09 9;
BA_ "GenSigSendType" SG_ 388 RFC_Hdr04_FoVPhi10 9;
BA_ "GenSigSendType" SG_ 388 RFC_Hdr04_MntPosX 9;
BA_ "GenSigSendType" SG_ 388 RFC_Hdr04_MntPosY 9;
BA_ "GenSigSendType" SG_ 388 RFC_Hdr04_MntPosZ 9;
BA_ "GenSigSendType" SG_ 388 RFC_Hdr04_MntAziNom 9;
BA_ "GenSigSendType" SG_ 388 RFC_Hdr04_MntElevNom 9;
BA_ "GenSigSendType" SG_ 388 RFC_Hdr04_InitCov 9;
BA_ "GenSigSendType" SG_ 388 RFC_Hdr04_TspMeasID 9;
BA_ "GenSigSendType" SG_ 388 RFC_Hdr04_TspSensID 9;
BA_ "GenSigSendType" SG_ 388 RFC_Hdr04_TspLastMeas 9;
BA_ "GenSigSendType" SG_ 388 RFC_Hdr04_TspLastRec 9;
BA_ "GenSigSendType" SG_ 388 RFC_Hdr04_TspPredMeas 9;
BA_ "GenSigSendType" SG_ 388 RFC_Hdr04_TspPredRec 9;
BA_ "GenSigSendType" SG_ 400 RFC_Loc000_CRC 9;
BA_ "GenSigSendType" SG_ 400 RFC_Loc000_AliveCtr 9;
BA_ "GenSigSendType" SG_ 400 RFC_Loc000_ProtBlockCtr 9;
BA_ "GenSigSendType" SG_ 400 RFC_Loc000_Dr 9;
BA_ "GenSigSendType" SG_ 400 RFC_Loc000_Vr 9;
BA_ "GenSigStartValue" SG_ 400 RFC_Loc000_Vr 32768;
BA_ "GenSigSendType" SG_ 400 RFC_Loc000_Theta 9;
BA_ "GenSigStartValue" SG_ 400 RFC_Loc000_Theta 32768;
BA_ "GenSigSendType" SG_ 400 RFC_Loc000_Phi 9;
BA_ "GenSigStartValue" SG_ 400 RFC_Loc000_Phi 32768;
BA_ "GenSigSendType" SG_ 400 RFC_Loc000_DrVnce 9;
BA_ "GenSigSendType" SG_ 400 RFC_Loc000_VrVnce 9;
BA_ "GenSigSendType" SG_ 400 RFC_Loc000_ThetaVnce 9;
BA_ "GenSigSendType" SG_ 400 RFC_Loc000_PhiVnce 9;
BA_ "GenSigSendType" SG_ 400 RFC_Loc000_DrVrCoVnce 9;
BA_ "GenSigStartValue" SG_ 400 RFC_Loc000_DrVrCoVnce 32768;
BA_ "GenSigSendType" SG_ 400 RFC_Loc000_RCS 9;
BA_ "GenSigStartValue" SG_ 400 RFC_Loc000_RCS 32768;
BA_ "GenSigSendType" SG_ 400 RFC_Loc000_RSSI 9;
BA_ "GenSigSendType" SG_ 400 RFC_Loc000_DrVrQuality 9;
BA_ "GenSigSendType" SG_ 400 RFC_Loc000_ThetaQuality 9;
BA_ "GenSigSendType" SG_ 400 RFC_Loc000_PhiQuality 9;
BA_ "GenSigSendType" SG_ 400 RFC_Loc001_Dr 9;
BA_ "GenSigSendType" SG_ 400 RFC_Loc001_Vr 9;
BA_ "GenSigStartValue" SG_ 400 RFC_Loc001_Vr 32768;
BA_ "GenSigSendType" SG_ 400 RFC_Loc001_Theta 9;
BA_ "GenSigStartValue" SG_ 400 RFC_Loc001_Theta 32768;
BA_ "GenSigSendType" SG_ 400 RFC_Loc001_Phi 9;
BA_ "GenSigStartValue" SG_ 400 RFC_Loc001_Phi 32768;
BA_ "GenSigSendType" SG_ 400 RFC_Loc001_DrVnce 9;
BA_ "GenSigSendType" SG_ 400 RFC_Loc001_VrVnce 9;
BA_ "GenSigSendType" SG_ 400 RFC_Loc001_ThetaVnce 9;
BA_ "GenSigSendType" SG_ 400 RFC_Loc001_PhiVnce 9;
BA_ "GenSigSendType" SG_ 400 RFC_Loc001_DrVrCoVnce 9;
BA_ "GenSigStartValue" SG_ 400 RFC_Loc001_DrVrCoVnce 32768;
BA_ "GenSigSendType" SG_ 400 RFC_Loc001_RCS 9;
BA_ "GenSigStartValue" SG_ 400 RFC_Loc001_RCS 32768;
BA_ "GenSigSendType" SG_ 400 RFC_Loc001_RSSI 9;
BA_ "GenSigSendType" SG_ 400 RFC_Loc001_DrVrQuality 9;
BA_ "GenSigSendType" SG_ 400 RFC_Loc001_ThetaQuality 9;
BA_ "GenSigSendType" SG_ 400 RFC_Loc001_PhiQuality 9;
BA_ "GenSigSendType" SG_ 401 RFC_Loc002_CRC 9;
BA_ "GenSigSendType" SG_ 401 RFC_Loc002_AliveCtr 9;
BA_ "GenSigSendType" SG_ 401 RFC_Loc002_ProtBlockCtr 9;
BA_ "GenSigSendType" SG_ 401 RFC_Loc002_Dr 9;
BA_ "GenSigSendType" SG_ 401 RFC_Loc002_Vr 9;
BA_ "GenSigStartValue" SG_ 401 RFC_Loc002_Vr 32768;
BA_ "GenSigSendType" SG_ 401 RFC_Loc002_Theta 9;
BA_ "GenSigStartValue" SG_ 401 RFC_Loc002_Theta 32768;
BA_ "GenSigSendType" SG_ 401 RFC_Loc002_Phi 9;
BA_ "GenSigStartValue" SG_ 401 RFC_Loc002_Phi 32768;
BA_ "GenSigSendType" SG_ 401 RFC_Loc002_DrVnce 9;
BA_ "GenSigSendType" SG_ 401 RFC_Loc002_VrVnce 9;
BA_ "GenSigSendType" SG_ 401 RFC_Loc002_ThetaVnce 9;
BA_ "GenSigSendType" SG_ 401 RFC_Loc002_PhiVnce 9;
BA_ "GenSigSendType" SG_ 401 RFC_Loc002_DrVrCoVnce 9;
BA_ "GenSigStartValue" SG_ 401 RFC_Loc002_DrVrCoVnce 32768;
BA_ "GenSigSendType" SG_ 401 RFC_Loc002_RCS 9;
BA_ "GenSigStartValue" SG_ 401 RFC_Loc002_RCS 32768;
BA_ "GenSigSendType" SG_ 401 RFC_Loc002_RSSI 9;
BA_ "GenSigSendType" SG_ 401 RFC_Loc002_DrVrQuality 9;
BA_ "GenSigSendType" SG_ 401 RFC_Loc002_ThetaQuality 9;
BA_ "GenSigSendType" SG_ 401 RFC_Loc002_PhiQuality 9;
BA_ "GenSigSendType" SG_ 401 RFC_Loc003_Dr 9;
BA_ "GenSigSendType" SG_ 401 RFC_Loc003_Vr 9;
BA_ "GenSigStartValue" SG_ 401 RFC_Loc003_Vr 32768;
BA_ "GenSigSendType" SG_ 401 RFC_Loc003_Theta 9;
BA_ "GenSigStartValue" SG_ 401 RFC_Loc003_Theta 32768;
BA_ "GenSigSendType" SG_ 401 RFC_Loc003_Phi 9;
BA_ "GenSigStartValue" SG_ 401 RFC_Loc003_Phi 32768;
BA_ "GenSigSendType" SG_ 401 RFC_Loc003_DrVnce 9;
BA_ "GenSigSendType" SG_ 401 RFC_Loc003_VrVnce 9;
BA_ "GenSigSendType" SG_ 401 RFC_Loc003_ThetaVnce 9;
BA_ "GenSigSendType" SG_ 401 RFC_Loc003_PhiVnce 9;
BA_ "GenSigSendType" SG_ 401 RFC_Loc003_DrVrCoVnce 9;
BA_ "GenSigStartValue" SG_ 401 RFC_Loc003_DrVrCoVnce 32768;
BA_ "GenSigSendType" SG_ 401 RFC_Loc003_RCS 9;
BA_ "GenSigStartValue" SG_ 401 RFC_Loc003_RCS 32768;
BA_ "GenSigSendType" SG_ 401 RFC_Loc003_RSSI 9;
BA_ "GenSigSendType" SG_ 401 RFC_Loc003_DrVrQuality 9;
BA_ "GenSigSendType" SG_ 401 RFC_Loc003_ThetaQuality 9;
BA_ "GenSigSendType" SG_ 401 RFC_Loc003_PhiQuality 9;
BA_ "GenSigSendType" SG_ 402 RFC_Loc004_CRC 9;
BA_ "GenSigSendType" SG_ 402 RFC_Loc004_AliveCtr 9;
BA_ "GenSigSendType" SG_ 402 RFC_Loc004_ProtBlockCtr 9;
BA_ "GenSigSendType" SG_ 402 RFC_Loc004_Dr 9;
BA_ "GenSigSendType" SG_ 402 RFC_Loc004_Vr 9;
BA_ "GenSigStartValue" SG_ 402 RFC_Loc004_Vr 32768;
BA_ "GenSigSendType" SG_ 402 RFC_Loc004_Theta 9;
BA_ "GenSigStartValue" SG_ 402 RFC_Loc004_Theta 32768;
BA_ "GenSigSendType" SG_ 402 RFC_Loc004_Phi 9;
BA_ "GenSigStartValue" SG_ 402 RFC_Loc004_Phi 32768;
BA_ "GenSigSendType" SG_ 402 RFC_Loc004_DrVnce 9;
BA_ "GenSigSendType" SG_ 402 RFC_Loc004_VrVnce 9;
BA_ "GenSigSendType" SG_ 402 RFC_Loc004_ThetaVnce 9;
BA_ "GenSigSendType" SG_ 402 RFC_Loc004_PhiVnce 9;
BA_ "GenSigSendType" SG_ 402 RFC_Loc004_DrVrCoVnce 9;
BA_ "GenSigStartValue" SG_ 402 RFC_Loc004_DrVrCoVnce 32768;
BA_ "GenSigSendType" SG_ 402 RFC_Loc004_RCS 9;
BA_ "GenSigStartValue" SG_ 402 RFC_Loc004_RCS 32768;
BA_ "GenSigSendType" SG_ 402 RFC_Loc004_RSSI 9;
BA_ "GenSigSendType" SG_ 402 RFC_Loc004_DrVrQuality 9;
BA_ "GenSigSendType" SG_ 402 RFC_Loc004_ThetaQuality 9;
BA_ "GenSigSendType" SG_ 402 RFC_Loc004_PhiQuality 9;
BA_ "GenSigSendType" SG_ 402 RFC_Loc005_Dr 9;
BA_ "GenSigSendType" SG_ 402 RFC_Loc005_Vr 9;
BA_ "GenSigStartValue" SG_ 402 RFC_Loc005_Vr 32768;
BA_ "GenSigSendType" SG_ 402 RFC_Loc005_Theta 9;
BA_ "GenSigStartValue" SG_ 402 RFC_Loc005_Theta 32768;
BA_ "GenSigSendType" SG_ 402 RFC_Loc005_Phi 9;
BA_ "GenSigStartValue" SG_ 402 RFC_Loc005_Phi 32768;
BA_ "GenSigSendType" SG_ 402 RFC_Loc005_DrVnce 9;
BA_ "GenSigSendType" SG_ 402 RFC_Loc005_VrVnce 9;
BA_ "GenSigSendType" SG_ 402 RFC_Loc005_ThetaVnce 9;
BA_ "GenSigSendType" SG_ 402 RFC_Loc005_PhiVnce 9;
BA_ "GenSigSendType" SG_ 402 RFC_Loc005_DrVrCoVnce 9;
BA_ "GenSigStartValue" SG_ 402 RFC_Loc005_DrVrCoVnce 32768;
BA_ "GenSigSendType" SG_ 402 RFC_Loc005_RCS 9;
BA_ "GenSigStartValue" SG_ 402 RFC_Loc005_RCS 32768;
BA_ "GenSigSendType" SG_ 402 RFC_Loc005_RSSI 9;
BA_ "GenSigSendType" SG_ 402 RFC_Loc005_DrVrQuality 9;
BA_ "GenSigSendType" SG_ 402 RFC_Loc005_ThetaQuality 9;
BA_ "GenSigSendType" SG_ 402 RFC_Loc005_PhiQuality 9;
BA_ "GenSigSendType" SG_ 403 RFC_Loc006_CRC 9;
BA_ "GenSigSendType" SG_ 403 RFC_Loc006_AliveCtr 9;
BA_ "GenSigSendType" SG_ 403 RFC_Loc006_ProtBlockCtr 9;
BA_ "GenSigSendType" SG_ 403 RFC_Loc006_Dr 9;
BA_ "GenSigSendType" SG_ 403 RFC_Loc006_Vr 9;
BA_ "GenSigStartValue" SG_ 403 RFC_Loc006_Vr 32768;
BA_ "GenSigSendType" SG_ 403 RFC_Loc006_Theta 9;
BA_ "GenSigStartValue" SG_ 403 RFC_Loc006_Theta 32768;
BA_ "GenSigSendType" SG_ 403 RFC_Loc006_Phi 9;
BA_ "GenSigStartValue" SG_ 403 RFC_Loc006_Phi 32768;
BA_ "GenSigSendType" SG_ 403 RFC_Loc006_DrVnce 9;
BA_ "GenSigSendType" SG_ 403 RFC_Loc006_VrVnce 9;
BA_ "GenSigSendType" SG_ 403 RFC_Loc006_ThetaVnce 9;
BA_ "GenSigSendType" SG_ 403 RFC_Loc006_PhiVnce 9;
BA_ "GenSigSendType" SG_ 403 RFC_Loc006_DrVrCoVnce 9;
BA_ "GenSigStartValue" SG_ 403 RFC_Loc006_DrVrCoVnce 32768;
BA_ "GenSigSendType" SG_ 403 RFC_Loc006_RCS 9;
BA_ "GenSigStartValue" SG_ 403 RFC_Loc006_RCS 32768;
BA_ "GenSigSendType" SG_ 403 RFC_Loc006_RSSI 9;
BA_ "GenSigSendType" SG_ 403 RFC_Loc006_DrVrQuality 9;
BA_ "GenSigSendType" SG_ 403 RFC_Loc006_ThetaQuality 9;
BA_ "GenSigSendType" SG_ 403 RFC_Loc006_PhiQuality 9;
BA_ "GenSigSendType" SG_ 403 RFC_Loc007_Dr 9;
BA_ "GenSigSendType" SG_ 403 RFC_Loc007_Vr 9;
BA_ "GenSigStartValue" SG_ 403 RFC_Loc007_Vr 32768;
BA_ "GenSigSendType" SG_ 403 RFC_Loc007_Theta 9;
BA_ "GenSigStartValue" SG_ 403 RFC_Loc007_Theta 32768;
BA_ "GenSigSendType" SG_ 403 RFC_Loc007_Phi 9;
BA_ "GenSigStartValue" SG_ 403 RFC_Loc007_Phi 32768;
BA_ "GenSigSendType" SG_ 403 RFC_Loc007_DrVnce 9;
BA_ "GenSigSendType" SG_ 403 RFC_Loc007_VrVnce 9;
BA_ "GenSigSendType" SG_ 403 RFC_Loc007_ThetaVnce 9;
BA_ "GenSigSendType" SG_ 403 RFC_Loc007_PhiVnce 9;
BA_ "GenSigSendType" SG_ 403 RFC_Loc007_DrVrCoVnce 9;
BA_ "GenSigStartValue" SG_ 403 RFC_Loc007_DrVrCoVnce 32768;
BA_ "GenSigSendType" SG_ 403 RFC_Loc007_RCS 9;
BA_ "GenSigStartValue" SG_ 403 RFC_Loc007_RCS 32768;
BA_ "GenSigSendType" SG_ 403 RFC_Loc007_RSSI 9;
BA_ "GenSigSendType" SG_ 403 RFC_Loc007_DrVrQuality 9;
BA_ "GenSigSendType" SG_ 403 RFC_Loc007_ThetaQuality 9;
BA_ "GenSigSendType" SG_ 403 RFC_Loc007_PhiQuality 9;
BA_ "GenSigSendType" SG_ 404 RFC_Loc008_CRC 9;
BA_ "GenSigSendType" SG_ 404 RFC_Loc008_AliveCtr 9;
BA_ "GenSigSendType" SG_ 404 RFC_Loc008_ProtBlockCtr 9;
BA_ "GenSigSendType" SG_ 404 RFC_Loc008_Dr 9;
BA_ "GenSigSendType" SG_ 404 RFC_Loc008_Vr 9;
BA_ "GenSigStartValue" SG_ 404 RFC_Loc008_Vr 32768;
BA_ "GenSigSendType" SG_ 404 RFC_Loc008_Theta 9;
BA_ "GenSigStartValue" SG_ 404 RFC_Loc008_Theta 32768;
BA_ "GenSigSendType" SG_ 404 RFC_Loc008_Phi 9;
BA_ "GenSigStartValue" SG_ 404 RFC_Loc008_Phi 32768;
BA_ "GenSigSendType" SG_ 404 RFC_Loc008_DrVnce 9;
BA_ "GenSigSendType" SG_ 404 RFC_Loc008_VrVnce 9;
BA_ "GenSigSendType" SG_ 404 RFC_Loc008_ThetaVnce 9;
BA_ "GenSigSendType" SG_ 404 RFC_Loc008_PhiVnce 9;
BA_ "GenSigSendType" SG_ 404 RFC_Loc008_DrVrCoVnce 9;
BA_ "GenSigStartValue" SG_ 404 RFC_Loc008_DrVrCoVnce 32768;
BA_ "GenSigSendType" SG_ 404 RFC_Loc008_RCS 9;
BA_ "GenSigStartValue" SG_ 404 RFC_Loc008_RCS 32768;
BA_ "GenSigSendType" SG_ 404 RFC_Loc008_RSSI 9;
BA_ "GenSigSendType" SG_ 404 RFC_Loc008_DrVrQuality 9;
BA_ "GenSigSendType" SG_ 404 RFC_Loc008_ThetaQuality 9;
BA_ "GenSigSendType" SG_ 404 RFC_Loc008_PhiQuality 9;
BA_ "GenSigSendType" SG_ 404 RFC_Loc009_Dr 9;
BA_ "GenSigSendType" SG_ 404 RFC_Loc009_Vr 9;
BA_ "GenSigStartValue" SG_ 404 RFC_Loc009_Vr 32768;
BA_ "GenSigSendType" SG_ 404 RFC_Loc009_Theta 9;
BA_ "GenSigStartValue" SG_ 404 RFC_Loc009_Theta 32768;
BA_ "GenSigSendType" SG_ 404 RFC_Loc009_Phi 9;
BA_ "GenSigStartValue" SG_ 404 RFC_Loc009_Phi 32768;
BA_ "GenSigSendType" SG_ 404 RFC_Loc009_DrVnce 9;
BA_ "GenSigSendType" SG_ 404 RFC_Loc009_VrVnce 9;
BA_ "GenSigSendType" SG_ 404 RFC_Loc009_ThetaVnce 9;
BA_ "GenSigSendType" SG_ 404 RFC_Loc009_PhiVnce 9;
BA_ "GenSigSendType" SG_ 404 RFC_Loc009_DrVrCoVnce 9;
BA_ "GenSigStartValue" SG_ 404 RFC_Loc009_DrVrCoVnce 32768;
BA_ "GenSigSendType" SG_ 404 RFC_Loc009_RCS 9;
BA_ "GenSigStartValue" SG_ 404 RFC_Loc009_RCS 32768;
BA_ "GenSigSendType" SG_ 404 RFC_Loc009_RSSI 9;
BA_ "GenSigSendType" SG_ 404 RFC_Loc009_DrVrQuality 9;
BA_ "GenSigSendType" SG_ 404 RFC_Loc009_ThetaQuality 9;
BA_ "GenSigSendType" SG_ 404 RFC_Loc009_PhiQuality 9;
BA_ "GenSigSendType" SG_ 405 RFC_Loc010_CRC 9;
BA_ "GenSigSendType" SG_ 405 RFC_Loc010_AliveCtr 9;
BA_ "GenSigSendType" SG_ 405 RFC_Loc010_ProtBlockCtr 9;
BA_ "GenSigSendType" SG_ 405 RFC_Loc010_Dr 9;
BA_ "GenSigSendType" SG_ 405 RFC_Loc010_Vr 9;
BA_ "GenSigStartValue" SG_ 405 RFC_Loc010_Vr 32768;
BA_ "GenSigSendType" SG_ 405 RFC_Loc010_Theta 9;
BA_ "GenSigStartValue" SG_ 405 RFC_Loc010_Theta 32768;
BA_ "GenSigSendType" SG_ 405 RFC_Loc010_Phi 9;
BA_ "GenSigStartValue" SG_ 405 RFC_Loc010_Phi 32768;
BA_ "GenSigSendType" SG_ 405 RFC_Loc010_DrVnce 9;
BA_ "GenSigSendType" SG_ 405 RFC_Loc010_VrVnce 9;
BA_ "GenSigSendType" SG_ 405 RFC_Loc010_ThetaVnce 9;
BA_ "GenSigSendType" SG_ 405 RFC_Loc010_PhiVnce 9;
BA_ "GenSigSendType" SG_ 405 RFC_Loc010_DrVrCoVnce 9;
BA_ "GenSigStartValue" SG_ 405 RFC_Loc010_DrVrCoVnce 32768;
BA_ "GenSigSendType" SG_ 405 RFC_Loc010_RCS 9;
BA_ "GenSigStartValue" SG_ 405 RFC_Loc010_RCS 32768;
BA_ "GenSigSendType" SG_ 405 RFC_Loc010_RSSI 9;
BA_ "GenSigSendType" SG_ 405 RFC_Loc010_DrVrQuality 9;
BA_ "GenSigSendType" SG_ 405 RFC_Loc010_ThetaQuality 9;
BA_ "GenSigSendType" SG_ 405 RFC_Loc010_PhiQuality 9;
BA_ "GenSigSendType" SG_ 405 RFC_Loc011_Dr 9;
BA_ "GenSigSendType" SG_ 405 RFC_Loc011_Vr 9;
BA_ "GenSigStartValue" SG_ 405 RFC_Loc011_Vr 32768;
BA_ "GenSigSendType" SG_ 405 RFC_Loc011_Theta 9;
BA_ "GenSigStartValue" SG_ 405 RFC_Loc011_Theta 32768;
BA_ "GenSigSendType" SG_ 405 RFC_Loc011_Phi 9;
BA_ "GenSigStartValue" SG_ 405 RFC_Loc011_Phi 32768;
BA_ "GenSigSendType" SG_ 405 RFC_Loc011_DrVnce 9;
BA_ "GenSigSendType" SG_ 405 RFC_Loc011_VrVnce 9;
BA_ "GenSigSendType" SG_ 405 RFC_Loc011_ThetaVnce 9;
BA_ "GenSigSendType" SG_ 405 RFC_Loc011_PhiVnce 9;
BA_ "GenSigSendType" SG_ 405 RFC_Loc011_DrVrCoVnce 9;
BA_ "GenSigStartValue" SG_ 405 RFC_Loc011_DrVrCoVnce 32768;
BA_ "GenSigSendType" SG_ 405 RFC_Loc011_RCS 9;
BA_ "GenSigStartValue" SG_ 405 RFC_Loc011_RCS 32768;
BA_ "GenSigSendType" SG_ 405 RFC_Loc011_RSSI 9;
BA_ "GenSigSendType" SG_ 405 RFC_Loc011_DrVrQuality 9;
BA_ "GenSigSendType" SG_ 405 RFC_Loc011_ThetaQuality 9;
BA_ "GenSigSendType" SG_ 405 RFC_Loc011_PhiQuality 9;
BA_ "GenSigSendType" SG_ 406 RFC_Loc012_CRC 9;
BA_ "GenSigSendType" SG_ 406 RFC_Loc012_AliveCtr 9;
BA_ "GenSigSendType" SG_ 406 RFC_Loc012_ProtBlockCtr 9;
BA_ "GenSigSendType" SG_ 406 RFC_Loc012_Dr 9;
BA_ "GenSigSendType" SG_ 406 RFC_Loc012_Vr 9;
BA_ "GenSigStartValue" SG_ 406 RFC_Loc012_Vr 32768;
BA_ "GenSigSendType" SG_ 406 RFC_Loc012_Theta 9;
BA_ "GenSigStartValue" SG_ 406 RFC_Loc012_Theta 32768;
BA_ "GenSigSendType" SG_ 406 RFC_Loc012_Phi 9;
BA_ "GenSigStartValue" SG_ 406 RFC_Loc012_Phi 32768;
BA_ "GenSigSendType" SG_ 406 RFC_Loc012_DrVnce 9;
BA_ "GenSigSendType" SG_ 406 RFC_Loc012_VrVnce 9;
BA_ "GenSigSendType" SG_ 406 RFC_Loc012_ThetaVnce 9;
BA_ "GenSigSendType" SG_ 406 RFC_Loc012_PhiVnce 9;
BA_ "GenSigSendType" SG_ 406 RFC_Loc012_DrVrCoVnce 9;
BA_ "GenSigStartValue" SG_ 406 RFC_Loc012_DrVrCoVnce 32768;
BA_ "GenSigSendType" SG_ 406 RFC_Loc012_RCS 9;
BA_ "GenSigStartValue" SG_ 406 RFC_Loc012_RCS 32768;
BA_ "GenSigSendType" SG_ 406 RFC_Loc012_RSSI 9;
BA_ "GenSigSendType" SG_ 406 RFC_Loc012_DrVrQuality 9;
BA_ "GenSigSendType" SG_ 406 RFC_Loc012_ThetaQuality 9;
BA_ "GenSigSendType" SG_ 406 RFC_Loc012_PhiQuality 9;
BA_ "GenSigSendType" SG_ 406 RFC_Loc013_Dr 9;
BA_ "GenSigSendType" SG_ 406 RFC_Loc013_Vr 9;
BA_ "GenSigStartValue" SG_ 406 RFC_Loc013_Vr 32768;
BA_ "GenSigSendType" SG_ 406 RFC_Loc013_Theta 9;
BA_ "GenSigStartValue" SG_ 406 RFC_Loc013_Theta 32768;
BA_ "GenSigSendType" SG_ 406 RFC_Loc013_Phi 9;
BA_ "GenSigStartValue" SG_ 406 RFC_Loc013_Phi 32768;
BA_ "GenSigSendType" SG_ 406 RFC_Loc013_DrVnce 9;
BA_ "GenSigSendType" SG_ 406 RFC_Loc013_VrVnce 9;
BA_ "GenSigSendType" SG_ 406 RFC_Loc013_ThetaVnce 9;
BA_ "GenSigSendType" SG_ 406 RFC_Loc013_PhiVnce 9;
BA_ "GenSigSendType" SG_ 406 RFC_Loc013_DrVrCoVnce 9;
BA_ "GenSigStartValue" SG_ 406 RFC_Loc013_DrVrCoVnce 32768;
BA_ "GenSigSendType" SG_ 406 RFC_Loc013_RCS 9;
BA_ "GenSigStartValue" SG_ 406 RFC_Loc013_RCS 32768;
BA_ "GenSigSendType" SG_ 406 RFC_Loc013_RSSI 9;
BA_ "GenSigSendType" SG_ 406 RFC_Loc013_DrVrQuality 9;
BA_ "GenSigSendType" SG_ 406 RFC_Loc013_ThetaQuality 9;
BA_ "GenSigSendType" SG_ 406 RFC_Loc013_PhiQuality 9;
BA_ "GenSigSendType" SG_ 407 RFC_Loc014_CRC 9;
BA_ "GenSigSendType" SG_ 407 RFC_Loc014_AliveCtr 9;
BA_ "GenSigSendType" SG_ 407 RFC_Loc014_ProtBlockCtr 9;
BA_ "GenSigSendType" SG_ 407 RFC_Loc014_Dr 9;
BA_ "GenSigSendType" SG_ 407 RFC_Loc014_Vr 9;
BA_ "GenSigStartValue" SG_ 407 RFC_Loc014_Vr 32768;
BA_ "GenSigSendType" SG_ 407 RFC_Loc014_Theta 9;
BA_ "GenSigStartValue" SG_ 407 RFC_Loc014_Theta 32768;
BA_ "GenSigSendType" SG_ 407 RFC_Loc014_Phi 9;
BA_ "GenSigStartValue" SG_ 407 RFC_Loc014_Phi 32768;
BA_ "GenSigSendType" SG_ 407 RFC_Loc014_DrVnce 9;
BA_ "GenSigSendType" SG_ 407 RFC_Loc014_VrVnce 9;
BA_ "GenSigSendType" SG_ 407 RFC_Loc014_ThetaVnce 9;
BA_ "GenSigSendType" SG_ 407 RFC_Loc014_PhiVnce 9;
BA_ "GenSigSendType" SG_ 407 RFC_Loc014_DrVrCoVnce 9;
BA_ "GenSigStartValue" SG_ 407 RFC_Loc014_DrVrCoVnce 32768;
BA_ "GenSigSendType" SG_ 407 RFC_Loc014_RCS 9;
BA_ "GenSigStartValue" SG_ 407 RFC_Loc014_RCS 32768;
BA_ "GenSigSendType" SG_ 407 RFC_Loc014_RSSI 9;
BA_ "GenSigSendType" SG_ 407 RFC_Loc014_DrVrQuality 9;
BA_ "GenSigSendType" SG_ 407 RFC_Loc014_ThetaQuality 9;
BA_ "GenSigSendType" SG_ 407 RFC_Loc014_PhiQuality 9;
BA_ "GenSigSendType" SG_ 407 RFC_Loc015_Dr 9;
BA_ "GenSigSendType" SG_ 407 RFC_Loc015_Vr 9;
BA_ "GenSigStartValue" SG_ 407 RFC_Loc015_Vr 32768;
BA_ "GenSigSendType" SG_ 407 RFC_Loc015_Theta 9;
BA_ "GenSigStartValue" SG_ 407 RFC_Loc015_Theta 32768;
BA_ "GenSigSendType" SG_ 407 RFC_Loc015_Phi 9;
BA_ "GenSigStartValue" SG_ 407 RFC_Loc015_Phi 32768;
BA_ "GenSigSendType" SG_ 407 RFC_Loc015_DrVnce 9;
BA_ "GenSigSendType" SG_ 407 RFC_Loc015_VrVnce 9;
BA_ "GenSigSendType" SG_ 407 RFC_Loc015_ThetaVnce 9;
BA_ "GenSigSendType" SG_ 407 RFC_Loc015_PhiVnce 9;
BA_ "GenSigSendType" SG_ 407 RFC_Loc015_DrVrCoVnce 9;
BA_ "GenSigStartValue" SG_ 407 RFC_Loc015_DrVrCoVnce 32768;
BA_ "GenSigSendType" SG_ 407 RFC_Loc015_RCS 9;
BA_ "GenSigStartValue" SG_ 407 RFC_Loc015_RCS 32768;
BA_ "GenSigSendType" SG_ 407 RFC_Loc015_RSSI 9;
BA_ "GenSigSendType" SG_ 407 RFC_Loc015_DrVrQuality 9;
BA_ "GenSigSendType" SG_ 407 RFC_Loc015_ThetaQuality 9;
BA_ "GenSigSendType" SG_ 407 RFC_Loc015_PhiQuality 9;
BA_ "GenSigSendType" SG_ 408 RFC_Loc016_CRC 9;
BA_ "GenSigSendType" SG_ 408 RFC_Loc016_AliveCtr 9;
BA_ "GenSigSendType" SG_ 408 RFC_Loc016_ProtBlockCtr 9;
BA_ "GenSigSendType" SG_ 408 RFC_Loc016_Dr 9;
BA_ "GenSigSendType" SG_ 408 RFC_Loc016_Vr 9;
BA_ "GenSigStartValue" SG_ 408 RFC_Loc016_Vr 32768;
BA_ "GenSigSendType" SG_ 408 RFC_Loc016_Theta 9;
BA_ "GenSigStartValue" SG_ 408 RFC_Loc016_Theta 32768;
BA_ "GenSigSendType" SG_ 408 RFC_Loc016_Phi 9;
BA_ "GenSigStartValue" SG_ 408 RFC_Loc016_Phi 32768;
BA_ "GenSigSendType" SG_ 408 RFC_Loc016_DrVnce 9;
BA_ "GenSigSendType" SG_ 408 RFC_Loc016_VrVnce 9;
BA_ "GenSigSendType" SG_ 408 RFC_Loc016_ThetaVnce 9;
BA_ "GenSigSendType" SG_ 408 RFC_Loc016_PhiVnce 9;
BA_ "GenSigSendType" SG_ 408 RFC_Loc016_DrVrCoVnce 9;
BA_ "GenSigStartValue" SG_ 408 RFC_Loc016_DrVrCoVnce 32768;
BA_ "GenSigSendType" SG_ 408 RFC_Loc016_RCS 9;
BA_ "GenSigStartValue" SG_ 408 RFC_Loc016_RCS 32768;
BA_ "GenSigSendType" SG_ 408 RFC_Loc016_RSSI 9;
BA_ "GenSigSendType" SG_ 408 RFC_Loc016_DrVrQuality 9;
BA_ "GenSigSendType" SG_ 408 RFC_Loc016_ThetaQuality 9;
BA_ "GenSigSendType" SG_ 408 RFC_Loc016_PhiQuality 9;
BA_ "GenSigSendType" SG_ 408 RFC_Loc017_Dr 9;
BA_ "GenSigSendType" SG_ 408 RFC_Loc017_Vr 9;
BA_ "GenSigStartValue" SG_ 408 RFC_Loc017_Vr 32768;
BA_ "GenSigSendType" SG_ 408 RFC_Loc017_Theta 9;
BA_ "GenSigStartValue" SG_ 408 RFC_Loc017_Theta 32768;
BA_ "GenSigSendType" SG_ 408 RFC_Loc017_Phi 9;
BA_ "GenSigStartValue" SG_ 408 RFC_Loc017_Phi 32768;
BA_ "GenSigSendType" SG_ 408 RFC_Loc017_DrVnce 9;
BA_ "GenSigSendType" SG_ 408 RFC_Loc017_VrVnce 9;
BA_ "GenSigSendType" SG_ 408 RFC_Loc017_ThetaVnce 9;
BA_ "GenSigSendType" SG_ 408 RFC_Loc017_PhiVnce 9;
BA_ "GenSigSendType" SG_ 408 RFC_Loc017_DrVrCoVnce 9;
BA_ "GenSigStartValue" SG_ 408 RFC_Loc017_DrVrCoVnce 32768;
BA_ "GenSigSendType" SG_ 408 RFC_Loc017_RCS 9;
BA_ "GenSigStartValue" SG_ 408 RFC_Loc017_RCS 32768;
BA_ "GenSigSendType" SG_ 408 RFC_Loc017_RSSI 9;
BA_ "GenSigSendType" SG_ 408 RFC_Loc017_DrVrQuality 9;
BA_ "GenSigSendType" SG_ 408 RFC_Loc017_ThetaQuality 9;
BA_ "GenSigSendType" SG_ 408 RFC_Loc017_PhiQuality 9;
VAL_ 250 VFC_TS12_ID 0 "INVALID" ;
VAL_ 250 VFC_TS12_Class 0 "UNKNOWN" 1 "SL5" 2 "SL10" 3 "SL15" 4 "SL20" 5 "SL25" 6 "SL30" 7 "SL35" 8 "SL40" 9 "SL45" 10 "SL50" 11 "SL55" 12 "SL60" 13 "SL65" 14 "SL70" 15 "SL75" 16 "SL80" 17 "SL85" 18 "SL90" 19 "SL95" 20 "SL100" 21 "SL105" 22 "SL110" 23 "SL115" 24 "SL120" 25 "SL125" 26 "SL130" 27 "SL135" 28 "SL140" 29 "SL145" 30 "SL150" 31 "SL155" 32 "SL160" 33 "ESL" 34 "EA" 35 "OP" 36 "EOP" 37 "OL" 38 "EOL" 39 "GIVEWAY" 40 "PRIOCROSS" 41 "PRIOCROSSYIELDTORIGHT" 42 "PRIOSTREET" 43 "EPRIOSTREET" 44 "STOP" 45 "AXLEWEIGHT" 46 "CARDIST" 47 "HEIGHT" 48 "LENGTH" 49 "LORRYDIST" 50 "NOALL" 51 "NOBIKE" 52 "NOBUS" 53 "NOCAR" 54 "NOCARBIKE" 55 "NOCARRIAGE" 56 "NOENTRY" 57 "NOHAZMAT" 58 "NOHAZWATER" 59 "NOLORRY" 60 "NOLORRYTRAILER" 61 "NOLTURN" 62 "NOPED" 63 "NORIDER" 64 "NORTURN" 65 "NOTRACTOR" 66 "NOTWOWAY" 67 "NOUTURN" 68 "UMWELT" 69 "EUMWELT" 70 "WEIGHT" 71 "WIDTH" 72 "WARNBIKE" 73 "WARNBUS" 74 "WARNCATTLE" 75 "WARNCONST" 76 "WARNCONSTL" 77 "WARNCONSTR" 78 "WARNCURVEL" 79 "WARNCURVER" 80 "WARNDANGER" 81 "WARNDCURVEL" 82 "WARNDCURVER" 83 "WARNDRAWBRIDGE" 84 "WARNFROG" 85 "WARNGRAVEL" 86 "WARNHUMP" 87 "WARNJAM" 88 "WARNKIDS" 89 "WARNLIGHTS" 90 "WARNLOWTREE" 91 "WARNPCROSS" 92 "WARNPED" 93 "WARNPIER" 94 "WARNPLANE" 95 "WARNRIDER" 96 "WARNROCK" 97 "WARNROUND" 98 "WARNRWORKS" 99 "WARNSKID" 100 "WARNSLOPED" 101 "WARNSLOPEU" 102 "WARNSNOW" 103 "WARNTRAIN" 104 "WARNTWOWAY" 105 "WARNWILDANIMAL" 106 "WARNWIND" 107 "ASL" 108 "EASL" 109 "CALM" 110 "ECALM" 111 "DEADEND" 112 "DOUANE" 113 "FWAY" 114 "EFWAY" 115 "HWAY" 116 "EHWAY" 117 "MSL" 118 "EMSL" 119 "NOPARK" 120 "NOSTOP" 121 "ONEWAYS" 122 "ONEWAYU" 123 "SLOWDOWN" 124 "SCHOOL" 125 "ESCHOOL" 126 "TWN" 127 "ETWN" 128 "WBBENTLEFT" 129 "WBBENTLEFTRIGHT" 130 "WBBENTRIGHT" 131 "WBDIAGL" 132 "WBDIAGLR" 133 "WBDIAGR" 134 "WBHAZWATER" 135 "WBLEFT" 136 "WBRIGHT" 137 "WBROUND" 138 "WBUP" 139 "WBUPLEFT" 140 "WBUPRIGHT" 141 "ZEBRA" 142 "HAZMAT" 143 "EMERGENCYBAY" 144 "ENDOFLANEL" 145 "ENDOFLANER" 146 "ENOPARK" 147 "EONEWAY" 148 "EPARK" 149 "ETOLL" 150 "NOPARKL" 151 "NOPARKLR" 152 "NOPARKR" 153 "NOSTOPL" 154 "NOSTOPLR" 155 "NOSTOPR" 156 "NOTURNONRED" 157 "ONEWAYL" 158 "ONEWAYR" 159 "PARK" 160 "PRIOCROSSL" 161 "PRIOCROSSR" 162 "TOLL" 163 "TUNNEL" 164 "TWOWAY" 165 "WARNCROSS" 166 "WARNCROSSL" 167 "WARNCROSSLR" 168 "WARNCROSSR" 169 "WARNCROSSRL" 170 "WARNCROSST" 171 "WARNGIVEWAYAHEAD" 172 "WARNSLAHEAD" 173 "WARNSTOPAHEAD" 174 "WBBUS" 175 "WRONGWAY" 176 "HAZWATER" 177 "GIVEWAYROUND" 178 "WARNWINDINGL" 179 "WARNWINDINGR" 180 "WARNHAIRPINL" 181 "WARNHAIRPINR" 182 "WARNPEDBIKE" 183 "WARNCROSSY" 184 "WARNBRANCHL" 185 "WARNBRANCHR" 186 "WARNAXLEWEIGHT" 187 "WARNWEIGHT" 188 "WARNHEIGHT" 189 "WARNLENGTH" 190 "WARNWIDTH" 191 "WARNBLACKSPOT" 192 "WARNMERGEL" 193 "WARNMERGER" 194 "WARNTUNNEL" 195 "WARNTRACTOR" 196 "WARNRWORKSVEHICLE" 197 "WARNNARROWBRIDGE" 198 "WARNFLAGGER" 199 "LANES" 200 "LANESHIFTL" 201 "LANESHIFTR" 202 "NEWLANEL" 203 "NEWLANER" 204 "RIGHTTURNONRED" 205 "BORDERLIMIT" 206 "EMBEDDEDRAIN" ;
VAL_ 250 VFC_TS12_EmbedFlag 0 "Unknown" 1 "Not Embedded" 2 "Border Limit" 3 "Multi Lane" 4 "Rain" 5 "Vehicle Type" 6 "Plate" 7 "Error Value" ;
VAL_ 250 VFC_TS12_Quality 0 "Poor Quality" 1 "Good Quality" ;
VAL_ 250 VFC_TS12_VMS 0 "Fixed" 1 "Variable" ;
VAL_ 250 VFC_TS12_Stable 0 "Object Is Not Stable" 1 "Object Is Stable" ;
VAL_ 250 VFC_TS12_VehicleSticker 0 "not_sticker_on_vehicle" 1 "Sign is a sticker on a vehicle" ;
VAL_ 250 VFC_TS12_InternalTrack 0 "Sign is not an internal track" 1 "Sign is an internal track" ;
VAL_ 250 VFC_TS12_AddTS1Class 0 "UNKNOWN" 1 "DETECTED" 2 "ACCIDENT" 3 "ADVICE" 4 "BEGINS" 5 "BUS" 6 "CAMPER" 7 "CAR" 8 "CARAVAN" 9 "CRASHRISK" 10 "DIRT" 11 "DISTANCE" 12 "DISTANCEBARS" 13 "END" 14 "EXITL" 15 "EXITR" 16 "FOG" 17 "GRAVEL" 18 "HAZMAT" 19 "HUMP" 20 "JAM" 21 "LORRY" 22 "EXCEPTLORRY" 23 "LOWTREE" 24 "MCYCLE" 25 "MINIMUM" 26 "NIGHT" 27 "NOSTOPSHOULDER" 28 "OILTRAIL" 29 "PRIOTURN" 30 "RADAR" 31 "RAIN" 32 "RAINSNOW" 33 "REMINDER" 34 "ROADDAMAGE" 35 "RUTS" 36 "RWORKSACCESS" 37 "RWORKSENTRY" 38 "RWORKSEXIT" 39 "SCHOOL" 40 "SECTION" 41 "SMOKE" 42 "SNOW" 43 "SOFTSHOULDERCAR" 44 "SHOFTSHOULDERLORRY" 45 "TEXT" 46 "TIME" 47 "TOWING" 48 "TRACTOR" 49 "TRACTOR_OVER" 50 "TRAILER" 51 "WEIGHT" 52 "WET" 53 "WITHIN" 54 "ZONE" 55 "EXIT" 56 "ACCESS" 57 "ALLWAY" 58 "EXCEPTBUS" 59 "EXCEPTDELIVERY" 60 "EXCEPTLOCAL" 61 "FROG" 62 "PRIOTURNL" 63 "PRIOTURNR" 64 "START" 65 "STOPIN" 66 "HAZWATER" 67 "DAY" 68 "SL" ;
VAL_ 250 VFC_TS12_AddTS1Quality 0 "Poor Quality" 1 "Good Quality" ;
VAL_ 250 VFC_TS12_AddTS1VMS 0 "Fixed" 1 "Variable" ;
VAL_ 250 VFC_TS12_AddTS2Class 0 "UNKNOWN" 1 "DETECTED" 2 "ACCIDENT" 3 "ADVICE" 4 "BEGINS" 5 "BUS" 6 "CAMPER" 7 "CAR" 8 "CARAVAN" 9 "CRASHRISK" 10 "DIRT" 11 "DISTANCE" 12 "DISTANCEBARS" 13 "END" 14 "EXITL" 15 "EXITR" 16 "FOG" 17 "GRAVEL" 18 "HAZMAT" 19 "HUMP" 20 "JAM" 21 "LORRY" 22 "EXCEPTLORRY" 23 "LOWTREE" 24 "MCYCLE" 25 "MINIMUM" 26 "NIGHT" 27 "NOSTOPSHOULDER" 28 "OILTRAIL" 29 "PRIOTURN" 30 "RADAR" 31 "RAIN" 32 "RAINSNOW" 33 "REMINDER" 34 "ROADDAMAGE" 35 "RUTS" 36 "RWORKSACCESS" 37 "RWORKSENTRY" 38 "RWORKSEXIT" 39 "SCHOOL" 40 "SECTION" 41 "SMOKE" 42 "SNOW" 43 "SOFTSHOULDERCAR" 44 "SHOFTSHOULDERLORRY" 45 "TEXT" 46 "TIME" 47 "TOWING" 48 "TRACTOR" 49 "TRACTOR_OVER" 50 "TRAILER" 51 "WEIGHT" 52 "WET" 53 "WITHIN" 54 "ZONE" 55 "EXIT" 56 "ACCESS" 57 "ALLWAY" 58 "EXCEPTBUS" 59 "EXCEPTDELIVERY" 60 "EXCEPTLOCAL" 61 "FROG" 62 "PRIOTURNL" 63 "PRIOTURNR" 64 "START" 65 "STOPIN" 66 "HAZWATER" 67 "DAY" 68 "SL" ;
VAL_ 250 VFC_TS12_AddTS2Quality 0 "Poor Quality" 1 "Good Quality" ;
VAL_ 250 VFC_TS12_AddTS2VMS 0 "Fixed" 1 "Variable" ;
VAL_ 250 VFC_TS12_AddTS3Class 0 "UNKNOWN" 1 "DETECTED" 2 "ACCIDENT" 3 "ADVICE" 4 "BEGINS" 5 "BUS" 6 "CAMPER" 7 "CAR" 8 "CARAVAN" 9 "CRASHRISK" 10 "DIRT" 11 "DISTANCE" 12 "DISTANCEBARS" 13 "END" 14 "EXITL" 15 "EXITR" 16 "FOG" 17 "GRAVEL" 18 "HAZMAT" 19 "HUMP" 20 "JAM" 21 "LORRY" 22 "EXCEPTLORRY" 23 "LOWTREE" 24 "MCYCLE" 25 "MINIMUM" 26 "NIGHT" 27 "NOSTOPSHOULDER" 28 "OILTRAIL" 29 "PRIOTURN" 30 "RADAR" 31 "RAIN" 32 "RAINSNOW" 33 "REMINDER" 34 "ROADDAMAGE" 35 "RUTS" 36 "RWORKSACCESS" 37 "RWORKSENTRY" 38 "RWORKSEXIT" 39 "SCHOOL" 40 "SECTION" 41 "SMOKE" 42 "SNOW" 43 "SOFTSHOULDERCAR" 44 "SHOFTSHOULDERLORRY" 45 "TEXT" 46 "TIME" 47 "TOWING" 48 "TRACTOR" 49 "TRACTOR_OVER" 50 "TRAILER" 51 "WEIGHT" 52 "WET" 53 "WITHIN" 54 "ZONE" 55 "EXIT" 56 "ACCESS" 57 "ALLWAY" 58 "EXCEPTBUS" 59 "EXCEPTDELIVERY" 60 "EXCEPTLOCAL" 61 "FROG" 62 "PRIOTURNL" 63 "PRIOTURNR" 64 "START" 65 "STOPIN" 66 "HAZWATER" 67 "DAY" 68 "SL" ;
VAL_ 250 VFC_TS12_AddTS3Quality 0 "Poor Quality" 1 "Good Quality" ;
VAL_ 250 VFC_TS12_AddTS3VMS 0 "Fixed" 1 "Variable" ;
VAL_ 250 VFC_TS12_AddTS4Class 0 "UNKNOWN" 1 "DETECTED" 2 "ACCIDENT" 3 "ADVICE" 4 "BEGINS" 5 "BUS" 6 "CAMPER" 7 "CAR" 8 "CARAVAN" 9 "CRASHRISK" 10 "DIRT" 11 "DISTANCE" 12 "DISTANCEBARS" 13 "END" 14 "EXITL" 15 "EXITR" 16 "FOG" 17 "GRAVEL" 18 "HAZMAT" 19 "HUMP" 20 "JAM" 21 "LORRY" 22 "EXCEPTLORRY" 23 "LOWTREE" 24 "MCYCLE" 25 "MINIMUM" 26 "NIGHT" 27 "NOSTOPSHOULDER" 28 "OILTRAIL" 29 "PRIOTURN" 30 "RADAR" 31 "RAIN" 32 "RAINSNOW" 33 "REMINDER" 34 "ROADDAMAGE" 35 "RUTS" 36 "RWORKSACCESS" 37 "RWORKSENTRY" 38 "RWORKSEXIT" 39 "SCHOOL" 40 "SECTION" 41 "SMOKE" 42 "SNOW" 43 "SOFTSHOULDERCAR" 44 "SHOFTSHOULDERLORRY" 45 "TEXT" 46 "TIME" 47 "TOWING" 48 "TRACTOR" 49 "TRACTOR_OVER" 50 "TRAILER" 51 "WEIGHT" 52 "WET" 53 "WITHIN" 54 "ZONE" 55 "EXIT" 56 "ACCESS" 57 "ALLWAY" 58 "EXCEPTBUS" 59 "EXCEPTDELIVERY" 60 "EXCEPTLOCAL" 61 "FROG" 62 "PRIOTURNL" 63 "PRIOTURNR" 64 "START" 65 "STOPIN" 66 "HAZWATER" 67 "DAY" 68 "SL" ;
VAL_ 250 VFC_TS12_AddTS4Quality 0 "Poor Quality" 1 "Good Quality" ;
VAL_ 250 VFC_TS12_AddTS4VMS 0 "Fixed" 1 "Variable" ;
VAL_ 250 VFC_TS12_AddTS5Class 0 "UNKNOWN" 1 "DETECTED" 2 "ACCIDENT" 3 "ADVICE" 4 "BEGINS" 5 "BUS" 6 "CAMPER" 7 "CAR" 8 "CARAVAN" 9 "CRASHRISK" 10 "DIRT" 11 "DISTANCE" 12 "DISTANCEBARS" 13 "END" 14 "EXITL" 15 "EXITR" 16 "FOG" 17 "GRAVEL" 18 "HAZMAT" 19 "HUMP" 20 "JAM" 21 "LORRY" 22 "EXCEPTLORRY" 23 "LOWTREE" 24 "MCYCLE" 25 "MINIMUM" 26 "NIGHT" 27 "NOSTOPSHOULDER" 28 "OILTRAIL" 29 "PRIOTURN" 30 "RADAR" 31 "RAIN" 32 "RAINSNOW" 33 "REMINDER" 34 "ROADDAMAGE" 35 "RUTS" 36 "RWORKSACCESS" 37 "RWORKSENTRY" 38 "RWORKSEXIT" 39 "SCHOOL" 40 "SECTION" 41 "SMOKE" 42 "SNOW" 43 "SOFTSHOULDERCAR" 44 "SHOFTSHOULDERLORRY" 45 "TEXT" 46 "TIME" 47 "TOWING" 48 "TRACTOR" 49 "TRACTOR_OVER" 50 "TRAILER" 51 "WEIGHT" 52 "WET" 53 "WITHIN" 54 "ZONE" 55 "EXIT" 56 "ACCESS" 57 "ALLWAY" 58 "EXCEPTBUS" 59 "EXCEPTDELIVERY" 60 "EXCEPTLOCAL" 61 "FROG" 62 "PRIOTURNL" 63 "PRIOTURNR" 64 "START" 65 "STOPIN" 66 "HAZWATER" 67 "DAY" 68 "SL" ;
VAL_ 250 VFC_TS12_AddTS5Quality 0 "Poor Quality" 1 "Good Quality" ;
VAL_ 250 VFC_TS12_AddTS5VMS 0 "Fixed" 1 "Variable" ;
VAL_ 250 VFC_TS12_AddTS6Class 0 "UNKNOWN" 1 "DETECTED" 2 "ACCIDENT" 3 "ADVICE" 4 "BEGINS" 5 "BUS" 6 "CAMPER" 7 "CAR" 8 "CARAVAN" 9 "CRASHRISK" 10 "DIRT" 11 "DISTANCE" 12 "DISTANCEBARS" 13 "END" 14 "EXITL" 15 "EXITR" 16 "FOG" 17 "GRAVEL" 18 "HAZMAT" 19 "HUMP" 20 "JAM" 21 "LORRY" 22 "EXCEPTLORRY" 23 "LOWTREE" 24 "MCYCLE" 25 "MINIMUM" 26 "NIGHT" 27 "NOSTOPSHOULDER" 28 "OILTRAIL" 29 "PRIOTURN" 30 "RADAR" 31 "RAIN" 32 "RAINSNOW" 33 "REMINDER" 34 "ROADDAMAGE" 35 "RUTS" 36 "RWORKSACCESS" 37 "RWORKSENTRY" 38 "RWORKSEXIT" 39 "SCHOOL" 40 "SECTION" 41 "SMOKE" 42 "SNOW" 43 "SOFTSHOULDERCAR" 44 "SHOFTSHOULDERLORRY" 45 "TEXT" 46 "TIME" 47 "TOWING" 48 "TRACTOR" 49 "TRACTOR_OVER" 50 "TRAILER" 51 "WEIGHT" 52 "WET" 53 "WITHIN" 54 "ZONE" 55 "EXIT" 56 "ACCESS" 57 "ALLWAY" 58 "EXCEPTBUS" 59 "EXCEPTDELIVERY" 60 "EXCEPTLOCAL" 61 "FROG" 62 "PRIOTURNL" 63 "PRIOTURNR" 64 "START" 65 "STOPIN" 66 "HAZWATER" 67 "DAY" 68 "SL" ;
VAL_ 250 VFC_TS12_AddTS6Quality 0 "Poor Quality" 1 "Good Quality" ;
VAL_ 250 VFC_TS12_AddTS6VMS 0 "Fixed" 1 "Variable" ;
VAL_ 251 VFC_TS13_ID 0 "INVALID" ;
VAL_ 251 VFC_TS13_Class 0 "UNKNOWN" 1 "SL5" 2 "SL10" 3 "SL15" 4 "SL20" 5 "SL25" 6 "SL30" 7 "SL35" 8 "SL40" 9 "SL45" 10 "SL50" 11 "SL55" 12 "SL60" 13 "SL65" 14 "SL70" 15 "SL75" 16 "SL80" 17 "SL85" 18 "SL90" 19 "SL95" 20 "SL100" 21 "SL105" 22 "SL110" 23 "SL115" 24 "SL120" 25 "SL125" 26 "SL130" 27 "SL135" 28 "SL140" 29 "SL145" 30 "SL150" 31 "SL155" 32 "SL160" 33 "ESL" 34 "EA" 35 "OP" 36 "EOP" 37 "OL" 38 "EOL" 39 "GIVEWAY" 40 "PRIOCROSS" 41 "PRIOCROSSYIELDTORIGHT" 42 "PRIOSTREET" 43 "EPRIOSTREET" 44 "STOP" 45 "AXLEWEIGHT" 46 "CARDIST" 47 "HEIGHT" 48 "LENGTH" 49 "LORRYDIST" 50 "NOALL" 51 "NOBIKE" 52 "NOBUS" 53 "NOCAR" 54 "NOCARBIKE" 55 "NOCARRIAGE" 56 "NOENTRY" 57 "NOHAZMAT" 58 "NOHAZWATER" 59 "NOLORRY" 60 "NOLORRYTRAILER" 61 "NOLTURN" 62 "NOPED" 63 "NORIDER" 64 "NORTURN" 65 "NOTRACTOR" 66 "NOTWOWAY" 67 "NOUTURN" 68 "UMWELT" 69 "EUMWELT" 70 "WEIGHT" 71 "WIDTH" 72 "WARNBIKE" 73 "WARNBUS" 74 "WARNCATTLE" 75 "WARNCONST" 76 "WARNCONSTL" 77 "WARNCONSTR" 78 "WARNCURVEL" 79 "WARNCURVER" 80 "WARNDANGER" 81 "WARNDCURVEL" 82 "WARNDCURVER" 83 "WARNDRAWBRIDGE" 84 "WARNFROG" 85 "WARNGRAVEL" 86 "WARNHUMP" 87 "WARNJAM" 88 "WARNKIDS" 89 "WARNLIGHTS" 90 "WARNLOWTREE" 91 "WARNPCROSS" 92 "WARNPED" 93 "WARNPIER" 94 "WARNPLANE" 95 "WARNRIDER" 96 "WARNROCK" 97 "WARNROUND" 98 "WARNRWORKS" 99 "WARNSKID" 100 "WARNSLOPED" 101 "WARNSLOPEU" 102 "WARNSNOW" 103 "WARNTRAIN" 104 "WARNTWOWAY" 105 "WARNWILDANIMAL" 106 "WARNWIND" 107 "ASL" 108 "EASL" 109 "CALM" 110 "ECALM" 111 "DEADEND" 112 "DOUANE" 113 "FWAY" 114 "EFWAY" 115 "HWAY" 116 "EHWAY" 117 "MSL" 118 "EMSL" 119 "NOPARK" 120 "NOSTOP" 121 "ONEWAYS" 122 "ONEWAYU" 123 "SLOWDOWN" 124 "SCHOOL" 125 "ESCHOOL" 126 "TWN" 127 "ETWN" 128 "WBBENTLEFT" 129 "WBBENTLEFTRIGHT" 130 "WBBENTRIGHT" 131 "WBDIAGL" 132 "WBDIAGLR" 133 "WBDIAGR" 134 "WBHAZWATER" 135 "WBLEFT" 136 "WBRIGHT" 137 "WBROUND" 138 "WBUP" 139 "WBUPLEFT" 140 "WBUPRIGHT" 141 "ZEBRA" 142 "HAZMAT" 143 "EMERGENCYBAY" 144 "ENDOFLANEL" 145 "ENDOFLANER" 146 "ENOPARK" 147 "EONEWAY" 148 "EPARK" 149 "ETOLL" 150 "NOPARKL" 151 "NOPARKLR" 152 "NOPARKR" 153 "NOSTOPL" 154 "NOSTOPLR" 155 "NOSTOPR" 156 "NOTURNONRED" 157 "ONEWAYL" 158 "ONEWAYR" 159 "PARK" 160 "PRIOCROSSL" 161 "PRIOCROSSR" 162 "TOLL" 163 "TUNNEL" 164 "TWOWAY" 165 "WARNCROSS" 166 "WARNCROSSL" 167 "WARNCROSSLR" 168 "WARNCROSSR" 169 "WARNCROSSRL" 170 "WARNCROSST" 171 "WARNGIVEWAYAHEAD" 172 "WARNSLAHEAD" 173 "WARNSTOPAHEAD" 174 "WBBUS" 175 "WRONGWAY" 176 "HAZWATER" 177 "GIVEWAYROUND" 178 "WARNWINDINGL" 179 "WARNWINDINGR" 180 "WARNHAIRPINL" 181 "WARNHAIRPINR" 182 "WARNPEDBIKE" 183 "WARNCROSSY" 184 "WARNBRANCHL" 185 "WARNBRANCHR" 186 "WARNAXLEWEIGHT" 187 "WARNWEIGHT" 188 "WARNHEIGHT" 189 "WARNLENGTH" 190 "WARNWIDTH" 191 "WARNBLACKSPOT" 192 "WARNMERGEL" 193 "WARNMERGER" 194 "WARNTUNNEL" 195 "WARNTRACTOR" 196 "WARNRWORKSVEHICLE" 197 "WARNNARROWBRIDGE" 198 "WARNFLAGGER" 199 "LANES" 200 "LANESHIFTL" 201 "LANESHIFTR" 202 "NEWLANEL" 203 "NEWLANER" 204 "RIGHTTURNONRED" 205 "BORDERLIMIT" 206 "EMBEDDEDRAIN" ;
VAL_ 251 VFC_TS13_EmbedFlag 0 "Unknown" 1 "Not Embedded" 2 "Border Limit" 3 "Multi Lane" 4 "Rain" 5 "Vehicle Type" 6 "Plate" 7 "Error Value" ;
VAL_ 251 VFC_TS13_Quality 0 "Poor Quality" 1 "Good Quality" ;
VAL_ 251 VFC_TS13_VMS 0 "Fixed" 1 "Variable" ;
VAL_ 251 VFC_TS13_Stable 0 "Object Is Not Stable" 1 "Object Is Stable" ;
VAL_ 251 VFC_TS13_VehicleSticker 0 "not_sticker_on_vehicle" 1 "Sign is a sticker on a vehicle" ;
VAL_ 251 VFC_TS13_InternalTrack 0 "Sign is not an internal track" 1 "Sign is an internal track" ;
VAL_ 251 VFC_TS13_AddTS1Class 0 "UNKNOWN" 1 "DETECTED" 2 "ACCIDENT" 3 "ADVICE" 4 "BEGINS" 5 "BUS" 6 "CAMPER" 7 "CAR" 8 "CARAVAN" 9 "CRASHRISK" 10 "DIRT" 11 "DISTANCE" 12 "DISTANCEBARS" 13 "END" 14 "EXITL" 15 "EXITR" 16 "FOG" 17 "GRAVEL" 18 "HAZMAT" 19 "HUMP" 20 "JAM" 21 "LORRY" 22 "EXCEPTLORRY" 23 "LOWTREE" 24 "MCYCLE" 25 "MINIMUM" 26 "NIGHT" 27 "NOSTOPSHOULDER" 28 "OILTRAIL" 29 "PRIOTURN" 30 "RADAR" 31 "RAIN" 32 "RAINSNOW" 33 "REMINDER" 34 "ROADDAMAGE" 35 "RUTS" 36 "RWORKSACCESS" 37 "RWORKSENTRY" 38 "RWORKSEXIT" 39 "SCHOOL" 40 "SECTION" 41 "SMOKE" 42 "SNOW" 43 "SOFTSHOULDERCAR" 44 "SHOFTSHOULDERLORRY" 45 "TEXT" 46 "TIME" 47 "TOWING" 48 "TRACTOR" 49 "TRACTOR_OVER" 50 "TRAILER" 51 "WEIGHT" 52 "WET" 53 "WITHIN" 54 "ZONE" 55 "EXIT" 56 "ACCESS" 57 "ALLWAY" 58 "EXCEPTBUS" 59 "EXCEPTDELIVERY" 60 "EXCEPTLOCAL" 61 "FROG" 62 "PRIOTURNL" 63 "PRIOTURNR" 64 "START" 65 "STOPIN" 66 "HAZWATER" 67 "DAY" 68 "SL" ;
VAL_ 251 VFC_TS13_AddTS1Quality 0 "Poor Quality" 1 "Good Quality" ;
VAL_ 251 VFC_TS13_AddTS1VMS 0 "Fixed" 1 "Variable" ;
VAL_ 251 VFC_TS13_AddTS2Class 0 "UNKNOWN" 1 "DETECTED" 2 "ACCIDENT" 3 "ADVICE" 4 "BEGINS" 5 "BUS" 6 "CAMPER" 7 "CAR" 8 "CARAVAN" 9 "CRASHRISK" 10 "DIRT" 11 "DISTANCE" 12 "DISTANCEBARS" 13 "END" 14 "EXITL" 15 "EXITR" 16 "FOG" 17 "GRAVEL" 18 "HAZMAT" 19 "HUMP" 20 "JAM" 21 "LORRY" 22 "EXCEPTLORRY" 23 "LOWTREE" 24 "MCYCLE" 25 "MINIMUM" 26 "NIGHT" 27 "NOSTOPSHOULDER" 28 "OILTRAIL" 29 "PRIOTURN" 30 "RADAR" 31 "RAIN" 32 "RAINSNOW" 33 "REMINDER" 34 "ROADDAMAGE" 35 "RUTS" 36 "RWORKSACCESS" 37 "RWORKSENTRY" 38 "RWORKSEXIT" 39 "SCHOOL" 40 "SECTION" 41 "SMOKE" 42 "SNOW" 43 "SOFTSHOULDERCAR" 44 "SHOFTSHOULDERLORRY" 45 "TEXT" 46 "TIME" 47 "TOWING" 48 "TRACTOR" 49 "TRACTOR_OVER" 50 "TRAILER" 51 "WEIGHT" 52 "WET" 53 "WITHIN" 54 "ZONE" 55 "EXIT" 56 "ACCESS" 57 "ALLWAY" 58 "EXCEPTBUS" 59 "EXCEPTDELIVERY" 60 "EXCEPTLOCAL" 61 "FROG" 62 "PRIOTURNL" 63 "PRIOTURNR" 64 "START" 65 "STOPIN" 66 "HAZWATER" 67 "DAY" 68 "SL" ;
VAL_ 251 VFC_TS13_AddTS2Quality 0 "Poor Quality" 1 "Good Quality" ;
VAL_ 251 VFC_TS13_AddTS2VMS 0 "Fixed" 1 "Variable" ;
VAL_ 251 VFC_TS13_AddTS3Class 0 "UNKNOWN" 1 "DETECTED" 2 "ACCIDENT" 3 "ADVICE" 4 "BEGINS" 5 "BUS" 6 "CAMPER" 7 "CAR" 8 "CARAVAN" 9 "CRASHRISK" 10 "DIRT" 11 "DISTANCE" 12 "DISTANCEBARS" 13 "END" 14 "EXITL" 15 "EXITR" 16 "FOG" 17 "GRAVEL" 18 "HAZMAT" 19 "HUMP" 20 "JAM" 21 "LORRY" 22 "EXCEPTLORRY" 23 "LOWTREE" 24 "MCYCLE" 25 "MINIMUM" 26 "NIGHT" 27 "NOSTOPSHOULDER" 28 "OILTRAIL" 29 "PRIOTURN" 30 "RADAR" 31 "RAIN" 32 "RAINSNOW" 33 "REMINDER" 34 "ROADDAMAGE" 35 "RUTS" 36 "RWORKSACCESS" 37 "RWORKSENTRY" 38 "RWORKSEXIT" 39 "SCHOOL" 40 "SECTION" 41 "SMOKE" 42 "SNOW" 43 "SOFTSHOULDERCAR" 44 "SHOFTSHOULDERLORRY" 45 "TEXT" 46 "TIME" 47 "TOWING" 48 "TRACTOR" 49 "TRACTOR_OVER" 50 "TRAILER" 51 "WEIGHT" 52 "WET" 53 "WITHIN" 54 "ZONE" 55 "EXIT" 56 "ACCESS" 57 "ALLWAY" 58 "EXCEPTBUS" 59 "EXCEPTDELIVERY" 60 "EXCEPTLOCAL" 61 "FROG" 62 "PRIOTURNL" 63 "PRIOTURNR" 64 "START" 65 "STOPIN" 66 "HAZWATER" 67 "DAY" 68 "SL" ;
VAL_ 251 VFC_TS13_AddTS3Quality 0 "Poor Quality" 1 "Good Quality" ;
VAL_ 251 VFC_TS13_AddTS3VMS 0 "Fixed" 1 "Variable" ;
VAL_ 251 VFC_TS13_AddTS4Class 0 "UNKNOWN" 1 "DETECTED" 2 "ACCIDENT" 3 "ADVICE" 4 "BEGINS" 5 "BUS" 6 "CAMPER" 7 "CAR" 8 "CARAVAN" 9 "CRASHRISK" 10 "DIRT" 11 "DISTANCE" 12 "DISTANCEBARS" 13 "END" 14 "EXITL" 15 "EXITR" 16 "FOG" 17 "GRAVEL" 18 "HAZMAT" 19 "HUMP" 20 "JAM" 21 "LORRY" 22 "EXCEPTLORRY" 23 "LOWTREE" 24 "MCYCLE" 25 "MINIMUM" 26 "NIGHT" 27 "NOSTOPSHOULDER" 28 "OILTRAIL" 29 "PRIOTURN" 30 "RADAR" 31 "RAIN" 32 "RAINSNOW" 33 "REMINDER" 34 "ROADDAMAGE" 35 "RUTS" 36 "RWORKSACCESS" 37 "RWORKSENTRY" 38 "RWORKSEXIT" 39 "SCHOOL" 40 "SECTION" 41 "SMOKE" 42 "SNOW" 43 "SOFTSHOULDERCAR" 44 "SHOFTSHOULDERLORRY" 45 "TEXT" 46 "TIME" 47 "TOWING" 48 "TRACTOR" 49 "TRACTOR_OVER" 50 "TRAILER" 51 "WEIGHT" 52 "WET" 53 "WITHIN" 54 "ZONE" 55 "EXIT" 56 "ACCESS" 57 "ALLWAY" 58 "EXCEPTBUS" 59 "EXCEPTDELIVERY" 60 "EXCEPTLOCAL" 61 "FROG" 62 "PRIOTURNL" 63 "PRIOTURNR" 64 "START" 65 "STOPIN" 66 "HAZWATER" 67 "DAY" 68 "SL" ;
VAL_ 251 VFC_TS13_AddTS4Quality 0 "Poor Quality" 1 "Good Quality" ;
VAL_ 251 VFC_TS13_AddTS4VMS 0 "Fixed" 1 "Variable" ;
VAL_ 251 VFC_TS13_AddTS5Class 0 "UNKNOWN" 1 "DETECTED" 2 "ACCIDENT" 3 "ADVICE" 4 "BEGINS" 5 "BUS" 6 "CAMPER" 7 "CAR" 8 "CARAVAN" 9 "CRASHRISK" 10 "DIRT" 11 "DISTANCE" 12 "DISTANCEBARS" 13 "END" 14 "EXITL" 15 "EXITR" 16 "FOG" 17 "GRAVEL" 18 "HAZMAT" 19 "HUMP" 20 "JAM" 21 "LORRY" 22 "EXCEPTLORRY" 23 "LOWTREE" 24 "MCYCLE" 25 "MINIMUM" 26 "NIGHT" 27 "NOSTOPSHOULDER" 28 "OILTRAIL" 29 "PRIOTURN" 30 "RADAR" 31 "RAIN" 32 "RAINSNOW" 33 "REMINDER" 34 "ROADDAMAGE" 35 "RUTS" 36 "RWORKSACCESS" 37 "RWORKSENTRY" 38 "RWORKSEXIT" 39 "SCHOOL" 40 "SECTION" 41 "SMOKE" 42 "SNOW" 43 "SOFTSHOULDERCAR" 44 "SHOFTSHOULDERLORRY" 45 "TEXT" 46 "TIME" 47 "TOWING" 48 "TRACTOR" 49 "TRACTOR_OVER" 50 "TRAILER" 51 "WEIGHT" 52 "WET" 53 "WITHIN" 54 "ZONE" 55 "EXIT" 56 "ACCESS" 57 "ALLWAY" 58 "EXCEPTBUS" 59 "EXCEPTDELIVERY" 60 "EXCEPTLOCAL" 61 "FROG" 62 "PRIOTURNL" 63 "PRIOTURNR" 64 "START" 65 "STOPIN" 66 "HAZWATER" 67 "DAY" 68 "SL" ;
VAL_ 251 VFC_TS13_AddTS5Quality 0 "Poor Quality" 1 "Good Quality" ;
VAL_ 251 VFC_TS13_AddTS5VMS 0 "Fixed" 1 "Variable" ;
VAL_ 251 VFC_TS13_AddTS6Class 0 "UNKNOWN" 1 "DETECTED" 2 "ACCIDENT" 3 "ADVICE" 4 "BEGINS" 5 "BUS" 6 "CAMPER" 7 "CAR" 8 "CARAVAN" 9 "CRASHRISK" 10 "DIRT" 11 "DISTANCE" 12 "DISTANCEBARS" 13 "END" 14 "EXITL" 15 "EXITR" 16 "FOG" 17 "GRAVEL" 18 "HAZMAT" 19 "HUMP" 20 "JAM" 21 "LORRY" 22 "EXCEPTLORRY" 23 "LOWTREE" 24 "MCYCLE" 25 "MINIMUM" 26 "NIGHT" 27 "NOSTOPSHOULDER" 28 "OILTRAIL" 29 "PRIOTURN" 30 "RADAR" 31 "RAIN" 32 "RAINSNOW" 33 "REMINDER" 34 "ROADDAMAGE" 35 "RUTS" 36 "RWORKSACCESS" 37 "RWORKSENTRY" 38 "RWORKSEXIT" 39 "SCHOOL" 40 "SECTION" 41 "SMOKE" 42 "SNOW" 43 "SOFTSHOULDERCAR" 44 "SHOFTSHOULDERLORRY" 45 "TEXT" 46 "TIME" 47 "TOWING" 48 "TRACTOR" 49 "TRACTOR_OVER" 50 "TRAILER" 51 "WEIGHT" 52 "WET" 53 "WITHIN" 54 "ZONE" 55 "EXIT" 56 "ACCESS" 57 "ALLWAY" 58 "EXCEPTBUS" 59 "EXCEPTDELIVERY" 60 "EXCEPTLOCAL" 61 "FROG" 62 "PRIOTURNL" 63 "PRIOTURNR" 64 "START" 65 "STOPIN" 66 "HAZWATER" 67 "DAY" 68 "SL" ;
VAL_ 251 VFC_TS13_AddTS6Quality 0 "Poor Quality" 1 "Good Quality" ;
VAL_ 251 VFC_TS13_AddTS6VMS 0 "Fixed" 1 "Variable" ;
VAL_ 252 VFC_TS14_ID 0 "INVALID" ;
VAL_ 252 VFC_TS14_Class 0 "UNKNOWN" 1 "SL5" 2 "SL10" 3 "SL15" 4 "SL20" 5 "SL25" 6 "SL30" 7 "SL35" 8 "SL40" 9 "SL45" 10 "SL50" 11 "SL55" 12 "SL60" 13 "SL65" 14 "SL70" 15 "SL75" 16 "SL80" 17 "SL85" 18 "SL90" 19 "SL95" 20 "SL100" 21 "SL105" 22 "SL110" 23 "SL115" 24 "SL120" 25 "SL125" 26 "SL130" 27 "SL135" 28 "SL140" 29 "SL145" 30 "SL150" 31 "SL155" 32 "SL160" 33 "ESL" 34 "EA" 35 "OP" 36 "EOP" 37 "OL" 38 "EOL" 39 "GIVEWAY" 40 "PRIOCROSS" 41 "PRIOCROSSYIELDTORIGHT" 42 "PRIOSTREET" 43 "EPRIOSTREET" 44 "STOP" 45 "AXLEWEIGHT" 46 "CARDIST" 47 "HEIGHT" 48 "LENGTH" 49 "LORRYDIST" 50 "NOALL" 51 "NOBIKE" 52 "NOBUS" 53 "NOCAR" 54 "NOCARBIKE" 55 "NOCARRIAGE" 56 "NOENTRY" 57 "NOHAZMAT" 58 "NOHAZWATER" 59 "NOLORRY" 60 "NOLORRYTRAILER" 61 "NOLTURN" 62 "NOPED" 63 "NORIDER" 64 "NORTURN" 65 "NOTRACTOR" 66 "NOTWOWAY" 67 "NOUTURN" 68 "UMWELT" 69 "EUMWELT" 70 "WEIGHT" 71 "WIDTH" 72 "WARNBIKE" 73 "WARNBUS" 74 "WARNCATTLE" 75 "WARNCONST" 76 "WARNCONSTL" 77 "WARNCONSTR" 78 "WARNCURVEL" 79 "WARNCURVER" 80 "WARNDANGER" 81 "WARNDCURVEL" 82 "WARNDCURVER" 83 "WARNDRAWBRIDGE" 84 "WARNFROG" 85 "WARNGRAVEL" 86 "WARNHUMP" 87 "WARNJAM" 88 "WARNKIDS" 89 "WARNLIGHTS" 90 "WARNLOWTREE" 91 "WARNPCROSS" 92 "WARNPED" 93 "WARNPIER" 94 "WARNPLANE" 95 "WARNRIDER" 96 "WARNROCK" 97 "WARNROUND" 98 "WARNRWORKS" 99 "WARNSKID" 100 "WARNSLOPED" 101 "WARNSLOPEU" 102 "WARNSNOW" 103 "WARNTRAIN" 104 "WARNTWOWAY" 105 "WARNWILDANIMAL" 106 "WARNWIND" 107 "ASL" 108 "EASL" 109 "CALM" 110 "ECALM" 111 "DEADEND" 112 "DOUANE" 113 "FWAY" 114 "EFWAY" 115 "HWAY" 116 "EHWAY" 117 "MSL" 118 "EMSL" 119 "NOPARK" 120 "NOSTOP" 121 "ONEWAYS" 122 "ONEWAYU" 123 "SLOWDOWN" 124 "SCHOOL" 125 "ESCHOOL" 126 "TWN" 127 "ETWN" 128 "WBBENTLEFT" 129 "WBBENTLEFTRIGHT" 130 "WBBENTRIGHT" 131 "WBDIAGL" 132 "WBDIAGLR" 133 "WBDIAGR" 134 "WBHAZWATER" 135 "WBLEFT" 136 "WBRIGHT" 137 "WBROUND" 138 "WBUP" 139 "WBUPLEFT" 140 "WBUPRIGHT" 141 "ZEBRA" 142 "HAZMAT" 143 "EMERGENCYBAY" 144 "ENDOFLANEL" 145 "ENDOFLANER" 146 "ENOPARK" 147 "EONEWAY" 148 "EPARK" 149 "ETOLL" 150 "NOPARKL" 151 "NOPARKLR" 152 "NOPARKR" 153 "NOSTOPL" 154 "NOSTOPLR" 155 "NOSTOPR" 156 "NOTURNONRED" 157 "ONEWAYL" 158 "ONEWAYR" 159 "PARK" 160 "PRIOCROSSL" 161 "PRIOCROSSR" 162 "TOLL" 163 "TUNNEL" 164 "TWOWAY" 165 "WARNCROSS" 166 "WARNCROSSL" 167 "WARNCROSSLR" 168 "WARNCROSSR" 169 "WARNCROSSRL" 170 "WARNCROSST" 171 "WARNGIVEWAYAHEAD" 172 "WARNSLAHEAD" 173 "WARNSTOPAHEAD" 174 "WBBUS" 175 "WRONGWAY" 176 "HAZWATER" 177 "GIVEWAYROUND" 178 "WARNWINDINGL" 179 "WARNWINDINGR" 180 "WARNHAIRPINL" 181 "WARNHAIRPINR" 182 "WARNPEDBIKE" 183 "WARNCROSSY" 184 "WARNBRANCHL" 185 "WARNBRANCHR" 186 "WARNAXLEWEIGHT" 187 "WARNWEIGHT" 188 "WARNHEIGHT" 189 "WARNLENGTH" 190 "WARNWIDTH" 191 "WARNBLACKSPOT" 192 "WARNMERGEL" 193 "WARNMERGER" 194 "WARNTUNNEL" 195 "WARNTRACTOR" 196 "WARNRWORKSVEHICLE" 197 "WARNNARROWBRIDGE" 198 "WARNFLAGGER" 199 "LANES" 200 "LANESHIFTL" 201 "LANESHIFTR" 202 "NEWLANEL" 203 "NEWLANER" 204 "RIGHTTURNONRED" 205 "BORDERLIMIT" 206 "EMBEDDEDRAIN" ;
VAL_ 252 VFC_TS14_EmbedFlag 0 "Unknown" 1 "Not Embedded" 2 "Border Limit" 3 "Multi Lane" 4 "Rain" 5 "Vehicle Type" 6 "Plate" 7 "Error Value" ;
VAL_ 252 VFC_TS14_Quality 0 "Poor Quality" 1 "Good Quality" ;
VAL_ 252 VFC_TS14_VMS 0 "Fixed" 1 "Variable" ;
VAL_ 252 VFC_TS14_Stable 0 "Object Is Not Stable" 1 "Object Is Stable" ;
VAL_ 252 VFC_TS14_VehicleSticker 0 "not_sticker_on_vehicle" 1 "Sign is a sticker on a vehicle" ;
VAL_ 252 VFC_TS14_InternalTrack 0 "Sign is not an internal track" 1 "Sign is an internal track" ;
VAL_ 252 VFC_TS14_AddTS1Class 0 "UNKNOWN" 1 "DETECTED" 2 "ACCIDENT" 3 "ADVICE" 4 "BEGINS" 5 "BUS" 6 "CAMPER" 7 "CAR" 8 "CARAVAN" 9 "CRASHRISK" 10 "DIRT" 11 "DISTANCE" 12 "DISTANCEBARS" 13 "END" 14 "EXITL" 15 "EXITR" 16 "FOG" 17 "GRAVEL" 18 "HAZMAT" 19 "HUMP" 20 "JAM" 21 "LORRY" 22 "EXCEPTLORRY" 23 "LOWTREE" 24 "MCYCLE" 25 "MINIMUM" 26 "NIGHT" 27 "NOSTOPSHOULDER" 28 "OILTRAIL" 29 "PRIOTURN" 30 "RADAR" 31 "RAIN" 32 "RAINSNOW" 33 "REMINDER" 34 "ROADDAMAGE" 35 "RUTS" 36 "RWORKSACCESS" 37 "RWORKSENTRY" 38 "RWORKSEXIT" 39 "SCHOOL" 40 "SECTION" 41 "SMOKE" 42 "SNOW" 43 "SOFTSHOULDERCAR" 44 "SHOFTSHOULDERLORRY" 45 "TEXT" 46 "TIME" 47 "TOWING" 48 "TRACTOR" 49 "TRACTOR_OVER" 50 "TRAILER" 51 "WEIGHT" 52 "WET" 53 "WITHIN" 54 "ZONE" 55 "EXIT" 56 "ACCESS" 57 "ALLWAY" 58 "EXCEPTBUS" 59 "EXCEPTDELIVERY" 60 "EXCEPTLOCAL" 61 "FROG" 62 "PRIOTURNL" 63 "PRIOTURNR" 64 "START" 65 "STOPIN" 66 "HAZWATER" 67 "DAY" 68 "SL" ;
VAL_ 252 VFC_TS14_AddTS1Quality 0 "Poor Quality" 1 "Good Quality" ;
VAL_ 252 VFC_TS14_AddTS1VMS 0 "Fixed" 1 "Variable" ;
VAL_ 252 VFC_TS14_AddTS2Class 0 "UNKNOWN" 1 "DETECTED" 2 "ACCIDENT" 3 "ADVICE" 4 "BEGINS" 5 "BUS" 6 "CAMPER" 7 "CAR" 8 "CARAVAN" 9 "CRASHRISK" 10 "DIRT" 11 "DISTANCE" 12 "DISTANCEBARS" 13 "END" 14 "EXITL" 15 "EXITR" 16 "FOG" 17 "GRAVEL" 18 "HAZMAT" 19 "HUMP" 20 "JAM" 21 "LORRY" 22 "EXCEPTLORRY" 23 "LOWTREE" 24 "MCYCLE" 25 "MINIMUM" 26 "NIGHT" 27 "NOSTOPSHOULDER" 28 "OILTRAIL" 29 "PRIOTURN" 30 "RADAR" 31 "RAIN" 32 "RAINSNOW" 33 "REMINDER" 34 "ROADDAMAGE" 35 "RUTS" 36 "RWORKSACCESS" 37 "RWORKSENTRY" 38 "RWORKSEXIT" 39 "SCHOOL" 40 "SECTION" 41 "SMOKE" 42 "SNOW" 43 "SOFTSHOULDERCAR" 44 "SHOFTSHOULDERLORRY" 45 "TEXT" 46 "TIME" 47 "TOWING" 48 "TRACTOR" 49 "TRACTOR_OVER" 50 "TRAILER" 51 "WEIGHT" 52 "WET" 53 "WITHIN" 54 "ZONE" 55 "EXIT" 56 "ACCESS" 57 "ALLWAY" 58 "EXCEPTBUS" 59 "EXCEPTDELIVERY" 60 "EXCEPTLOCAL" 61 "FROG" 62 "PRIOTURNL" 63 "PRIOTURNR" 64 "START" 65 "STOPIN" 66 "HAZWATER" 67 "DAY" 68 "SL" ;
VAL_ 252 VFC_TS14_AddTS2Quality 0 "Poor Quality" 1 "Good Quality" ;
VAL_ 252 VFC_TS14_AddTS2VMS 0 "Fixed" 1 "Variable" ;
VAL_ 252 VFC_TS14_AddTS3Class 0 "UNKNOWN" 1 "DETECTED" 2 "ACCIDENT" 3 "ADVICE" 4 "BEGINS" 5 "BUS" 6 "CAMPER" 7 "CAR" 8 "CARAVAN" 9 "CRASHRISK" 10 "DIRT" 11 "DISTANCE" 12 "DISTANCEBARS" 13 "END" 14 "EXITL" 15 "EXITR" 16 "FOG" 17 "GRAVEL" 18 "HAZMAT" 19 "HUMP" 20 "JAM" 21 "LORRY" 22 "EXCEPTLORRY" 23 "LOWTREE" 24 "MCYCLE" 25 "MINIMUM" 26 "NIGHT" 27 "NOSTOPSHOULDER" 28 "OILTRAIL" 29 "PRIOTURN" 30 "RADAR" 31 "RAIN" 32 "RAINSNOW" 33 "REMINDER" 34 "ROADDAMAGE" 35 "RUTS" 36 "RWORKSACCESS" 37 "RWORKSENTRY" 38 "RWORKSEXIT" 39 "SCHOOL" 40 "SECTION" 41 "SMOKE" 42 "SNOW" 43 "SOFTSHOULDERCAR" 44 "SHOFTSHOULDERLORRY" 45 "TEXT" 46 "TIME" 47 "TOWING" 48 "TRACTOR" 49 "TRACTOR_OVER" 50 "TRAILER" 51 "WEIGHT" 52 "WET" 53 "WITHIN" 54 "ZONE" 55 "EXIT" 56 "ACCESS" 57 "ALLWAY" 58 "EXCEPTBUS" 59 "EXCEPTDELIVERY" 60 "EXCEPTLOCAL" 61 "FROG" 62 "PRIOTURNL" 63 "PRIOTURNR" 64 "START" 65 "STOPIN" 66 "HAZWATER" 67 "DAY" 68 "SL" ;
VAL_ 252 VFC_TS14_AddTS3Quality 0 "Poor Quality" 1 "Good Quality" ;
VAL_ 252 VFC_TS14_AddTS3VMS 0 "Fixed" 1 "Variable" ;
VAL_ 252 VFC_TS14_AddTS4Class 0 "UNKNOWN" 1 "DETECTED" 2 "ACCIDENT" 3 "ADVICE" 4 "BEGINS" 5 "BUS" 6 "CAMPER" 7 "CAR" 8 "CARAVAN" 9 "CRASHRISK" 10 "DIRT" 11 "DISTANCE" 12 "DISTANCEBARS" 13 "END" 14 "EXITL" 15 "EXITR" 16 "FOG" 17 "GRAVEL" 18 "HAZMAT" 19 "HUMP" 20 "JAM" 21 "LORRY" 22 "EXCEPTLORRY" 23 "LOWTREE" 24 "MCYCLE" 25 "MINIMUM" 26 "NIGHT" 27 "NOSTOPSHOULDER" 28 "OILTRAIL" 29 "PRIOTURN" 30 "RADAR" 31 "RAIN" 32 "RAINSNOW" 33 "REMINDER" 34 "ROADDAMAGE" 35 "RUTS" 36 "RWORKSACCESS" 37 "RWORKSENTRY" 38 "RWORKSEXIT" 39 "SCHOOL" 40 "SECTION" 41 "SMOKE" 42 "SNOW" 43 "SOFTSHOULDERCAR" 44 "SHOFTSHOULDERLORRY" 45 "TEXT" 46 "TIME" 47 "TOWING" 48 "TRACTOR" 49 "TRACTOR_OVER" 50 "TRAILER" 51 "WEIGHT" 52 "WET" 53 "WITHIN" 54 "ZONE" 55 "EXIT" 56 "ACCESS" 57 "ALLWAY" 58 "EXCEPTBUS" 59 "EXCEPTDELIVERY" 60 "EXCEPTLOCAL" 61 "FROG" 62 "PRIOTURNL" 63 "PRIOTURNR" 64 "START" 65 "STOPIN" 66 "HAZWATER" 67 "DAY" 68 "SL" ;
VAL_ 252 VFC_TS14_AddTS4Quality 0 "Poor Quality" 1 "Good Quality" ;
VAL_ 252 VFC_TS14_AddTS4VMS 0 "Fixed" 1 "Variable" ;
VAL_ 252 VFC_TS14_AddTS5Class 0 "UNKNOWN" 1 "DETECTED" 2 "ACCIDENT" 3 "ADVICE" 4 "BEGINS" 5 "BUS" 6 "CAMPER" 7 "CAR" 8 "CARAVAN" 9 "CRASHRISK" 10 "DIRT" 11 "DISTANCE" 12 "DISTANCEBARS" 13 "END" 14 "EXITL" 15 "EXITR" 16 "FOG" 17 "GRAVEL" 18 "HAZMAT" 19 "HUMP" 20 "JAM" 21 "LORRY" 22 "EXCEPTLORRY" 23 "LOWTREE" 24 "MCYCLE" 25 "MINIMUM" 26 "NIGHT" 27 "NOSTOPSHOULDER" 28 "OILTRAIL" 29 "PRIOTURN" 30 "RADAR" 31 "RAIN" 32 "RAINSNOW" 33 "REMINDER" 34 "ROADDAMAGE" 35 "RUTS" 36 "RWORKSACCESS" 37 "RWORKSENTRY" 38 "RWORKSEXIT" 39 "SCHOOL" 40 "SECTION" 41 "SMOKE" 42 "SNOW" 43 "SOFTSHOULDERCAR" 44 "SHOFTSHOULDERLORRY" 45 "TEXT" 46 "TIME" 47 "TOWING" 48 "TRACTOR" 49 "TRACTOR_OVER" 50 "TRAILER" 51 "WEIGHT" 52 "WET" 53 "WITHIN" 54 "ZONE" 55 "EXIT" 56 "ACCESS" 57 "ALLWAY" 58 "EXCEPTBUS" 59 "EXCEPTDELIVERY" 60 "EXCEPTLOCAL" 61 "FROG" 62 "PRIOTURNL" 63 "PRIOTURNR" 64 "START" 65 "STOPIN" 66 "HAZWATER" 67 "DAY" 68 "SL" ;
VAL_ 252 VFC_TS14_AddTS5Quality 0 "Poor Quality" 1 "Good Quality" ;
VAL_ 252 VFC_TS14_AddTS5VMS 0 "Fixed" 1 "Variable" ;
VAL_ 252 VFC_TS14_AddTS6Class 0 "UNKNOWN" 1 "DETECTED" 2 "ACCIDENT" 3 "ADVICE" 4 "BEGINS" 5 "BUS" 6 "CAMPER" 7 "CAR" 8 "CARAVAN" 9 "CRASHRISK" 10 "DIRT" 11 "DISTANCE" 12 "DISTANCEBARS" 13 "END" 14 "EXITL" 15 "EXITR" 16 "FOG" 17 "GRAVEL" 18 "HAZMAT" 19 "HUMP" 20 "JAM" 21 "LORRY" 22 "EXCEPTLORRY" 23 "LOWTREE" 24 "MCYCLE" 25 "MINIMUM" 26 "NIGHT" 27 "NOSTOPSHOULDER" 28 "OILTRAIL" 29 "PRIOTURN" 30 "RADAR" 31 "RAIN" 32 "RAINSNOW" 33 "REMINDER" 34 "ROADDAMAGE" 35 "RUTS" 36 "RWORKSACCESS" 37 "RWORKSENTRY" 38 "RWORKSEXIT" 39 "SCHOOL" 40 "SECTION" 41 "SMOKE" 42 "SNOW" 43 "SOFTSHOULDERCAR" 44 "SHOFTSHOULDERLORRY" 45 "TEXT" 46 "TIME" 47 "TOWING" 48 "TRACTOR" 49 "TRACTOR_OVER" 50 "TRAILER" 51 "WEIGHT" 52 "WET" 53 "WITHIN" 54 "ZONE" 55 "EXIT" 56 "ACCESS" 57 "ALLWAY" 58 "EXCEPTBUS" 59 "EXCEPTDELIVERY" 60 "EXCEPTLOCAL" 61 "FROG" 62 "PRIOTURNL" 63 "PRIOTURNR" 64 "START" 65 "STOPIN" 66 "HAZWATER" 67 "DAY" 68 "SL" ;
VAL_ 252 VFC_TS14_AddTS6Quality 0 "Poor Quality" 1 "Good Quality" ;
VAL_ 252 VFC_TS14_AddTS6VMS 0 "Fixed" 1 "Variable" ;
VAL_ 253 VFC_TS15_ID 0 "INVALID" ;
VAL_ 253 VFC_TS15_Class 0 "UNKNOWN" 1 "SL5" 2 "SL10" 3 "SL15" 4 "SL20" 5 "SL25" 6 "SL30" 7 "SL35" 8 "SL40" 9 "SL45" 10 "SL50" 11 "SL55" 12 "SL60" 13 "SL65" 14 "SL70" 15 "SL75" 16 "SL80" 17 "SL85" 18 "SL90" 19 "SL95" 20 "SL100" 21 "SL105" 22 "SL110" 23 "SL115" 24 "SL120" 25 "SL125" 26 "SL130" 27 "SL135" 28 "SL140" 29 "SL145" 30 "SL150" 31 "SL155" 32 "SL160" 33 "ESL" 34 "EA" 35 "OP" 36 "EOP" 37 "OL" 38 "EOL" 39 "GIVEWAY" 40 "PRIOCROSS" 41 "PRIOCROSSYIELDTORIGHT" 42 "PRIOSTREET" 43 "EPRIOSTREET" 44 "STOP" 45 "AXLEWEIGHT" 46 "CARDIST" 47 "HEIGHT" 48 "LENGTH" 49 "LORRYDIST" 50 "NOALL" 51 "NOBIKE" 52 "NOBUS" 53 "NOCAR" 54 "NOCARBIKE" 55 "NOCARRIAGE" 56 "NOENTRY" 57 "NOHAZMAT" 58 "NOHAZWATER" 59 "NOLORRY" 60 "NOLORRYTRAILER" 61 "NOLTURN" 62 "NOPED" 63 "NORIDER" 64 "NORTURN" 65 "NOTRACTOR" 66 "NOTWOWAY" 67 "NOUTURN" 68 "UMWELT" 69 "EUMWELT" 70 "WEIGHT" 71 "WIDTH" 72 "WARNBIKE" 73 "WARNBUS" 74 "WARNCATTLE" 75 "WARNCONST" 76 "WARNCONSTL" 77 "WARNCONSTR" 78 "WARNCURVEL" 79 "WARNCURVER" 80 "WARNDANGER" 81 "WARNDCURVEL" 82 "WARNDCURVER" 83 "WARNDRAWBRIDGE" 84 "WARNFROG" 85 "WARNGRAVEL" 86 "WARNHUMP" 87 "WARNJAM" 88 "WARNKIDS" 89 "WARNLIGHTS" 90 "WARNLOWTREE" 91 "WARNPCROSS" 92 "WARNPED" 93 "WARNPIER" 94 "WARNPLANE" 95 "WARNRIDER" 96 "WARNROCK" 97 "WARNROUND" 98 "WARNRWORKS" 99 "WARNSKID" 100 "WARNSLOPED" 101 "WARNSLOPEU" 102 "WARNSNOW" 103 "WARNTRAIN" 104 "WARNTWOWAY" 105 "WARNWILDANIMAL" 106 "WARNWIND" 107 "ASL" 108 "EASL" 109 "CALM" 110 "ECALM" 111 "DEADEND" 112 "DOUANE" 113 "FWAY" 114 "EFWAY" 115 "HWAY" 116 "EHWAY" 117 "MSL" 118 "EMSL" 119 "NOPARK" 120 "NOSTOP" 121 "ONEWAYS" 122 "ONEWAYU" 123 "SLOWDOWN" 124 "SCHOOL" 125 "ESCHOOL" 126 "TWN" 127 "ETWN" 128 "WBBENTLEFT" 129 "WBBENTLEFTRIGHT" 130 "WBBENTRIGHT" 131 "WBDIAGL" 132 "WBDIAGLR" 133 "WBDIAGR" 134 "WBHAZWATER" 135 "WBLEFT" 136 "WBRIGHT" 137 "WBROUND" 138 "WBUP" 139 "WBUPLEFT" 140 "WBUPRIGHT" 141 "ZEBRA" 142 "HAZMAT" 143 "EMERGENCYBAY" 144 "ENDOFLANEL" 145 "ENDOFLANER" 146 "ENOPARK" 147 "EONEWAY" 148 "EPARK" 149 "ETOLL" 150 "NOPARKL" 151 "NOPARKLR" 152 "NOPARKR" 153 "NOSTOPL" 154 "NOSTOPLR" 155 "NOSTOPR" 156 "NOTURNONRED" 157 "ONEWAYL" 158 "ONEWAYR" 159 "PARK" 160 "PRIOCROSSL" 161 "PRIOCROSSR" 162 "TOLL" 163 "TUNNEL" 164 "TWOWAY" 165 "WARNCROSS" 166 "WARNCROSSL" 167 "WARNCROSSLR" 168 "WARNCROSSR" 169 "WARNCROSSRL" 170 "WARNCROSST" 171 "WARNGIVEWAYAHEAD" 172 "WARNSLAHEAD" 173 "WARNSTOPAHEAD" 174 "WBBUS" 175 "WRONGWAY" 176 "HAZWATER" 177 "GIVEWAYROUND" 178 "WARNWINDINGL" 179 "WARNWINDINGR" 180 "WARNHAIRPINL" 181 "WARNHAIRPINR" 182 "WARNPEDBIKE" 183 "WARNCROSSY" 184 "WARNBRANCHL" 185 "WARNBRANCHR" 186 "WARNAXLEWEIGHT" 187 "WARNWEIGHT" 188 "WARNHEIGHT" 189 "WARNLENGTH" 190 "WARNWIDTH" 191 "WARNBLACKSPOT" 192 "WARNMERGEL" 193 "WARNMERGER" 194 "WARNTUNNEL" 195 "WARNTRACTOR" 196 "WARNRWORKSVEHICLE" 197 "WARNNARROWBRIDGE" 198 "WARNFLAGGER" 199 "LANES" 200 "LANESHIFTL" 201 "LANESHIFTR" 202 "NEWLANEL" 203 "NEWLANER" 204 "RIGHTTURNONRED" 205 "BORDERLIMIT" 206 "EMBEDDEDRAIN" ;
VAL_ 253 VFC_TS15_EmbedFlag 0 "Unknown" 1 "Not Embedded" 2 "Border Limit" 3 "Multi Lane" 4 "Rain" 5 "Vehicle Type" 6 "Plate" 7 "Error Value" ;
VAL_ 253 VFC_TS15_Quality 0 "Poor Quality" 1 "Good Quality" ;
VAL_ 253 VFC_TS15_VMS 0 "Fixed" 1 "Variable" ;
VAL_ 253 VFC_TS15_Stable 0 "Object Is Not Stable" 1 "Object Is Stable" ;
VAL_ 253 VFC_TS15_VehicleSticker 0 "not_sticker_on_vehicle" 1 "Sign is a sticker on a vehicle" ;
VAL_ 253 VFC_TS15_InternalTrack 0 "Sign is not an internal track" 1 "Sign is an internal track" ;
VAL_ 253 VFC_TS15_AddTS1Class 0 "UNKNOWN" 1 "DETECTED" 2 "ACCIDENT" 3 "ADVICE" 4 "BEGINS" 5 "BUS" 6 "CAMPER" 7 "CAR" 8 "CARAVAN" 9 "CRASHRISK" 10 "DIRT" 11 "DISTANCE" 12 "DISTANCEBARS" 13 "END" 14 "EXITL" 15 "EXITR" 16 "FOG" 17 "GRAVEL" 18 "HAZMAT" 19 "HUMP" 20 "JAM" 21 "LORRY" 22 "EXCEPTLORRY" 23 "LOWTREE" 24 "MCYCLE" 25 "MINIMUM" 26 "NIGHT" 27 "NOSTOPSHOULDER" 28 "OILTRAIL" 29 "PRIOTURN" 30 "RADAR" 31 "RAIN" 32 "RAINSNOW" 33 "REMINDER" 34 "ROADDAMAGE" 35 "RUTS" 36 "RWORKSACCESS" 37 "RWORKSENTRY" 38 "RWORKSEXIT" 39 "SCHOOL" 40 "SECTION" 41 "SMOKE" 42 "SNOW" 43 "SOFTSHOULDERCAR" 44 "SHOFTSHOULDERLORRY" 45 "TEXT" 46 "TIME" 47 "TOWING" 48 "TRACTOR" 49 "TRACTOR_OVER" 50 "TRAILER" 51 "WEIGHT" 52 "WET" 53 "WITHIN" 54 "ZONE" 55 "EXIT" 56 "ACCESS" 57 "ALLWAY" 58 "EXCEPTBUS" 59 "EXCEPTDELIVERY" 60 "EXCEPTLOCAL" 61 "FROG" 62 "PRIOTURNL" 63 "PRIOTURNR" 64 "START" 65 "STOPIN" 66 "HAZWATER" 67 "DAY" 68 "SL" ;
VAL_ 253 VFC_TS15_AddTS1Quality 0 "Poor Quality" 1 "Good Quality" ;
VAL_ 253 VFC_TS15_AddTS1VMS 0 "Fixed" 1 "Variable" ;
VAL_ 253 VFC_TS15_AddTS2Class 0 "UNKNOWN" 1 "DETECTED" 2 "ACCIDENT" 3 "ADVICE" 4 "BEGINS" 5 "BUS" 6 "CAMPER" 7 "CAR" 8 "CARAVAN" 9 "CRASHRISK" 10 "DIRT" 11 "DISTANCE" 12 "DISTANCEBARS" 13 "END" 14 "EXITL" 15 "EXITR" 16 "FOG" 17 "GRAVEL" 18 "HAZMAT" 19 "HUMP" 20 "JAM" 21 "LORRY" 22 "EXCEPTLORRY" 23 "LOWTREE" 24 "MCYCLE" 25 "MINIMUM" 26 "NIGHT" 27 "NOSTOPSHOULDER" 28 "OILTRAIL" 29 "PRIOTURN" 30 "RADAR" 31 "RAIN" 32 "RAINSNOW" 33 "REMINDER" 34 "ROADDAMAGE" 35 "RUTS" 36 "RWORKSACCESS" 37 "RWORKSENTRY" 38 "RWORKSEXIT" 39 "SCHOOL" 40 "SECTION" 41 "SMOKE" 42 "SNOW" 43 "SOFTSHOULDERCAR" 44 "SHOFTSHOULDERLORRY" 45 "TEXT" 46 "TIME" 47 "TOWING" 48 "TRACTOR" 49 "TRACTOR_OVER" 50 "TRAILER" 51 "WEIGHT" 52 "WET" 53 "WITHIN" 54 "ZONE" 55 "EXIT" 56 "ACCESS" 57 "ALLWAY" 58 "EXCEPTBUS" 59 "EXCEPTDELIVERY" 60 "EXCEPTLOCAL" 61 "FROG" 62 "PRIOTURNL" 63 "PRIOTURNR" 64 "START" 65 "STOPIN" 66 "HAZWATER" 67 "DAY" 68 "SL" ;
VAL_ 253 VFC_TS15_AddTS2Quality 0 "Poor Quality" 1 "Good Quality" ;
VAL_ 253 VFC_TS15_AddTS2VMS 0 "Fixed" 1 "Variable" ;
VAL_ 253 VFC_TS15_AddTS3Class 0 "UNKNOWN" 1 "DETECTED" 2 "ACCIDENT" 3 "ADVICE" 4 "BEGINS" 5 "BUS" 6 "CAMPER" 7 "CAR" 8 "CARAVAN" 9 "CRASHRISK" 10 "DIRT" 11 "DISTANCE" 12 "DISTANCEBARS" 13 "END" 14 "EXITL" 15 "EXITR" 16 "FOG" 17 "GRAVEL" 18 "HAZMAT" 19 "HUMP" 20 "JAM" 21 "LORRY" 22 "EXCEPTLORRY" 23 "LOWTREE" 24 "MCYCLE" 25 "MINIMUM" 26 "NIGHT" 27 "NOSTOPSHOULDER" 28 "OILTRAIL" 29 "PRIOTURN" 30 "RADAR" 31 "RAIN" 32 "RAINSNOW" 33 "REMINDER" 34 "ROADDAMAGE" 35 "RUTS" 36 "RWORKSACCESS" 37 "RWORKSENTRY" 38 "RWORKSEXIT" 39 "SCHOOL" 40 "SECTION" 41 "SMOKE" 42 "SNOW" 43 "SOFTSHOULDERCAR" 44 "SHOFTSHOULDERLORRY" 45 "TEXT" 46 "TIME" 47 "TOWING" 48 "TRACTOR" 49 "TRACTOR_OVER" 50 "TRAILER" 51 "WEIGHT" 52 "WET" 53 "WITHIN" 54 "ZONE" 55 "EXIT" 56 "ACCESS" 57 "ALLWAY" 58 "EXCEPTBUS" 59 "EXCEPTDELIVERY" 60 "EXCEPTLOCAL" 61 "FROG" 62 "PRIOTURNL" 63 "PRIOTURNR" 64 "START" 65 "STOPIN" 66 "HAZWATER" 67 "DAY" 68 "SL" ;
VAL_ 253 VFC_TS15_AddTS3Quality 0 "Poor Quality" 1 "Good Quality" ;
VAL_ 253 VFC_TS15_AddTS3VMS 0 "Fixed" 1 "Variable" ;
VAL_ 253 VFC_TS15_AddTS4Class 0 "UNKNOWN" 1 "DETECTED" 2 "ACCIDENT" 3 "ADVICE" 4 "BEGINS" 5 "BUS" 6 "CAMPER" 7 "CAR" 8 "CARAVAN" 9 "CRASHRISK" 10 "DIRT" 11 "DISTANCE" 12 "DISTANCEBARS" 13 "END" 14 "EXITL" 15 "EXITR" 16 "FOG" 17 "GRAVEL" 18 "HAZMAT" 19 "HUMP" 20 "JAM" 21 "LORRY" 22 "EXCEPTLORRY" 23 "LOWTREE" 24 "MCYCLE" 25 "MINIMUM" 26 "NIGHT" 27 "NOSTOPSHOULDER" 28 "OILTRAIL" 29 "PRIOTURN" 30 "RADAR" 31 "RAIN" 32 "RAINSNOW" 33 "REMINDER" 34 "ROADDAMAGE" 35 "RUTS" 36 "RWORKSACCESS" 37 "RWORKSENTRY" 38 "RWORKSEXIT" 39 "SCHOOL" 40 "SECTION" 41 "SMOKE" 42 "SNOW" 43 "SOFTSHOULDERCAR" 44 "SHOFTSHOULDERLORRY" 45 "TEXT" 46 "TIME" 47 "TOWING" 48 "TRACTOR" 49 "TRACTOR_OVER" 50 "TRAILER" 51 "WEIGHT" 52 "WET" 53 "WITHIN" 54 "ZONE" 55 "EXIT" 56 "ACCESS" 57 "ALLWAY" 58 "EXCEPTBUS" 59 "EXCEPTDELIVERY" 60 "EXCEPTLOCAL" 61 "FROG" 62 "PRIOTURNL" 63 "PRIOTURNR" 64 "START" 65 "STOPIN" 66 "HAZWATER" 67 "DAY" 68 "SL" ;
VAL_ 253 VFC_TS15_AddTS4Quality 0 "Poor Quality" 1 "Good Quality" ;
VAL_ 253 VFC_TS15_AddTS4VMS 0 "Fixed" 1 "Variable" ;
VAL_ 253 VFC_TS15_AddTS5Class 0 "UNKNOWN" 1 "DETECTED" 2 "ACCIDENT" 3 "ADVICE" 4 "BEGINS" 5 "BUS" 6 "CAMPER" 7 "CAR" 8 "CARAVAN" 9 "CRASHRISK" 10 "DIRT" 11 "DISTANCE" 12 "DISTANCEBARS" 13 "END" 14 "EXITL" 15 "EXITR" 16 "FOG" 17 "GRAVEL" 18 "HAZMAT" 19 "HUMP" 20 "JAM" 21 "LORRY" 22 "EXCEPTLORRY" 23 "LOWTREE" 24 "MCYCLE" 25 "MINIMUM" 26 "NIGHT" 27 "NOSTOPSHOULDER" 28 "OILTRAIL" 29 "PRIOTURN" 30 "RADAR" 31 "RAIN" 32 "RAINSNOW" 33 "REMINDER" 34 "ROADDAMAGE" 35 "RUTS" 36 "RWORKSACCESS" 37 "RWORKSENTRY" 38 "RWORKSEXIT" 39 "SCHOOL" 40 "SECTION" 41 "SMOKE" 42 "SNOW" 43 "SOFTSHOULDERCAR" 44 "SHOFTSHOULDERLORRY" 45 "TEXT" 46 "TIME" 47 "TOWING" 48 "TRACTOR" 49 "TRACTOR_OVER" 50 "TRAILER" 51 "WEIGHT" 52 "WET" 53 "WITHIN" 54 "ZONE" 55 "EXIT" 56 "ACCESS" 57 "ALLWAY" 58 "EXCEPTBUS" 59 "EXCEPTDELIVERY" 60 "EXCEPTLOCAL" 61 "FROG" 62 "PRIOTURNL" 63 "PRIOTURNR" 64 "START" 65 "STOPIN" 66 "HAZWATER" 67 "DAY" 68 "SL" ;
VAL_ 253 VFC_TS15_AddTS5Quality 0 "Poor Quality" 1 "Good Quality" ;
VAL_ 253 VFC_TS15_AddTS5VMS 0 "Fixed" 1 "Variable" ;
VAL_ 253 VFC_TS15_AddTS6Class 0 "UNKNOWN" 1 "DETECTED" 2 "ACCIDENT" 3 "ADVICE" 4 "BEGINS" 5 "BUS" 6 "CAMPER" 7 "CAR" 8 "CARAVAN" 9 "CRASHRISK" 10 "DIRT" 11 "DISTANCE" 12 "DISTANCEBARS" 13 "END" 14 "EXITL" 15 "EXITR" 16 "FOG" 17 "GRAVEL" 18 "HAZMAT" 19 "HUMP" 20 "JAM" 21 "LORRY" 22 "EXCEPTLORRY" 23 "LOWTREE" 24 "MCYCLE" 25 "MINIMUM" 26 "NIGHT" 27 "NOSTOPSHOULDER" 28 "OILTRAIL" 29 "PRIOTURN" 30 "RADAR" 31 "RAIN" 32 "RAINSNOW" 33 "REMINDER" 34 "ROADDAMAGE" 35 "RUTS" 36 "RWORKSACCESS" 37 "RWORKSENTRY" 38 "RWORKSEXIT" 39 "SCHOOL" 40 "SECTION" 41 "SMOKE" 42 "SNOW" 43 "SOFTSHOULDERCAR" 44 "SHOFTSHOULDERLORRY" 45 "TEXT" 46 "TIME" 47 "TOWING" 48 "TRACTOR" 49 "TRACTOR_OVER" 50 "TRAILER" 51 "WEIGHT" 52 "WET" 53 "WITHIN" 54 "ZONE" 55 "EXIT" 56 "ACCESS" 57 "ALLWAY" 58 "EXCEPTBUS" 59 "EXCEPTDELIVERY" 60 "EXCEPTLOCAL" 61 "FROG" 62 "PRIOTURNL" 63 "PRIOTURNR" 64 "START" 65 "STOPIN" 66 "HAZWATER" 67 "DAY" 68 "SL" ;
VAL_ 253 VFC_TS15_AddTS6Quality 0 "Poor Quality" 1 "Good Quality" ;
VAL_ 253 VFC_TS15_AddTS6VMS 0 "Fixed" 1 "Variable" ;
VAL_ 75 ADAS_FwdWarnFltTxt 1 "FCW Failure" 0 "Default" ;
VAL_ 75 ADAS_FCWSwtFb 3 "Fault" 2 "Switch On" 1 "Switch Off" 0 "Default" ;
VAL_ 75 ADAS_AEBSwtFb 3 "Fault" 2 "Switch On" 1 "Switch Off" 0 "Default" ;
VAL_ 75 ADAS_ADASSnvtySetFb 3 "Reserved" 2 "High Sensitivity" 1 "Low Sensitivity" 0 "Default" ;
VAL_ 75 ADAS_Warn_FCW 3 "Acutewarning" 2 "Prewarning" 1 "Latent Warning" 0 "No Warning" ;
VAL_ 75 ADAS_WarnTyp_FCWAEB 7 "Reserved" 6 "Bus" 5 "Cyclist" 4 "Truck" 3 "Car" 2 "Pedestrian" 1 "Unknown" 0 "Reserved" ;
VAL_ 75 ADAS_Sts_FCW 7 "Reserved" 6 "Reserved" 5 "Reserved" 4 "Fault" 3 "Active" 2 "Standby" 1 "Reserved" 0 "Off" ;
VAL_ 75 ADAS_Sts_AEB 7 "Reserved" 6 "Reserved" 5 "Reserved" 4 "Fault" 3 "Active" 2 "Standby" 1 "Reserved" 0 "Off" ;
VAL_ 74 ADAS_FrntTar1Typ_ACC 7 "Reserved" 6 "Reserved" 5 "Reserved" 4 "Reserved" 3 "Motor/Bicycle" 2 "Truck" 1 "Car" 0 "No Display" ;
VAL_ 74 ADAS_FrntTar1X_ACC 255 "Invalid" ;
VAL_ 74 ADAS_FrntTar1Y_ACC 255 "Invalid" ;
VAL_ 81 RFC_SensorS_Status 0 "SENSOR FULLY OPERATIONAL" 1 "HW MALFUNCTION" 2 "DSP ISSUES" 3 "COMMUNICATION ERRORS" 4 "MISALIGNMENT (OUT OF SPEC)" 5 "SENSOR BLIDNESS DETECTED" 6 "SENSOR DISTUBED" 7 "OTHER ISSUES" 8 "RESERVED1" 9 "RESERVED2" 10 "RESERVED3" 11 "RESERVED4" 12 "RESERVED5" 13 "RESERVED6" 14 "RESERVED7" 15 "INVALID" ;
VAL_ 931 VFC_MapInfo_CountryCode 156 "CN=156" 0 "Unknown" ;
VAL_ 931 VFC_MapInfo_CurrentLane 7 "N/A" 6 "reserved" 5 "mid-lane within 3 or mare lanes" 4 "right most lane" 3 "left most lane" 2 "Signal lane road" 1 "Emergency lane" 0 "Unknown" ;
VAL_ 931 VFC_MapInfo_BuildUp 3 "reserved" 2 "unknown" 1 "in the segment" 0 "not in the segment" ;
VAL_ 931 VFC_MapInfo_Bridge 3 "reserved" 2 "unknown" 1 "in the segment" 0 "not in the segment" ;
VAL_ 931 VFC_MapInfo_Tunnel 3 "reserved" 2 "unknown" 1 "in the segment" 0 "not in the segment" ;
VAL_ 931 VFC_MapInfo_TollGate 3 "reserved" 2 "unknown" 1 "in the segment" 0 "not in the segment" ;
VAL_ 931 VFC_MapInfo_DiRoad_Offset200 3 "Invalid" 2 "Unknown" 1 "True" 0 "False" ;
VAL_ 931 VFC_MapInfo_LaneNum_Offset200 7 "Unknown" 6 "6 or more lanes" 5 "5 lanes" 4 "4 lanes" 3 "3 lanes" 2 "2 lanes" 1 "1 lane" 0 "Wrong direction" ;
VAL_ 931 VFC_MapInfo_LaneNum_Offset0 7 "Unknown" 6 "6 or more lanes" 5 "5 lanes" 4 "4 lanes" 3 "3 lanes" 2 "2 lanes" 1 "1 lane" 0 "Wrong direction" ;
VAL_ 931 VFC_MapInfo_DiRoad_Offset0 3 "Invalid" 2 "Unknown" 1 "True" 0 "False" ;
VAL_ 931 VFC_MapInfo_RoadClass_Offset200 7 "SNA" 6 "Class 6" 5 "Class 5" 4 "Class 4" 3 "Class 3" 2 "Class 2" 1 "Class 1" 0 "Unknown" ;
VAL_ 931 VFC_MapInfo_RoadClass_Offset0 7 "SNA" 6 "Class 6" 5 "Class 5" 4 "Class 4" 3 "Class 3" 2 "Class 2" 1 "Class 1" 0 "Unknown" ;
VAL_ 930 VFC_ADAS_ModSts_SLA 0 "Unknown" 1 "Off" 2 "Fusion mode" 3 "Vision mode" 4 "Navigation only mode" 5 "Defect" 6 "Reserved" 7 "Reserved" ;
VAL_ 930 VFC_ADAS_SpdLim_SLA 0 "No Display" 1 "SPL Cancelled" 2 "SPL 5" 3 "SPL 10" 4 "SPL 15" 5 "SPL 20" 6 "SPL 25" 7 "SPL 30" 8 "SPL 35" 9 "SPL 40" 10 "SPL 45" 11 "SPL 50" 12 "SPL 55" 13 "SPL 60" 14 "SPL 65" 15 "SPL 70" 16 "SPL 75" 17 "SPL 80" 18 "SPL 85" 19 "SPL 90" 20 "SPL 95" 21 "SPL 100" 22 "SPL 105" 23 "SPL 110" 24 "SPL 115" 25 "SPL 120" 26 "SPL 125" 27 "SPL 130" 28 "Reserved" 29 "0x1C(28)-FF(255): Reserved." 255 "0x1C(28)-FF(255): Reserved." ;
VAL_ 930 VFC_ADAS_SpdLimUnit_SLA 0 "Unknown" 1 "KPH" 2 "MPH" 3 "Reserved" ;
VAL_ 384 RFC_Hdr00_SensorState 0 "SENSOR FULLY OPERATIONAL" 1 "HW MALFUNCTION" 2 "DSP ISSUES" 3 "COMMUNICATION ERRORS" 4 "MISALIGNMENT (OUT OF SPEC)" 5 "SENSOR BLIDNESS DETECTED" 6 "SENSOR DISTUBED" 7 "OTHER ISSUES" 8 "RESERVED1" 9 "RESERVED2" 10 "RESERVED3" 11 "RESERVED4" 12 "RESERVED5" 13 "RESERVED6" 14 "RESERVED7" 15 "INVALID" ;
VAL_ 384 RFC_Hdr00_LocDownSel 0 "no downselection" 1 "downselected" ;
SIG_VALTYPE_ 384 RFC_Hdr00_BliTheta : 1;
SIG_VALTYPE_ 384 RFC_Hdr00_BliThetaSIMO : 1;
SIG_VALTYPE_ 384 RFC_Hdr00_BliThetaMIMO : 1;
SIG_VALTYPE_ 384 RFC_Hdr00_BliThetaSIMOShare : 1;
SIG_VALTYPE_ 384 RFC_Hdr00_BliThetaMIMOShare : 1;
SIG_VALTYPE_ 384 RFC_Hdr00_BliPhi : 1;
SIG_VALTYPE_ 384 RFC_Hdr00_BliRCSMO : 1;
SIG_VALTYPE_ 384 RFC_Hdr00_BliBinsOverThreshold : 1;
SIG_VALTYPE_ 384 RFC_Hdr00_BliNumValidReflections : 1;
SIG_VALTYPE_ 384 RFC_Hdr00_BliCrossCorrSO : 1;
SIG_VALTYPE_ 385 RFC_Hdr01_PersAngIndAzi : 1;
SIG_VALTYPE_ 385 RFC_Hdr01_PersAngIndElev : 1;
SIG_VALTYPE_ 385 RFC_Hdr01_PersAngIndAziMean : 1;
SIG_VALTYPE_ 385 RFC_Hdr01_PersAngIndElevMean : 1;
SIG_VALTYPE_ 385 RFC_Hdr01_PersAngIndAziVnce : 1;
SIG_VALTYPE_ 385 RFC_Hdr01_PersAngIndElevVnce : 1;
SIG_VALTYPE_ 385 RFC_Hdr01_PersAngIndAziElevCov : 1;
SIG_VALTYPE_ 385 RFC_Hdr01_PersAngCurrAzi : 1;
SIG_VALTYPE_ 385 RFC_Hdr01_PersAngCurrElev : 1;
SIG_VALTYPE_ 385 RFC_Hdr01_PersAngCurrAziMean : 1;
SIG_VALTYPE_ 385 RFC_Hdr01_PersAngCurrElevMean : 1;
SIG_VALTYPE_ 385 RFC_Hdr01_PersAngCurrAziVnce : 1;
SIG_VALTYPE_ 385 RFC_Hdr01_PersAngCurrElevVnce : 1;
SIG_VALTYPE_ 385 RFC_Hdr01_PersAngCurrAziElevCov : 1;
SIG_VALTYPE_ 386 RFC_Hdr02_PersFiltDspMalIndAzi : 1;
SIG_VALTYPE_ 386 RFC_Hdr02_PersFiltWeightIndAzi : 1;
SIG_VALTYPE_ 386 RFC_Hdr02_PersFiltDspCurrAzi : 1;
SIG_VALTYPE_ 386 RFC_Hdr02_PersFiltDspMalIndElev : 1;
SIG_VALTYPE_ 386 RFC_Hdr02_PersFiltWeightIndElev : 1;
SIG_VALTYPE_ 386 RFC_Hdr02_PersFiltDspCurrElev : 1;
SIG_VALTYPE_ 386 RFC_Hdr02_PersMalStablePosAzi : 1;
SIG_VALTYPE_ 386 RFC_Hdr02_PersMalStablePosElev : 1;
SIG_VALTYPE_ 386 RFC_Hdr02_PersChDetPozAzi : 1;
SIG_VALTYPE_ 386 RFC_Hdr02_PersChDetNegAzi : 1;
SIG_VALTYPE_ 386 RFC_Hdr02_PersChDetPozElev : 1;
SIG_VALTYPE_ 386 RFC_Hdr02_PersChDetNegElev : 1;
SIG_VALTYPE_ 386 RFC_Hdr02_MntAziCur : 1;
SIG_VALTYPE_ 386 RFC_Hdr02_MntElevCur : 1;
SIG_VALTYPE_ 388 RFC_Hdr04_MntPosX : 1;
SIG_VALTYPE_ 388 RFC_Hdr04_MntPosY : 1;
SIG_VALTYPE_ 388 RFC_Hdr04_MntPosZ : 1;
SIG_VALTYPE_ 388 RFC_Hdr04_MntAziNom : 1;
SIG_VALTYPE_ 388 RFC_Hdr04_MntElevNom : 1;
SIG_VALTYPE_ 388 RFC_Hdr04_InitCov : 1;
